VERSION "AEE2010_R3_HS1_HS2_EPS_merge"

NS_ :

BS_:

BU_: UTIL__Traminator CMM___Motor_SG CDS___Fahrdynamikregelung BVA___Automatikgetriebe BSI___Kombiinstrument AR2S_StartStop ABS___Antiblockiersystem AVAS RITCS PASS_HCU2 BVN EBB PASS_VCU BSI AAS PASS_BSI FAMILLE_DSG BV CAPT_ALG CAPT_VOL CMM CSS FSE OUTIL_DIAG PROJ SBW SCDT SUSP UC_DIRA UC_FREIN ASR ARTIV PASS_BSM CMF HCU1 HCU2 ECR MCM Tester PSCM
; #############################################################################
; ############################### HS1 B0 #####################################
; #############################################################################

BO_ 1074 HS2_DAT_BSI_432: 8 BSI
 SG_ ENGINE_COUPLE_REQUEST : 1|2@0+ (1,0) [0|3] "" CAPT_ALG,BVN,ARTIV,ASR,AVAS
 # Description: Requests engine torque coupling or decoupling.
 SG_ STARTER_STOP_REQUEST : 2|1@0+ (1,0) [0|1] "" CAPT_ALG,BVN,ARTIV,ASR,AVAS
 # Description: Requests stopping the starter operation.
 SG_ WAKEUP_CH : 3|1@0+ (1,0) [0|1] "" CAPT_ALG,BVN,ARTIV,ASR,AVAS
 # Description: Triggers a wakeup on channel CH for advanced readiness.
 SG_ ANTICIPATION_ADC_WAKEUP : 4|1@0+ (1,0) [0|1] "" CAPT_ALG,BVN,ARTIV,ASR,AVAS
 # Description: Wakeup triggered by the ADC in anticipation mode.
 SG_ GEARBOX_STATE_WAKEUP : 5|1@0+ (1,0) [0|1] "" CAPT_ALG,BVN,ARTIV,ASR,AVAS
 # Description: Wakeup triggered by a gearbox state change.
 SG_ MAIN_WAKEUP : 7|2@0+ (1,0) [0|3] "" CAPT_ALG,BVN,ARTIV,ASR,AVAS
 # Description: Represents the main wakeup reason or source.
 SG_ PROCESS_COUNTER_4B_BSI_1 : 11|4@0+ (1,0) [0|15] "" CAPT_ALG,BVN,ARTIV,ASR,AVAS
 # Description: Process counter for BSI 1 data frame.
 SG_ SEV_DEMAND : 13|2@0+ (1,0) [0|3] "" CAPT_ALG,BVN,ARTIV,ASR,AVAS
 # Description: Demand for the SEV (Starter-Enabled Vehicle) function.
 SG_ FLEX_PREHEAT_WAKEUP : 16|1@0+ (1,0) [0|1] "" CAPT_ALG,BVN,ARTIV,ASR,AVAS
 # Description: Wakeup triggered by flex fuel preheating logic.
 SG_ PRE_PST_PPL_WAKEUP : 17|1@0+ (1,0) [0|1] "" CAPT_ALG,BVN,ARTIV,ASR,AVAS
 # Description: Wakeup requested for pre/post fuel supply checks.
 SG_ PST_PPL_WAKEUP : 18|1@0+ (1,0) [0|1] "" CAPT_ALG,BVN,ARTIV,ASR,AVAS
 # Description: Wakeup requested for PST (post start) or PPL (pump logic).
 SG_ SENSIBLE_CONSUMPTION : 19|1@0+ (1,0) [0|1] "" CAPT_ALG,BVN,ARTIV,ASR,AVAS
 # Description: Indicates a state of high energy consumption considered sensible.
 SG_ HADC_ENABLE_REQUEST : 20|1@0+ (1,0) [0|1] "" CAPT_ALG,BVN,ARTIV,ASR,AVAS
 # Description: Request to enable the Hill Assist or Descent Control system.
 SG_ ENGINE_PREPARATION_REQUEST : 21|1@0+ (1,0) [0|1] "" CAPT_ALG,BVN,ARTIV,ASR,AVAS
 # Description: Requests engine preparation or readiness mode.
 SG_ IMPULSE_START_REQUEST_BSI : 23|2@0+ (1,0) [0|3] "" CAPT_ALG,BVN,ARTIV,ASR,AVAS
 # Description: Impulse-based engine start request from the BSI.
 SG_ ADDED_FUEL_VOLUME : 31|8@0+ (0.5,0) [0|126.5] "L" CAPT_ALG,BVN,ARTIV,ASR,AVAS
 # Description: Volume of fuel added to the tank, in liters.
 SG_ CORRECT_HIGH_TIRE_PRESS_WAKEUP : 32|1@0+ (1,0) [0|1] "" CAPT_ALG,BVN,ARTIV,ASR,AVAS
 # Description: Wakeup triggered for high tire pressure correction.
 SG_ STT_PREPARATION_WAKEUP : 33|1@0+ (1,0) [0|1] "" CAPT_ALG,BVN,ARTIV,ASR,AVAS
 # Description: Wakeup triggered for start-stop preparation.
 SG_ FSE_STATE_WAKEUP : 34|1@0+ (1,0) [0|1] "" CAPT_ALG,BVN,ARTIV,ASR,AVAS
 # Description: Wakeup triggered by the FSE (Fuel System Electronics) state.
 SG_ HEADLAMP_REQUEST : 35|1@0+ (1,0) [0|1] "" CAPT_ALG,BVN,ARTIV,ASR,AVAS
 # Description: Request for headlamp alignment or activation from the BSI.
 SG_ OIL_MEAS_WAKEUP : 36|1@0+ (1,0) [0|1] "" CAPT_ALG,BVN,ARTIV,ASR,AVAS
 # Description: Wakeup triggered for an oil measurement routine.
 SG_ OVERLOAD_VEHICLE_WAKEUP : 37|1@0+ (1,0) [0|1] "" CAPT_ALG,BVN,ARTIV,ASR,AVAS
 # Description: Indicates wakeup from an overload or high-load vehicle condition.
 SG_ ENGINE_PREPARE_DEM_WAKEUP : 38|1@0+ (1,0) [0|1] "" CAPT_ALG,BVN,ARTIV,ASR,AVAS
 # Description: Wakeup triggered to prepare the engine for immediate start.
 SG_ VVH_UCFREIN_WAKEUP : 39|1@0+ (1,0) [0|1] "" CAPT_ALG,BVN,ARTIV,ASR,AVAS
 # Description: Wakeup triggered for the brake control logic or VVH signals.
 SG_ ADDED_FUEL_VOLUME_COUNTER : 42|3@0+ (1,0) [0|6] "" CAPT_ALG,BVN,ARTIV,ASR,AVAS
 # Description: Counter incremented each time fuel is added.
 SG_ START_DEMAND_STATUS : 43|1@0+ (1,0) [0|1] "" CAPT_ALG,BVN,ARTIV,ASR,AVAS
 # Description: Indicates if an engine start is demanded by the system.
 SG_ UCAPS_PREHEAT_WAKEUP : 45|1@0+ (1,0) [0|1] "" CAPT_ALG,BVN,ARTIV,ASR,AVAS
 # Description: Wakeup triggered by ultracapacitor preheating logic.
 SG_ POST_ENGINE_VENTIL_WAKEUP : 46|1@0+ (1,0) [0|1] "" CAPT_ALG,BVN,ARTIV,ASR,AVAS
 # Description: Wakeup triggered to continue ventilation after engine off.
 SG_ GEP_PREPARATION_WAKEUP : 47|1@0+ (1,0) [0|1] "" CAPT_ALG,BVN,ARTIV,ASR,AVAS
 # Description: Wakeup for GEP (Gas Exhaust Purge) or related function.
 SG_ SEV_MAIN_STATE : 49|2@0+ (1,0) [0|3] "" CAPT_ALG,BVN,ARTIV,ASR,AVAS
 # Description: Main state for the SEV logic or function.
 SG_ CTX_JDD : 55|6@0+ (1,0) [0|0] "" CAPT_ALG,BVN,ARTIV,ASR,AVAS
 # Description: Context flags for JDD (jour du diagnostic or day-of-diagnostic).
 SG_ GENERIC_START_INTENT : 57|2@0+ (1,0) [0|3] "" CAPT_ALG,BVN,ARTIV,ASR,AVAS
 # Description: Generic indication of an intent to start the engine or system.
 SG_ ECO_PUSH_PWT : 58|1@0+ (1,0) [0|1] "" CAPT_ALG,BVN,ARTIV,ASR,AVAS
 # Description: Indicates a push for eco or powertrain optimization features.
 SG_ POWER_LATCH_HYB_WAKEUP : 59|1@0+ (1,0) [0|1] "" CAPT_ALG,BVN,ARTIV,ASR,AVAS
 # Description: Wakeup triggered by a power latch or lock condition in a hybrid system.
 SG_ ELECTRICAL_NETWORK_STATE : 63|4@0+ (1,0) [0|15] "" CAPT_ALG,BVN,ARTIV,ASR,AVAS
 # Description: Current state of the electrical network within the vehicle.

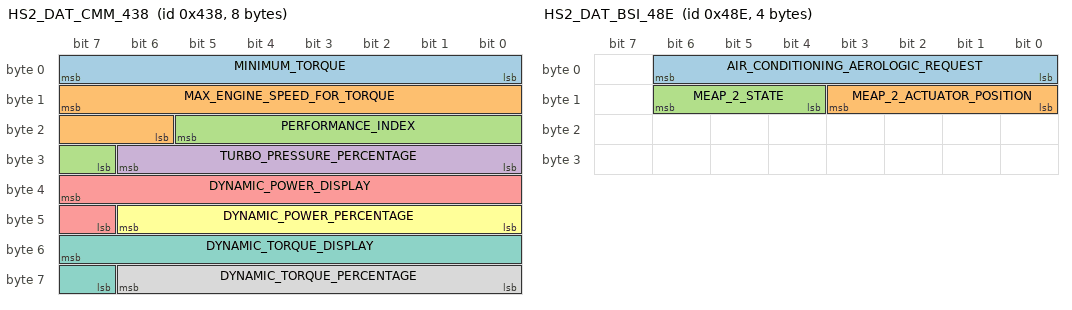
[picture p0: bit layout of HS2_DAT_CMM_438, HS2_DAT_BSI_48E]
BO_ 1080 HS2_DAT_CMM_438: 8 CMM
 SG_ MINIMUM_TORQUE : 7|8@0+ (2,-100) [-100|408] "N.m" RITCS,BV,BSI
 # Description: Minimum permissible engine or motor torque at this time.
 SG_ MAX_ENGINE_SPEED_FOR_TORQUE : 15|10@0+ (10,0) [0|6000] "tr/min" RITCS,BV,BSI
 # Description: Engine speed above which torque might be limited, in rpm.
 SG_ PERFORMANCE_INDEX : 21|7@0+ (1,0) [0|100] "%" RITCS,BV,BSI
 # Description: Performance index summarizing the available power or torque.
 SG_ TURBO_PRESSURE_PERCENTAGE : 30|7@0+ (1,0) [0|100] "%" RITCS,BV,BSI
 # Description: Percentage of the turbo or boost pressure being used.
 SG_ DYNAMIC_POWER_DISPLAY : 39|9@0+ (1,0) [0|400] "ch" RITCS,BV,BSI
 # Description: Display value for dynamic engine power in horsepower.
 SG_ DYNAMIC_POWER_PERCENTAGE : 46|7@0+ (1,0) [0|100] "%" RITCS,BV,BSI
 # Description: Percentage of the dynamic power currently delivered.
 SG_ DYNAMIC_TORQUE_DISPLAY : 55|9@0+ (1,0) [0|500] "N.m" RITCS,BV,BSI
 # Description: Display value for dynamic engine torque in Newton-meters.
 SG_ DYNAMIC_TORQUE_PERCENTAGE : 62|7@0+ (1,0) [0|100] "%" RITCS,BV,BSI
 # Description: Percentage of the dynamic torque relative to maximum output.

BO_ 1106 HS2_DAT_MDD_CMD_452: 6 BSI
 SG_ LONGITUDINAL_REGULATION_TYPE : 1|2@0+ (1,0) [0|3] "" CMF,ARTIV,CMM,UC_FREIN
 # Description: Type of longitudinal regulation (Cruise, ACC, etc.).
 SG_ TURN_SIGNALS_STATE : 5|2@0+ (1,0) [0|3] "" CMF,ARTIV,CMM,UC_FREIN
 # Description: Current state of the left/right turn signals.
 SG_ FRONT_WIPER_STATE : 7|2@0+ (1,0) [0|3] "" CMF,ARTIV,CMM,UC_FREIN
 # Description: Current state of the front wiper system.
 SG_ SPEED_LIMIT_CONSIGN : 15|8@0+ (1,0) [0|255] "km/h" CMF,ARTIV,CMM,UC_FREIN
 # Description: Speed limit value or setpoint for the vehicle.
 SG_ RVV_LVV_CHECKSUM : 17|2@0+ (1,0) [0|3] "" CMF,ARTIV,CMM,UC_FREIN
 # Description: 2-bit checksum for the RVV/LVV data consistency.
 SG_ BSI_FREIN_ONLY_REQUEST : 18|1@0+ (1,0) [0|1] "" CMF,ARTIV,CMM,UC_FREIN
 # Description: Indicates if the BSI is requesting brake-only actuation.
 SG_ LVV_ACTIVATION_REQUEST : 22|1@0+ (1,0) [0|1] "" CMF,ARTIV,CMM,UC_FREIN
 # Description: Request to activate LVV (low-voltage valve or logic).
 SG_ RVV_ACC_ACTIVATION_REQUEST : 23|1@0+ (1,0) [0|1] "" CMF,ARTIV,CMM,UC_FREIN
 # Description: Request to activate RVV (regulation of variable valve) with ACC.
 SG_ ARC_SENSITIVITY_HABIT : 26|3@0+ (1,0) [0|7] "" CMF,ARTIV,CMM,UC_FREIN
 # Description: Sensitivity setting for ARC from the user habit or preference.
 SG_ ARC_ACTIVATION_REQUEST_HABIT : 27|1@0+ (1,0) [0|1] "" CMF,ARTIV,CMM,UC_FREIN
 # Description: Requests activation of ARC based on user preference.
 SG_ BSI2_COUNTER : 31|4@0+ (1,0) [0|15] "" CMF,ARTIV,CMM,UC_FREIN
 # Description: Transmission counter for the second set of BSI signals.
 SG_ FRONT_WASHER_STATE : 32|1@0+ (1,0) [0|1] "" CMF,ARTIV,CMM,UC_FREIN
 # Description: Indicates if the front washer system is active.
 SG_ FA_ACTIVATION_REQUEST_HABIT : 33|1@0+ (1,0) [0|1] "" CMF,ARTIV,CMM,UC_FREIN
 # Description: Requests activation of the forward assist function by the user.
 SG_ TIME_GAP_CONSIGN : 39|6@0+ (0.1,0) [0|6.1] "s" CMF,ARTIV,CMM,UC_FREIN
 # Description: Time gap setpoint for adaptive cruise or spacing.
 SG_ CHECKSUM_FRAME_4B_452 : 43|4@0+ (1,0) [0|15] "" CMF,ARTIV,CMM,UC_FREIN
 # Description: 4-bit checksum for frame 452 data.
 SG_ GO_ACC_REQUEST : 45|1@0+ (1,0) [0|1] "" CMF,ARTIV,CMM,UC_FREIN
 # Description: Indicates a user or system request to resume ACC from a stop.
 SG_ ACC_PROGRAM : 47|2@0+ (1,0) [0|3] "" CMF,ARTIV,CMM,UC_FREIN
 # Description: Program or mode selection for ACC.

BO_ 1160 HS2_BGE_DAT_CMM_488: 8 PASS_BSI
 SG_ ENGINE_COOLANT_TEMPERATURE : 7|8@0+ (1,-40) [-40|214] "Degré C" PASS_HCU2,RITCS,UC_FREIN,CSS,BV,BSI,HCU1
 # Description: Temperature of the engine coolant in degrees Celsius.
 SG_ FUEL_CONSUMPTION_VOLUME : 15|8@0+ (80,0) [0|20400] "mm3" PASS_HCU2,RITCS,UC_FREIN,CSS,BV,BSI,HCU1
 # Description: Volume of fuel consumed, in mm³, since last reset or measurement.
 SG_ IDLE_REGULATION_SETPOINT : 23|8@0+ (8,0) [0|2024] "tr/min" PASS_HCU2,RITCS,UC_FREIN,CSS,BV,BSI,HCU1
 # Description: Idle engine speed setpoint in rpm.
 SG_ START_IN_PROGRESS : 24|1@0+ (1,0) [0|0] "" PASS_HCU2,RITCS,UC_FREIN,CSS,BV,BSI,HCU1
 # Description: Indicates if an engine start is currently in progress.
 SG_ PREHEAT_LAMP_REQUEST : 25|1@0+ (1,0) [0|0] "" PASS_HCU2,RITCS,UC_FREIN,CSS,BV,BSI,HCU1
 # Description: Requests illumination of the glow plug (preheat) indicator lamp.
 SG_ MIL_LAMP_REQUEST : 26|1@0+ (1,0) [0|0] "" PASS_HCU2,RITCS,UC_FREIN,CSS,BV,BSI,HCU1
 # Description: Requests illumination of the MIL (Malfunction Indicator Lamp).
 SG_ HIGH_COOLANT_TEMPERATURE_ALERT : 27|1@0+ (1,0) [0|0] "" PASS_HCU2,RITCS,UC_FREIN,CSS,BV,BSI,HCU1
 # Description: Indicates an alert for excessively high coolant temperature.
 SG_ LOW_ADDITIVE_LEVEL_ALERT : 28|1@0+ (1,0) [0|0] "" PASS_HCU2,RITCS,UC_FREIN,CSS,BV,BSI,HCU1
 # Description: Signals a low additive (e.g., DEF fluid) level condition.
 SG_ PVRE_MILEAGE_LAMP_REQUEST : 28|1@0+ (1,0) [0|0] "" PASS_HCU2,RITCS,UC_FREIN,CSS,BV,BSI,HCU1
 # Description: Requests illumination of the mileage lamp when nearing fill requirement.
 SG_ RVV_LVV_FAULT : 30|1@0+ (1,0) [0|0] "" PASS_HCU2,RITCS,UC_FREIN,CSS,BV,BSI,HCU1
 # Description: Indicates a detected fault in the RVV/LVV system.
 SG_ COMBUSTION_RATES : 31|1@0+ (1,0) [0|0] "" PASS_HCU2,RITCS,UC_FREIN,CSS,BV,BSI,HCU1
 # Description: Monitors or indicates the combustion rates or events per cycle.
 SG_ SECURE_AC_COUPLING : 32|1@0+ (1,0) [0|0] "" PASS_HCU2,RITCS,UC_FREIN,CSS,BV,BSI,HCU1
 # Description: Indicates the AC clutch or coupling is secured or locked for safety.
 SG_ CLIMATE_CONTROL_MANAGEMENT_STATE : 34|2@0+ (1,0) [0|0] "" PASS_HCU2,RITCS,UC_FREIN,CSS,BV,BSI,HCU1
 # Description: State variable for internal climate control management.
 SG_ SERVICE_STOP_LAMP_REQUEST : 36|2@0+ (1,0) [0|0] "" PASS_HCU2,RITCS,UC_FREIN,CSS,BV,BSI,HCU1
 # Description: Requests the service stop lamp or message to be displayed.
 SG_ GLOW_PLUG_PREHEAT_PREP : 37|1@0+ (1,0) [0|0] "" PASS_HCU2,RITCS,UC_FREIN,CSS,BV,BSI,HCU1
 # Description: Indicates preparation phase of the glow plug preheat cycle.
 SG_ FUEL_CONSUMPTION_INFO_TYPE : 37|1@0+ (1,0) [0|0] "" PASS_HCU2,RITCS,UC_FREIN,CSS,BV,BSI,HCU1
 # Description: Type or mode of fuel consumption info being reported.
 SG_ FAP_CLOGGING_RISK : 38|1@0+ (1,0) [0|0] "" PASS_HCU2,RITCS,UC_FREIN,CSS,BV,BSI,HCU1
 # Description: Risk level or indicator for clogged particulate filter.
 SG_ BVA_PRESSURE_OVERRIDE : 39|1@0+ (1,0) [0|0] "" PASS_HCU2,RITCS,UC_FREIN,CSS,BV,BSI,HCU1
 # Description: Indicates an override of gearbox pressure in the automatic transmission.
 SG_ ENGINE_OIL_TEMP : 47|8@0+ (1,-40) [-40|214] "Degrees C" PASS_HCU2,RITCS,UC_FREIN,CSS,BV,BSI,HCU1
SG_ COOLANT_PRESSURE : 55|8@0+ (25,0) [100|3100] "kPa" PASS_HCU2,RITCS,UC_FREIN,CSS,BV,BSI,HCU1
# Description: Represents the coolant system pressure in kilopascals (kPa). Typically measured by a pressure sensor.

SG_ ENGINE_AIR_TEMPERATURE : 63|8@0+ (1,-40) [-40|214] "Degree C" PASS_HCU2,RITCS,UC_FREIN,CSS,BV,BSI,HCU1
# Description: Represents the intake air temperature of the engine in degrees Celsius.

BO_ 1166 HS2_DAT_BSI_48E: 4 BSI
 SG_ AIR_CONDITIONING_AEROLOGIC_REQUEST : 6|7@0+ (1,0) [0|100] "%" CMM
# Description: Represents an aerodynamic-related request for the air conditioning system.

 SG_ MEAP_2_ACTUATOR_POSITION : 11|4@0+ (1,0) [0|0] "" CMM
# Description: Represents the commanded position of the second MEAP actuator (Manifold/Electronic Actuator).

 SG_ MEAP_2_STATE : 14|3@0+ (1,0) [0|0] "" CMM
# Description: Represents the current operating state of the second MEAP actuator.

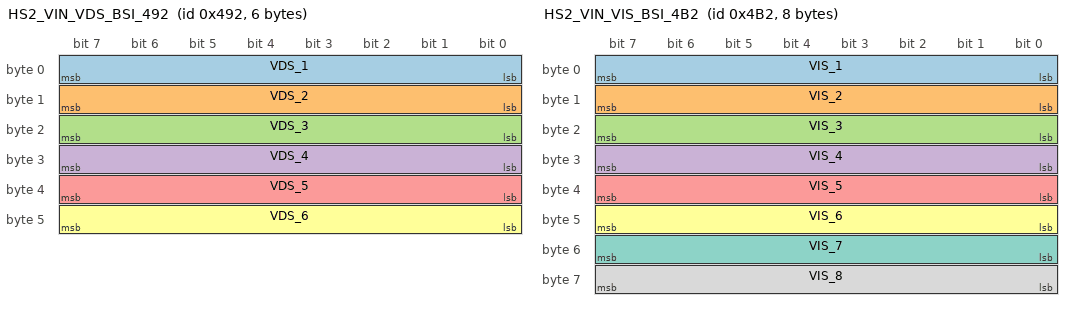
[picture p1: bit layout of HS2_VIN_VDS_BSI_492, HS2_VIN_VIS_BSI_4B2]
BO_ 1170 HS2_VIN_VDS_BSI_492: 6 BSI
 SG_ VDS_1 : 7|8@0+ (1,0) [0|0] "" BVN,CMM
# Description: First character of the Vehicle Descriptor Section (VDS).

 SG_ VDS_2 : 15|8@0+ (1,0) [0|0] "" BVN,CMM
# Description: Second character of the Vehicle Descriptor Section (VDS).

 SG_ VDS_3 : 23|8@0+ (1,0) [0|0] "" BVN,CMM
# Description: Third character of the Vehicle Descriptor Section (VDS).

 SG_ VDS_4 : 31|8@0+ (1,0) [0|0] "" BVN,CMM
# Description: Fourth character of the Vehicle Descriptor Section (VDS).

 SG_ VDS_5 : 39|8@0+ (1,0) [0|0] "" BVN,CMM
# Description: Fifth character of the Vehicle Descriptor Section (VDS).

 SG_ VDS_6 : 47|8@0+ (1,0) [0|0] "" BVN,CMM
# Description: Sixth character of the Vehicle Descriptor Section (VDS).

BO_ 1202 HS2_VIN_VIS_BSI_4B2: 8 BSI
 SG_ VIS_1 : 7|8@0+ (1,0) [0|0] "" CMM,BVN
# Description: First character of the Vehicle Identification Section (VIS).

 SG_ VIS_2 : 15|8@0+ (1,0) [0|0] "" CMM,BVN
# Description: Second character of the Vehicle Identification Section (VIS).

 SG_ VIS_3 : 23|8@0+ (1,0) [0|0] "" CMM,BVN
# Description: Third character of the Vehicle Identification Section (VIS).

 SG_ VIS_4 : 31|8@0+ (1,0) [0|0] "" CMM,BVN
# Description: Fourth character of the Vehicle Identification Section (VIS).

 SG_ VIS_5 : 39|8@0+ (1,0) [0|0] "" CMM,BVN
# Description: Fifth character of the Vehicle Identification Section (VIS).

 SG_ VIS_6 : 47|8@0+ (1,0) [0|0] "" CMM,BVN
# Description: Sixth character of the Vehicle Identification Section (VIS).

 SG_ VIS_7 : 55|8@0+ (1,0) [0|0] "" CMM,BVN
# Description: Seventh character of the Vehicle Identification Section (VIS).

 SG_ VIS_8 : 63|8@0+ (1,0) [0|0] "" CMM,BVN
# Description: Eighth character of the Vehicle Identification Section (VIS).

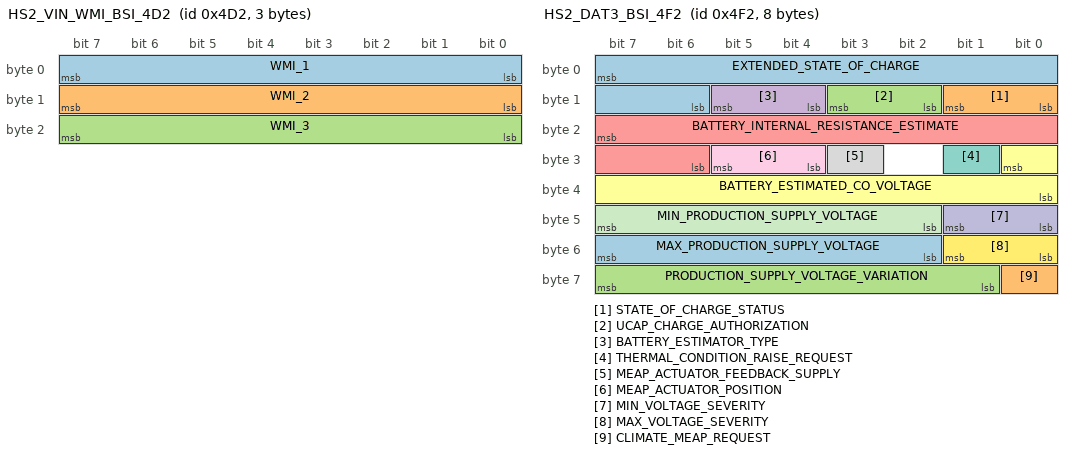
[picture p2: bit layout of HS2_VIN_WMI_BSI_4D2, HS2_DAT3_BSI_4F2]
BO_ 1234 HS2_VIN_WMI_BSI_4D2: 3 BSI
 SG_ WMI_1 : 7|8@0+ (1,0) [0|0] "" BVN,CMM
# Description: First character of the World Manufacturer Identifier (WMI).

 SG_ WMI_2 : 15|8@0+ (1,0) [0|0] "" BVN,CMM
# Description: Second character of the World Manufacturer Identifier (WMI).

 SG_ WMI_3 : 23|8@0+ (1,0) [0|0] "" BVN,CMM
# Description: Third character of the World Manufacturer Identifier (WMI).

BO_ 1261 HS2_DAT_ESP_4ED: 5 UC_FREIN
 SG_ FAULT_OBD_ESP_FRONT_PRESSURE_SENSOR : 0|1@0+ (1,0) [0|0] "" HCU2
# Description: Indicates a fault status for the front pressure sensor used by the ESP system.

 SG_ FAULT_OBD_ESP_TRIPLE_SENSOR_COMM : 8|1@0+ (1,0) [0|0] "" HCU2
# Description: Indicates a communication fault with triple sensors in the ESP system.

 SG_ FAULT_OBD_ESP_CMM_COMM : 9|1@0+ (1,0) [0|0] "" HCU2
# Description: Indicates a communication fault with the CMM in the ESP system.

 SG_ FAULT_OBD_ESP_PTMU_COMM : 10|1@0+ (1,0) [0|0] "" HCU2
# Description: Indicates a communication fault with the PTMU in the ESP system.

 SG_ FAULT_OBD_ESP_VOLUME_SENSOR : 11|1@0+ (1,0) [0|0] "" HCU2
# Description: Indicates a fault with the volume sensor for the ESP system.

 SG_ FAULT_OBD_ESP_VALVE_ESP : 12|1@0+ (1,0) [0|0] "" HCU2
# Description: Indicates a fault with the ESP valve.

 SG_ FAULT_OBD_ESP_PUMP_ESP : 13|1@0+ (1,0) [0|0] "" HCU2
# Description: Indicates a fault with the ESP pump.

 SG_ FAULT_OBD_ESP_MASTERVAC_SENSOR : 14|1@0+ (1,0) [0|0] "" HCU2
# Description: Indicates a fault with the mastervac sensor in the ESP system.

 SG_ FAULT_OBD_ESP_VACUUM_PUMP_SUPERVISION : 15|1@0+ (1,0) [0|0] "" HCU2
# Description: Indicates a fault related to vacuum pump supervision in the ESP system.

 SG_ FAULT_OBD_ESP_CVR_AVG : 16|1@0+ (1,0) [0|0] "" HCU2
# Description: Indicates a fault with the average CVR sensor (front-left corner) in the ESP system.

 SG_ FAULT_OBD_ESP_CVR_AVD : 17|1@0+ (1,0) [0|0] "" HCU2
# Description: Indicates a fault with the CVR sensor (front-right corner) in the ESP system.

 SG_ FAULT_OBD_ESP_CVR_ARG : 18|1@0+ (1,0) [0|0] "" HCU2
# Description: Indicates a fault with the CVR sensor (rear-left corner) in the ESP system.

 SG_ FAULT_OBD_ESP_CVR_ARD : 19|1@0+ (1,0) [0|0] "" HCU2
# Description: Indicates a fault with the CVR sensor (rear-right corner) in the ESP system.

 SG_ FAULT_OBD_ESP_WHEEL_SPEED_SENSOR : 20|1@0+ (1,0) [0|0] "" HCU2
# Description: Indicates a fault in a wheel speed sensor in the ESP system.

 SG_ FAULT_OBD_ESP_BRAKE_CONTACT : 21|1@0+ (1,0) [0|0] "" HCU2
# Description: Indicates a fault with the brake contact signal in the ESP system.

 SG_ FAULT_OBD_ESP_CAN_IS : 22|1@0+ (1,0) [0|0] "" HCU2
# Description: Indicates a CAN IS bus fault for the ESP system.

 SG_ FAULT_OBD_ESP_CAN_LAS : 23|1@0+ (1,0) [0|0] "" HCU2
# Description: Indicates a CAN LAS bus fault for the ESP system.

 SG_ FAULT_OBD_ESP_INTERNAL_ERROR : 24|1@0+ (1,0) [0|0] "" HCU2
# Description: Indicates an internal error in the ESP system.

 SG_ FAULT_OBD_ESP_OVERVOLTAGE : 25|1@0+ (1,0) [0|0] "" HCU2
# Description: Indicates an overvoltage condition in the ESP system.

 SG_ FAULT_OBD_ESP_TELECODING : 26|1@0+ (1,0) [0|0] "" HCU2
# Description: Indicates a telecoding/configuration issue in the ESP system.

 SG_ FAULT_OBD_ESP_MASTER_CYLINDER_SENSOR : 27|1@0+ (1,0) [0|0] "" HCU2
# Description: Indicates a fault with the master cylinder sensor in the ESP system.

 SG_ YAW_RATE_SENSOR_FAULT_RB : 28|1@0+ (1,0) [0|0] "" HCU2
# Description: Indicates a fault in the yaw rate sensor (RB) used by the ESP system.

 SG_ LATERAL_ACCELERATION_SENSOR_FAULT_RB : 29|1@0+ (1,0) [0|0] "" HCU2
# Description: Indicates a fault in the lateral acceleration sensor (RB) for the ESP system.

 SG_ FAULT_OBD_ESP_INERTIAL_SENSOR : 30|1@0+ (1,0) [0|0] "" HCU2
# Description: Indicates a fault in the inertial sensor for the ESP system.

 SG_ FAULT_OBD_ESP_STEERING_WHEEL_SENSOR : 31|1@0+ (1,0) [0|0] "" HCU2
# Description: Indicates a fault in the steering wheel angle sensor for the ESP system.

 SG_ DIAG_ACTIVATION_VACUUM_FAULT : 32|1@0+ (1,0) [0|0] "" HCU2
# Description: Indicates whether vacuum fault diagnosis is active.

 SG_ VACUUM_FAULT_DIAGNOSIS : 33|1@0+ (1,0) [0|0] "" HCU2
# Description: Indicates a detected vacuum fault condition.

BO_ 1266 HS2_DAT3_BSI_4F2: 8 BSI
 SG_ EXTENDED_STATE_OF_CHARGE : 7|10@0+ (0.1,0) [0|100] "%" PASS_HCU2,RITCS,CMM
# Description: Represents the state of charge of the battery in percent, with extended precision.

 SG_ STATE_OF_CHARGE_STATUS : 9|2@0+ (1,0) [0|0] "" PASS_HCU2,RITCS,CMM
# Description: Represents the status level or mode for the battery state of charge.

 SG_ UCAP_CHARGE_AUTHORIZATION : 11|2@0+ (1,0) [0|0] "" PASS_HCU2,RITCS,CMM
# Description: Indicates if ultracapacitor charging is authorized.

 SG_ BATTERY_ESTIMATOR_TYPE : 13|2@0+ (1,0) [0|0] "" PASS_HCU2,RITCS,CMM
# Description: Defines which battery estimator algorithm or type is in use.

 SG_ BATTERY_INTERNAL_RESISTANCE_ESTIMATE : 23|10@0+ (0.01,0) [0|10] "mOhm" PASS_HCU2,RITCS,CMM
# Description: Represents the estimated internal resistance of the battery in milliohms.

 SG_ BATTERY_ESTIMATED_CO_VOLTAGE : 24|9@0+ (0.01,11) [11|14] "V" PASS_HCU2,RITCS,CMM
# Description: Represents the estimated battery voltage offset in volts.

 SG_ THERMAL_CONDITION_RAISE_REQUEST : 25|1@0+ (1,0) [0|0] "" PASS_HCU2,RITCS,CMM
# Description: Requests a thermal condition raise for the engine (e.g., to optimize temperature).

 SG_ MEAP_ACTUATOR_FEEDBACK_SUPPLY : 27|1@0+ (1,0) [0|0] "" PASS_HCU2,RITCS,CMM
# Description: Indicates the supply status used for the MEAP actuator feedback.

 SG_ MEAP_ACTUATOR_POSITION : 29|2@0+ (1,0) [0|0] "" PASS_HCU2,RITCS,CMM
# Description: Represents the position of the MEAP actuator.

 SG_ MIN_VOLTAGE_SEVERITY : 41|2@0+ (1,0) [0|0] "" PASS_HCU2,RITCS,CMM
# Description: Indicates the severity level for the minimum voltage threshold condition.

 SG_ MIN_PRODUCTION_SUPPLY_VOLTAGE : 47|6@0+ (0.1,10.6) [10.6|16] "V" PASS_HCU2,RITCS,CMM
# Description: Represents the minimum supply voltage for onboard electric production.

 SG_ MAX_VOLTAGE_SEVERITY : 49|2@0+ (1,0) [0|0] "" PASS_HCU2,RITCS,CMM
# Description: Indicates the severity level for the maximum voltage threshold condition.

 SG_ MAX_PRODUCTION_SUPPLY_VOLTAGE : 55|6@0+ (0.1,10.6) [10.6|16] "V" PASS_HCU2,RITCS,CMM
# Description: Represents the maximum supply voltage for onboard electric production.

 SG_ CLIMATE_MEAP_REQUEST : 56|1@0+ (1,0) [0|0] "" PASS_HCU2,RITCS,CMM
# Description: Indicates a request to adjust MEAP for climate control.

 SG_ PRODUCTION_SUPPLY_VOLTAGE_VARIATION : 63|7@0+ (0.1,0) [0.1|10] "V/s" PASS_HCU2,RITCS,CMM
# Description: Represents the variation rate of the supply voltage in volts per second.

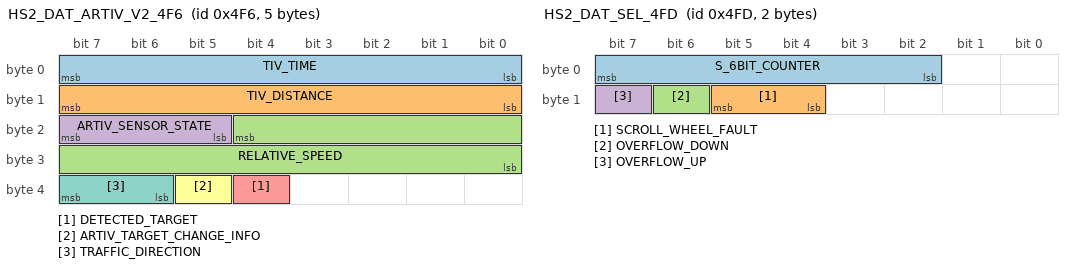
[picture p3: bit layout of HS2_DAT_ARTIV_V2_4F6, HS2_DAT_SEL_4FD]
BO_ 1270 HS2_DAT_ARTIV_V2_4F6: 5 ARTIV
 SG_ TIV_TIME : 7|8@0+ (0.1,0) [0|25.4] "s" RITCS,BSI,CMF
# Description: Represents the Time to Impact Value (TIV) in seconds.

 SG_ TIV_DISTANCE : 15|8@0+ (1,0) [0|253] "m" RITCS,BSI,CMF
# Description: Represents the distance to the target object used for ARTIV, in meters.

 SG_ RELATIVE_SPEED : 20|13@0+ (0.02,-70) [-70|70] "m/s" RITCS,BSI,CMF
# Description: Represents the relative speed between the host vehicle and a target in meters per second.

 SG_ ARTIV_SENSOR_STATE : 23|3@0+ (1,0) [0|0] "" RITCS,BSI,CMF
# Description: Represents the operating state of the ARTIV sensor module.

 SG_ DETECTED_TARGET : 36|1@0+ (1,0) [0|0] "" RITCS,BSI,CMF
# Description: Indicates whether a target has been detected.

 SG_ ARTIV_TARGET_CHANGE_INFO : 37|1@0+ (1,0) [0|0] "" RITCS,BSI,CMF
# Description: Indicates a change or update in the detected target data.

 SG_ TRAFFIC_DIRECTION : 39|2@0+ (1,0) [0|0] "" RITCS,BSI,CMF
# Description: Indicates the direction of traffic or lane movement for ARTIV.

BO_ 1277 HS2_DAT_SEL_4FD: 2 MCM
 SG_ S_6BIT_COUNTER : 7|6@0- (1,0) [-32|31] "" UC_FREIN
# Description: 6-bit counter for a selection or incremental count function.

 SG_ SCROLL_WHEEL_FAULT : 13|2@0+ (1,0) [0|0] "" UC_FREIN
# Description: Indicates a fault in the scroll wheel or rotary switch mechanism.

 SG_ OVERFLOW_DOWN : 14|1@0+ (1,0) [0|0] "" UC_FREIN
# Description: Indicates a downward overflow condition in the scroll or selection function.

 SG_ OVERFLOW_UP : 15|1@0+ (1,0) [0|0] "" UC_FREIN
# Description: Indicates an upward overflow condition in the scroll or selection function.

BO_ 1294 HS2_DAT_CLIM_50E: 8 BSI
 SG_ COMPRESSOR_CLUTCH_STATE : 1|1@0+ (1,0) [0|1] "" PASS_HCU2,RITCS,UC_FREIN,SCDT,CMM,BV
# Description: Represents the engaged or disengaged state of the air conditioning compressor clutch.

 SG_ AUTHORIZED_ENGINE_STOP_IN_CABIN : 2|1@0+ (1,0) [0|1] "" PASS_HCU2,RITCS,UC_FREIN,SCDT,CMM,BV
# Description: Indicates whether engine stop is authorized for cabin conditions (e.g. climate control).

 SG_ HABITACLE_ID_FAULT : 2|1@0+ (1,0) [0|1] "" PASS_HCU2,RITCS,UC_FREIN,SCDT,CMM,BV
# Description: Indicates a fault in the cabin identification or detection system.

 SG_ MIN_GPL : 3|1@0+ (1,0) [0|1] "" PASS_HCU2,RITCS,UC_FREIN,SCDT,CMM,BV
# Description: Represents a minimum GPL (liquefied petroleum gas) threshold condition if applicable.

 SG_ CONS_RVV_LVV_CHECKSUM : 5|2@0+ (1,0) [0|3] "" PASS_HCU2,RITCS,UC_FREIN,SCDT,CMM,BV
# Description: Checksum to secure the RVV or LVV speed request.

 SG_ CLIMATE_FAN_CONTROL_REQUEST : 13|6@0+ (2,0) [0|110] "%" PASS_HCU2,RITCS,UC_FREIN,SCDT,CMM,BV
# Description: Represents the climate system fan control request as a percentage.

 SG_ FAN_REQUEST_COMMAND : 15|2@0+ (1,0) [0|3] "" PASS_HCU2,RITCS,UC_FREIN,SCDT,CMM,BV
# Description: Represents a direct fan speed command or setting.

 SG_ GLOW_PLUGS_FORCING : 17|1@0+ (1,0) [0|1] "" PASS_HCU2,RITCS,UC_FREIN,SCDT,CMM,BV
# Description: Forces glow plugs to activate, typically to increase engine load for certain conditions (e.g. DPF regeneration).

 SG_ LOAD_SHEDDING_LEVEL : 19|1@0+ (1,0) [0|1] "" PASS_HCU2,RITCS,UC_FREIN,SCDT,CMM,BV
# Description: Indicates the load shedding level for major electrical consumers.

 SG_ RESTART_REQUEST_CABIN : 23|1@0+ (1,0) [0|1] "" PASS_HCU2,RITCS,UC_FREIN,SCDT,CMM,BV
# Description: Signals a request to restart the engine from cabin conditions (climate demands, etc.).

 SG_ REQUEST_ENGINE_RESTART_HABITACLE : 23|2@0+ (1,0) [0|3] "" PASS_HCU2,RITCS,UC_FREIN,SCDT,CMM,BV
# Description: Detailed request for engine restart from the cabin environment.

 SG_ PRESSURE_CONDENSER : 26|2@0+ (1,0) [0|3] "" PASS_HCU2,RITCS,UC_FREIN,SCDT,CMM,BV
# Description: Represents the condenser pressure state for the AC system.

 SG_ ENGINE_STOP_INHIBIT_HABITACLE : 29|2@0+ (1,0) [0|3] "" PASS_HCU2,RITCS,UC_FREIN,SCDT,CMM,BV
# Description: Indicates conditions inhibiting engine stop due to cabin constraints.

 SG_ HABITACLE_REQUEST_SIGNAL : 31|1@0+ (1,0) [0|1] "" PASS_HCU2,RITCS,UC_FREIN,SCDT,CMM,BV
# Description: Represents a cabin request for additional resources or engine operation.

 SG_ MECHANICAL_POWER_CONSUMPTION_CLIMATE : 39|8@0+ (25,0) [0|6350] "W" PASS_HCU2,RITCS,UC_FREIN,SCDT,CMM,BV
# Description: Indicates the mechanical power drawn by the climate compressor in watts.

 SG_ INCREASED_IDLE_SPEED_REQUEST : 47|8@0+ (8,0) [0|2032] "tr/min" PASS_HCU2,RITCS,UC_FREIN,SCDT,CMM,BV
# Description: Represents a requested higher idle speed for climate or other demands, in revolutions per minute.

 SG_ SPEED_LIMIT_REQUEST : 55|8@0+ (1,0) [0|255] "km/h" PASS_HCU2,RITCS,UC_FREIN,SCDT,CMM,BV
# Description: Represents a requested speed limit for the vehicle in km/h.

 SG_ BSI_FRAME_COUNTER : 59|4@0+ (1,0) [0|15] "" PASS_HCU2,RITCS,UC_FREIN,SCDT,CMM,BV
# Description: Frame counter used for data consistency checks in BSI communications.

 SG_ LVV_ACTIVATION_REQUEST : 60|1@0+ (1,0) [0|1] "" PASS_HCU2,RITCS,UC_FREIN,SCDT,CMM,BV
# Description: Indicates a request to activate the Low-Speed Vehicle (LVV) function.

 SG_ LONGITUDINAL_REGULATION_TYPE : 62|2@0+ (1,0) [0|3] "" PASS_HCU2,RITCS,UC_FREIN,SCDT,CMM,BV
# Description: Defines whether the vehicle is in LVV, RVV, ACC, or no longitudinal regulation mode.

 SG_ RVV_ACC_ACTIVATION_REQUEST : 63|1@0+ (1,0) [0|1] "" PASS_HCU2,RITCS,UC_FREIN,SCDT,CMM,BV
# Description: Indicates a request to activate the RVV or ACC function.

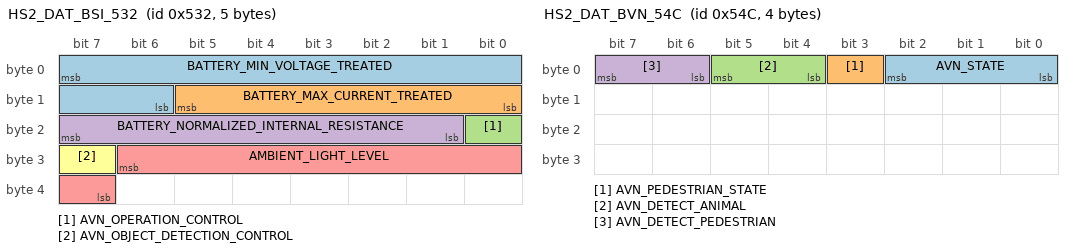
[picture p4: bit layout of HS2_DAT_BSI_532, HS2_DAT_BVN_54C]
BO_ 1330 HS2_DAT_BSI_532: 5 BSI
 SG_ BATTERY_MIN_VOLTAGE_TREATED : 7|10@0+ (0.01,3) [3|13] "V" PASS_HCU2,CMM,BVN
# Description: Represents the processed minimum battery voltage in volts.

 SG_ BATTERY_MAX_CURRENT_TREATED : 13|6@0+ (20,-1500) [-1500|-300] "A" PASS_HCU2,CMM,BVN
# Description: Represents the maximum treated battery current in amperes (A).

 SG_ AVN_OPERATION_CONTROL : 16|1@0+ (1,0) [0|0] "" PASS_HCU2,CMM,BVN
# Description: Represents the control bit for AVN (audio/video/navigation) operation.

 SG_ BATTERY_NORMALIZED_INTERNAL_RESISTANCE : 23|7@0+ (0.1,0) [0|10] "mOhm" PASS_HCU2,CMM,BVN
# Description: Represents the normalized internal resistance of the battery in milliohms.

 SG_ AMBIENT_LIGHT_LEVEL : 30|8@0+ (1,0) [0|254] "" PASS_HCU2,CMM,BVN
# Description: Represents the measured ambient light level.

 SG_ AVN_OBJECT_DETECTION_CONTROL : 31|1@0+ (1,0) [0|0] "" PASS_HCU2,CMM,BVN
# Description: Represents an AVN control bit for object detection.

BO_ 1356 HS2_DAT_BVN_54C: 4 BVN
 SG_ AVN_STATE : 2|3@0+ (1,0) [0|0] "" BSI
# Description: Represents the overall state of the AVN (audio/video/navigation) system.

 SG_ AVN_PEDESTRIAN_STATE : 3|1@0+ (1,0) [0|0] "" BSI
# Description: Indicates the pedestrian-related state within the AVN system.

 SG_ AVN_DETECT_ANIMAL : 5|2@0+ (1,0) [0|0] "" BSI
# Description: Indicates whether an animal has been detected by the AVN system.

 SG_ AVN_DETECT_PEDESTRIAN : 7|2@0+ (1,0) [0|0] "" BSI
# Description: Indicates whether a pedestrian has been detected by the AVN system.
;TODO
;BO_ 1362 HS2_DAT4_V2_BSI_552: 8 BSI
; SG_ CPT_TEMPOREL : 7|32@0+ (0.1,0) [0|429496729.3] "s" BVN,ARTIV,EBB,AVAS
; SG_ KILOMETRAGE : 39|24@0+ (1,0) [0|16777214] "km" BVN,ARTIV,EBB,AVAS
; SG_ COMPTEUR_RAZ_GCT : 63|8@0+ (1,0) [0|253] "" BVN,ARTIV,EBB,AVAS
;TODO
;BO_ 1375 HS2_DAT4_V2_BSI_552: 8 BSI
; SG_ DATA_ACQ_JDD_BSI_2 : 7|8@0+ (1,0) [0|0] "" BVN,CAPT_ALG,MCM,ARTIV

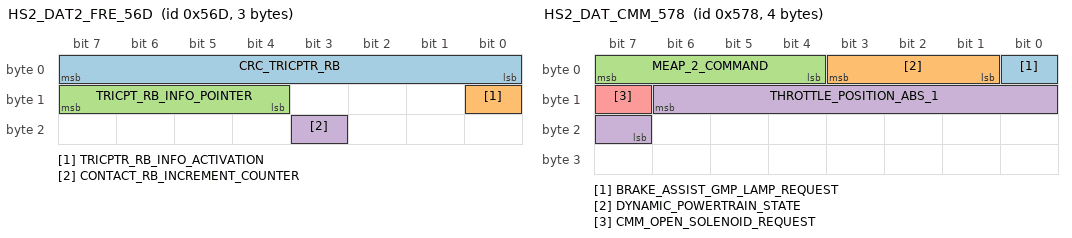
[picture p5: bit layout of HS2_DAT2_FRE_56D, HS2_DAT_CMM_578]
BO_ 1389 HS2_DAT2_FRE_56D: 3 UC_FREIN
 SG_ CRC_TRICPTR_RB : 7|8@0+ (1,0) [0|255] "" CAPT_ALG
# Description: Represents the CRC for the tricapteur data (rear brake) sensor communications.

 SG_ TRICPTR_RB_INFO_ACTIVATION : 8|1@0+ (1,0) [0|0] "" CAPT_ALG
# Description: Indicates whether tricapteur RB information is active or valid.

 SG_ TRICPT_RB_INFO_POINTER : 15|4@0+ (1,0) [0|0] "" CAPT_ALG
# Description: Holds a pointer/index for the tricapteur RB data information.

 SG_ CONTACT_RB_INCREMENT_COUNTER : 19|1@0+ (1,0) [0|0] "" CAPT_ALG
# Description: Represents a counter increment for contact events in the rear brake sensor (RB).

BO_ 1393 HS2_AVAS_571: 1 AVAS
 SG_ FAULT_AUDIBLE_VEHICLE_SILENT_WARNING : 6|1@0+ (1,0) [0|0] "" BSI
# Description: Indicates a fault in the audible alert system for silent vehicles (AVAS).

 SG_ AUDIBLE_VEHICLE_SILENT_WARNING_STATE : 7|1@0+ (1,0) [0|0] "" BSI
# Description: Represents the state of the silent vehicle audible alert system (AVAS).

BO_ 1400 HS2_DAT_CMM_578: 4 CMM
 SG_ BRAKE_ASSIST_GMP_LAMP_REQUEST : 0|1@0+ (1,0) [0|0] "" BV,BSI
# Description: Indicates a request to illuminate a brake-assist or powertrain-related lamp.

 SG_ DYNAMIC_POWERTRAIN_STATE : 3|3@0+ (1,0) [0|0] "" BV,BSI
# Description: Represents the dynamic state of the powertrain.

 SG_ MEAP_2_COMMAND : 7|4@0+ (1,0) [0|0] "" BV,BSI
# Description: Represents a command to the second MEAP actuator.

 SG_ THROTTLE_POSITION_ABS_1 : 14|8@0+ (0.39216,0) [0|100] "%" BV,BSI
# Description: Represents the absolute position of throttle sensor 1 as a percentage.

 SG_ CMM_OPEN_SOLENOID_REQUEST : 15|1@0+ (1,0) [0|0] "" BV,BSI
# Description: Indicates a request from CMM to open a solenoid.

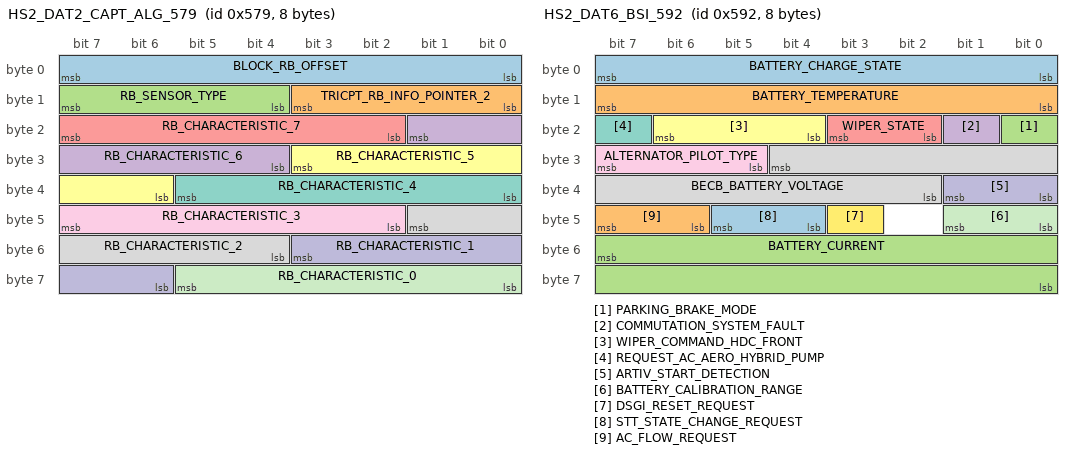
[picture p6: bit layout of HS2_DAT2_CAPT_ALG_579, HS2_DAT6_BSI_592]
BO_ 1401 HS2_DAT2_CAPT_ALG_579: 8 CAPT_ALG
 SG_ BLOCK_RB_OFFSET : 7|8@0+ (1,0) [0|255] "" UC_FREIN
# Description: Offset value for a rear brake sensor block.

 SG_ TRICPT_RB_INFO_POINTER_2 : 11|4@0+ (1,0) [0|0] "" UC_FREIN
# Description: Another pointer/index for tricapteur RB data information.

 SG_ RB_SENSOR_TYPE : 15|4@0+ (1,0) [0|0] "" UC_FREIN
# Description: Indicates the type of sensor used on the rear brake.

 SG_ RB_CHARACTERISTIC_6 : 17|6@0+ (1,0) [0|0] "" UC_FREIN
# Description: Represents a sixth characteristic or parameter for the rear brake sensor.

 SG_ RB_CHARACTERISTIC_7 : 23|6@0+ (1,0) [0|0] "" UC_FREIN
# Description: Represents a seventh characteristic or parameter for the rear brake sensor.

 SG_ RB_CHARACTERISTIC_5 : 27|6@0+ (1,0) [0|0] "" UC_FREIN
# Description: Represents a fifth characteristic or parameter for the rear brake sensor.

 SG_ RB_CHARACTERISTIC_4 : 37|6@0+ (1,0) [0|0] "" UC_FREIN
# Description: Represents a fourth characteristic or parameter for the rear brake sensor.

 SG_ RB_CHARACTERISTIC_2 : 41|6@0+ (1,0) [0|0] "" UC_FREIN
# Description: Represents a second characteristic or parameter for the rear brake sensor.

 SG_ RB_CHARACTERISTIC_3 : 47|6@0+ (1,0) [0|0] "" UC_FREIN
# Description: Represents a third characteristic or parameter for the rear brake sensor.

 SG_ RB_CHARACTERISTIC_1 : 51|6@0+ (1,0) [0|0] "" UC_FREIN
# Description: Represents a first characteristic or parameter for the rear brake sensor.

 SG_ RB_CHARACTERISTIC_0 : 61|6@0+ (1,0) [0|0] "" UC_FREIN
# Description: Represents a zeroth characteristic or parameter for the rear brake sensor.

BO_ 1420 HS2_REP_DIAG_ON_CAN_58C: 8 BVN
 SG_ DIAGNOSTIC_DATA : 7|64@0+ (1,0) [0|0] "" PASS_BSI
# Description: Contains diagnostic response data on CAN for the BVN.

BO_ 1426 HS2_DAT6_BSI_592: 8 BSI
 SG_ BATTERY_CHARGE_STATE : 7|8@0+ (1,0) [0|100] "%" PASS_HCU2,CMF,ARTIV,RITCS,UC_FREIN,CMM
# Description: Represents the percentage of battery charge state.

 SG_ BATTERY_TEMPERATURE : 15|8@0+ (0.5,-30) [-30|85] "Degree C" PASS_HCU2,CMF,ARTIV,RITCS,UC_FREIN,CMM
# Description: Represents the battery temperature in degrees Celsius.

 SG_ PARKING_BRAKE_MODE : 16|1@0+ (1,0) [0|0] "" PASS_HCU2,CMF,ARTIV,RITCS,UC_FREIN,CMM
# Description: Represents the current mode or engagement state of the parking brake system.

 SG_ COMMUTATION_SYSTEM_FAULT : 17|1@0+ (1,0) [0|0] "" PASS_HCU2,CMF,ARTIV,RITCS,UC_FREIN,CMM
# Description: Indicates a fault in the commutation system (e.g., CPC, BPGA).

 SG_ WIPER_STATE : 19|2@0+ (1,0) [0|0] "" PASS_HCU2,CMF,ARTIV,RITCS,UC_FREIN,CMM
# Description: Represents the current operational state of the windshield wipers.

 SG_ WIPER_COMMAND_HDC_FRONT : 22|3@0+ (1,0) [0|0] "" PASS_HCU2,CMF,ARTIV,RITCS,UC_FREIN,CMM
# Description: Command bits for front wiper high dynamic control or similar feature.

 SG_ REQUEST_AC_AERO_HYBRID_PUMP : 23|1@0+ (1,0) [0|0] "" PASS_HCU2,CMF,ARTIV,RITCS,UC_FREIN,CMM
# Description: Indicates a request to activate an aerodynamic pump for hybrid AC usage.

 SG_ BECB_BATTERY_VOLTAGE : 28|11@0+ (0.01,5) [5|18] "V" PASS_HCU2,CMF,ARTIV,RITCS,UC_FREIN,CMM
# Description: Represents the battery voltage measured by the BECB module.

 SG_ ALTERNATOR_PILOT_TYPE : 31|3@0+ (1,0) [0|0] "" PASS_HCU2,CMF,ARTIV,RITCS,UC_FREIN,CMM
# Description: Represents the type of alternator pilot or control mechanism.

 SG_ ARTIV_START_DETECTION : 33|2@0+ (1,0) [0|0] "" PASS_HCU2,CMF,ARTIV,RITCS,UC_FREIN,CMM
# Description: Indicates detection or start request from the ARTIV system.

 SG_ BATTERY_CALIBRATION_RANGE : 41|2@0+ (1,0) [0|0] "" PASS_HCU2,CMF,ARTIV,RITCS,UC_FREIN,CMM
# Description: Represents the calibration range or scale for battery current measurement.

 SG_ DSGI_RESET_REQUEST : 43|1@0+ (1,0) [0|0] "" PASS_HCU2,CMF,ARTIV,RITCS,UC_FREIN,CMM
# Description: Requests a reset of the DSGI (gear interface or integrated system).

 SG_ STT_STATE_CHANGE_REQUEST : 45|2@0+ (1,0) [0|0] "" PASS_HCU2,CMF,ARTIV,RITCS,UC_FREIN,CMM
# Description: Indicates a request to change the Start-Stop Technology (STT) state.

 SG_ AC_FLOW_REQUEST : 47|2@0+ (1,0) [0|0] "" PASS_HCU2,CMF,ARTIV,RITCS,UC_FREIN,CMM
# Description: Represents a request for airflow from the AC system.

 SG_ BATTERY_CURRENT : 55|16@0+ (1,0) [0|0] "" PASS_HCU2,CMF,ARTIV,RITCS,UC_FREIN,CMM
# Description: Represents the measured battery current in amperes.

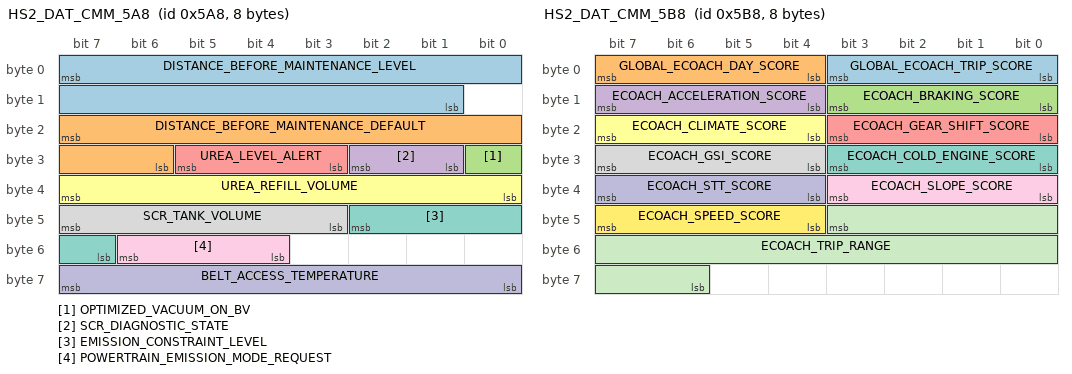
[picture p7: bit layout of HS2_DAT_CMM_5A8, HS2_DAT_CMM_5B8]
BO_ 1448 HS2_DAT_CMM_5A8: 8 CMM
 SG_ DISTANCE_BEFORE_MAINTENANCE_LEVEL : 7|15@0+ (1,0) [0|30000] "km" PASS_HCU2,BV,RITCS,BSI
# Description: Represents the distance in kilometers remaining before the next maintenance level.

 SG_ DISTANCE_BEFORE_MAINTENANCE_DEFAULT : 23|10@0+ (10,0) [0|10000] "km" PASS_HCU2,BV,RITCS,BSI
# Description: Represents the default or fallback distance before maintenance in kilometers.

 SG_ OPTIMIZED_VACUUM_ON_BV : 24|1@0+ (1,0) [0|0] "" PASS_HCU2,BV,RITCS,BSI
# Description: Indicates if an optimized vacuum control is activated on the gearbox.

 SG_ SCR_DIAGNOSTIC_STATE : 26|2@0+ (1,0) [0|0] "" PASS_HCU2,BV,RITCS,BSI
# Description: Represents the diagnostic state of the SCR (Selective Catalytic Reduction) system.

 SG_ UREA_LEVEL_ALERT : 29|3@0+ (1,0) [0|0] "" PASS_HCU2,BV,RITCS,BSI
# Description: Indicates the current alert level for the urea tank in a diesel vehicle.

 SG_ UREA_REFILL_VOLUME : 39|8@0+ (0.2,0) [0|50.8] "L" PASS_HCU2,BV,RITCS,BSI
# Description: Represents the volume of urea required for refill in liters.

 SG_ EMISSION_CONSTRAINT_LEVEL : 42|4@0+ (0.1,0) [0|1] "" PASS_HCU2,BV,RITCS,BSI
# Description: Indicates the level of emission constraints currently applied.

 SG_ SCR_TANK_VOLUME : 47|5@0+ (1,0) [0|30] "L" PASS_HCU2,BV,RITCS,BSI
# Description: Represents the total capacity of the SCR urea tank in liters.

 SG_ POWERTRAIN_EMISSION_MODE_REQUEST : 54|3@0+ (1,0) [0|0] "" PASS_HCU2,BV,RITCS,BSI
# Description: Represents a request for a specific powertrain emission mode.

 SG_ BELT_ACCESS_TEMPERATURE : 63|8@0+ (1,-40) [-40|214] "Degree C" PASS_HCU2,BV,RITCS,BSI
# Description: Represents a temperature reading for an accessory belt or related component.

BO_ 1449 HS2_DAT_BV_5A9: 4 BV
 SG_ TCU_TEMPERATURE : 7|8@0+ (1,-40) [-40|215] "Degree C" CMM
# Description: Represents the transmission control unit temperature in degrees Celsius.

BO_ 1452 HS2_REQ_DIAG_ON_CAN_5AC: 8 PASS_BSI
 SG_ DIAGNOSTIC_DATA : 7|64@0+ (1,0) [0|0] "" BVN
# Description: Contains diagnostic request data on CAN for the BSI.

BO_ 1455 HS2_REP_DIAG_ON_CAN_5AF: 8 AVAS
 SG_ DIAGNOSTIC_DATA : 7|64@0+ (1,0) [0|0] "" PASS_VCU
# Description: Contains diagnostic response data on CAN for the AVAS.

BO_ 1456 HS2_REQ_DIAG_ON_CAN_5B0: 8 PASS_VCU
 SG_ DIAGNOSTIC_DATA : 7|64@0+ (1,0) [0|0] "" AVAS
# Description: Contains diagnostic request data on CAN for the powertrain control unit (VCU).

BO_ 1464 HS2_DAT_CMM_5B8: 8 CMM
 SG_ GLOBAL_ECOACH_TRIP_SCORE : 3|4@0+ (1,0) [0|0] "" BSI
# Description: Represents the overall eco-coach score for the current trip.

 SG_ GLOBAL_ECOACH_DAY_SCORE : 7|4@0+ (1,0) [0|0] "" BSI
# Description: Represents the overall eco-coach score for the current day.

 SG_ ECOACH_BRAKING_SCORE : 11|4@0+ (1,0) [0|0] "" BSI
# Description: Represents the eco-coach score related to braking performance.

 SG_ ECOACH_ACCELERATION_SCORE : 15|4@0+ (1,0) [0|0] "" BSI
# Description: Represents the eco-coach score related to acceleration.

 SG_ ECOACH_GEAR_SHIFT_SCORE : 19|4@0+ (1,0) [0|0] "" BSI
# Description: Represents the eco-coach score related to gear shifting.

 SG_ ECOACH_CLIMATE_SCORE : 23|4@0+ (1,0) [0|0] "" BSI
# Description: Represents the eco-coach score related to climate control usage.

 SG_ ECOACH_COLD_ENGINE_SCORE : 27|4@0+ (1,0) [0|0] "" BSI
# Description: Represents the eco-coach score related to driving with a cold engine.

 SG_ ECOACH_GSI_SCORE : 31|4@0+ (1,0) [0|0] "" BSI
# Description: Represents the eco-coach score related to gear shift indicator usage.

 SG_ ECOACH_SLOPE_SCORE : 35|4@0+ (1,0) [0|0] "" BSI
# Description: Represents the eco-coach score related to driving on slopes or gradients.

 SG_ ECOACH_STT_SCORE : 39|4@0+ (1,0) [0|0] "" BSI
# Description: Represents the eco-coach score related to start-stop usage.

 SG_ ECOACH_TRIP_RANGE : 43|14@0+ (1,-6000) [-6000|10000] "km" BSI
# Description: Represents the range of distance used to calculate the eco-coach trip score.

 SG_ ECOACH_SPEED_SCORE : 47|4@0+ (1,0) [0|0] "" BSI
# Description: Represents the eco-coach score related to vehicle speed management.

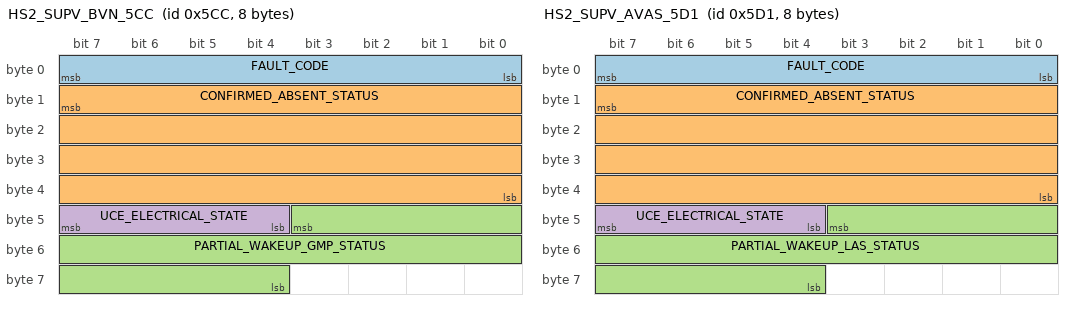
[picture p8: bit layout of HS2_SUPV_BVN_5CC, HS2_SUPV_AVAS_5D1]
BO_ 1484 HS2_SUPV_BVN_5CC: 8 BVN
 SG_ FAULT_CODE : 7|8@0+ (1,0) [0|0] "" Vector__XXX
# Description: Indicates a fault code or diagnostic trouble code from the BVN system.

 SG_ CONFIRMED_ABSENT_STATUS : 15|32@0+ (1,0) [0|0] "" Vector__XXX
# Description: Indicates which supervised ECUs are confirmed absent or present.

 SG_ PARTIAL_WAKEUP_GMP_STATUS : 43|16@0+ (1,0) [0|0] "" Vector__XXX
# Description: Indicates partial wakeup status for GMP (powertrain) or other modules.

 SG_ UCE_ELECTRICAL_STATE : 47|4@0+ (1,0) [0|0] "" Vector__XXX
# Description: Represents the electrical state or lifecycle mode of the control unit.

BO_ 1487 HS2_REP_DIAG_ON_CAN_5CF: 8 EBB
 SG_ DIAGNOSTIC_DATA : 7|64@0+ (1,0) [0|0] "" PASS_VCU
# Description: Contains diagnostic response data on CAN for the EBB (electronic brake booster).

BO_ 1488 HS2_REQ_DIAG_ON_CAN_5D0: 8 PASS_VCU
 SG_ DIAGNOSTIC_DATA : 7|64@0+ (1,0) [0|0] "" EBB
# Description: Contains diagnostic request data on CAN for the powertrain control unit (VCU).

BO_ 1489 HS2_SUPV_AVAS_5D1: 8 AVAS
 SG_ FAULT_CODE : 7|8@0+ (1,0) [0|0] "" Vector__XXX
# Description: Indicates a fault code or diagnostic trouble code for the AVAS system.

 SG_ CONFIRMED_ABSENT_STATUS : 15|32@0+ (1,0) [0|0] "" Vector__XXX
# Description: Indicates which supervised ECUs are confirmed absent or present in the AVAS system.

 SG_ PARTIAL_WAKEUP_LAS_STATUS : 43|16@0+ (1,0) [0|0] "" Vector__XXX
# Description: Indicates partial wakeup status for LAS or other modules in the AVAS system.

 SG_ UCE_ELECTRICAL_STATE : 47|4@0+ (1,0) [0|0] "" Vector__XXX
# Description: Represents the electrical state or lifecycle mode of the AVAS control unit.

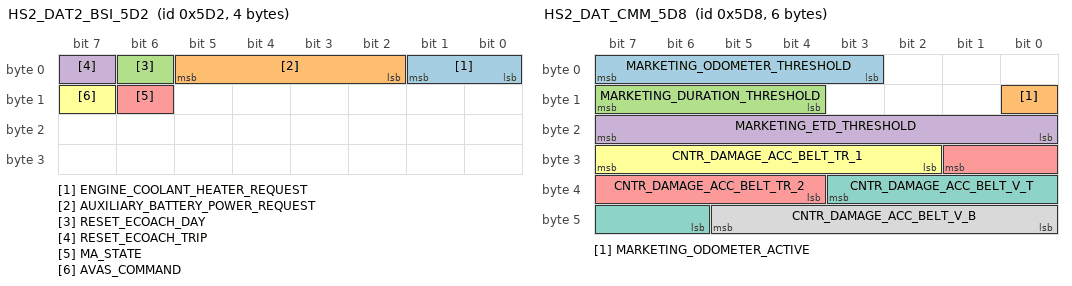
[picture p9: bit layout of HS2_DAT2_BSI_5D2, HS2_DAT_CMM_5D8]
BO_ 1490 HS2_DAT2_BSI_5D2: 4 BSI
 SG_ ENGINE_COOLANT_HEATER_REQUEST : 1|2@0+ (1,0) [0|0] "" PASS_HCU2,CMM
# Description: Indicates a request to activate the engine coolant heater for the motor.

 SG_ AUXILIARY_BATTERY_POWER_REQUEST : 5|4@0+ (1,0) [0|0] "" PASS_HCU2,CMM
# Description: Indicates a request for auxiliary battery power output.

 SG_ RESET_ECOACH_DAY : 6|1@0+ (1,0) [0|0] "" PASS_HCU2,CMM
# Description: Resets the daily eco-coach data or statistics.

 SG_ RESET_ECOACH_TRIP : 7|1@0+ (1,0) [0|0] "" PASS_HCU2,CMM
# Description: Resets the trip-level eco-coach data or statistics.

 SG_ MA_STATE : 14|1@0+ (1,0) [0|0] "" PASS_HCU2,CMM
# Description: Represents a current mode or state (MA) in the BSI system.

 SG_ AVAS_COMMAND : 15|1@0+ (1,0) [0|0] "" PASS_HCU2,CMM
# Description: Indicates a command to the audible vehicle alerting system.

BO_ 1496 HS2_DAT_CMM_5D8: 6 CMM
 SG_ MARKETING_ODOMETER_THRESHOLD : 7|5@0+ (1000,0) [0|30000] "km" BSI,RITCS
# Description: Represents a marketing threshold in kilometers to trigger certain alerts or actions.

 SG_ MARKETING_ODOMETER_ACTIVE : 8|1@0+ (1,0) [0|0] "" BSI,RITCS
# Description: Indicates whether the marketing odometer threshold feature is active.

 SG_ MARKETING_DURATION_THRESHOLD : 15|4@0+ (3,0) [0|24] "Mois" BSI,RITCS
# Description: Represents a marketing duration threshold in months.

 SG_ MARKETING_ETD_THRESHOLD : 23|8@0+ (500,0) [0|127000] "km" BSI,RITCS
# Description: Represents an extended threshold in kilometers for marketing or telematic data.

 SG_ CNTR_DAMAGE_ACC_BELT_TR_2 : 25|6@0+ (1,2) [0|100] "%" BSI,RITCS
# Description: Represents a damage counter or accumulation for belt tensioner 2 (accident metrics).

 SG_ CNTR_DAMAGE_ACC_BELT_TR_1 : 31|6@0+ (1,2) [0|100] "%" BSI,RITCS
# Description: Represents a damage counter or accumulation for belt tensioner 1 (accident metrics).

 SG_ CNTR_DAMAGE_ACC_BELT_V_T : 35|6@0+ (1,2) [0|100] "%" BSI,RITCS
# Description: Represents a damage counter for vertical top belt tensioners.

 SG_ CNTR_DAMAGE_ACC_BELT_V_B : 45|6@0+ (1,2) [0|100] "%" BSI,RITCS
# Description: Represents a damage counter for vertical bottom belt tensioners.

BO_ 1516 HS2_EMIS_NEW_JDD_BVN_5EC: 8 BVN
 SG_ FRAME_NUMBER_M : 5|2@0+ (1,0) [0|0] "" BSI
# Description: Indicates the frame number for fault logging or journaling (m part).

 SG_ FAULT_CODES_M1 : 15|24@0+ (1,0) [0|0] "" BSI
# Description: Contains fault codes for journaling segment m1.

 SG_ TIME_REFERENCE_M1 : 39|32@0+ (0.1,0) [0|429496729.3] "s" BSI
# Description: Represents the time reference in seconds for journaling segment m1.

 SG_ JDD_MILEAGE_M2 : 15|24@0+ (1,0) [0|16777214] "km" BSI
# Description: Represents the mileage associated with the JDD (fault journal) segment m2.

 SG_ JDD_LIFE_SITUATION_M2 : 39|24@0+ (1,0) [0|0] "" BSI
# Description: Represents the life-situation or context stored in the JDD segment m2.

 SG_ MESSAGE_TYPE : 1|2@0+ (1,0) [0|0] "" BSI
# Description: Indicates the type of message stored or transmitted in the JDD.

 SG_ DTC_STATE : 3|1@0+ (1,0) [0|0] "" BSI
# Description: Represents the state of a Diagnostic Trouble Code in the JDD.

 SG_ NUMBER_OF_FRAMES : 7|2@0+ (1,0) [0|0] "" BSI
# Description: Indicates how many frames are used in the JDD emission sequence.

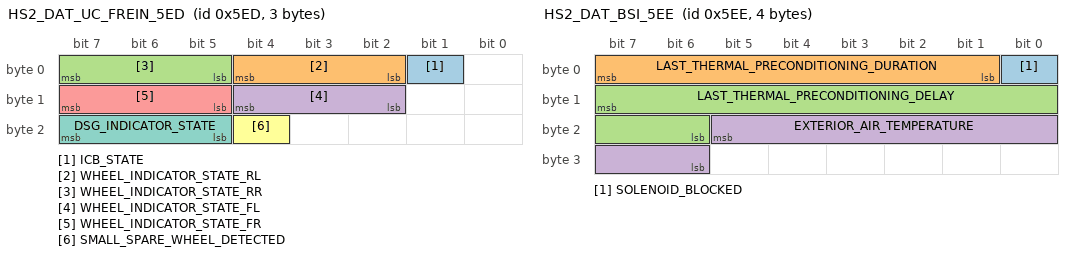
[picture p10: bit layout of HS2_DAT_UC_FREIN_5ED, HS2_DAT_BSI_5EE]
BO_ 1517 HS2_DAT_UC_FREIN_5ED: 3 UC_FREIN
 SG_ ICB_STATE : 1|1@0+ (1,0) [0|0] "" RITCS,BSI
# Description: Represents the state of the integrated brake controller (ICB).

 SG_ WHEEL_INDICATOR_STATE_RL : 4|3@0+ (1,0) [0|0] "" RITCS,BSI
# Description: Indicates the wheel state for the rear-left wheel (e.g., speed or inflation indicator).

 SG_ WHEEL_INDICATOR_STATE_RR : 7|3@0+ (1,0) [0|0] "" RITCS,BSI
# Description: Indicates the wheel state for the rear-right wheel.

 SG_ WHEEL_INDICATOR_STATE_FL : 12|3@0+ (1,0) [0|0] "" RITCS,BSI
# Description: Indicates the wheel state for the front-left wheel.

 SG_ WHEEL_INDICATOR_STATE_FR : 15|3@0+ (1,0) [0|0] "" RITCS,BSI
# Description: Indicates the wheel state for the front-right wheel.

 SG_ SMALL_SPARE_WHEEL_DETECTED : 20|1@0+ (1,0) [0|0] "" RITCS,BSI
# Description: Indicates if a small spare wheel is detected and mounted.

 SG_ DSG_INDICATOR_STATE : 23|3@0+ (1,0) [0|0] "" RITCS,BSI
# Description: Represents a status related to DSG or gear engagement indicators.

BO_ 1518 HS2_DAT_BSI_5EE: 4 BSI
 SG_ SOLENOID_BLOCKED : 0|1@0+ (1,0) [0|0] "" BVN,CMM,RITCS
# Description: Indicates whether a solenoid is blocked or stuck.

 SG_ LAST_THERMAL_PRECONDITIONING_DURATION : 7|7@0+ (30,-30) [0|2700] "s" BVN,CMM,RITCS
# Description: Represents the duration in seconds of the last thermal preconditioning event.

 SG_ LAST_THERMAL_PRECONDITIONING_DELAY : 15|10@0+ (1,-1) [0|720] "min" BVN,CMM,RITCS
# Description: Represents the delay in minutes before the last thermal preconditioning event.

 SG_ EXTERIOR_AIR_TEMPERATURE : 21|8@0+ (0.5,-40) [-40|85] "Degree C" BVN,CMM,RITCS
# Description: Represents the exterior air temperature in degrees Celsius.

BO_ 1519 HS2_EMIS_NEW_JDD_EBB_5EF: 8 EBB
 SG_ FRAME_NUMBER_M : 5|2@0+ (1,0) [0|0] "" BSI
# Description: Indicates the frame number for fault logging or journaling (m part).

 SG_ FAULT_CODES_M1 : 15|24@0+ (1,0) [0|0] "" BSI
# Description: Contains fault codes for journaling segment m1.

 SG_ TIME_REFERENCE_M1 : 39|32@0+ (0.1,0) [0|429496729.3] "s" BSI
# Description: Represents the time reference in seconds for journaling segment m1.

 SG_ JDD_MILEAGE_M2 : 15|24@0+ (1,0) [0|16777214] "km" BSI
# Description: Represents the mileage associated with the JDD (fault journal) segment m2.

 SG_ JDD_LIFE_SITUATION_M2 : 39|24@0+ (1,0) [0|0] "" BSI
# Description: Represents the life-situation or context stored in the JDD segment m2.

 SG_ MESSAGE_TYPE : 1|2@0+ (1,0) [0|0] "" BSI
# Description: Indicates the type of message stored or transmitted in the JDD.

 SG_ DTC_STATE : 3|1@0+ (1,0) [0|0] "" BSI
# Description: Represents the state of a Diagnostic Trouble Code in the JDD.

 SG_ NUMBER_OF_FRAMES : 7|2@0+ (1,0) [0|0] "" BSI
# Description: Indicates how many frames are used in the JDD emission sequence.

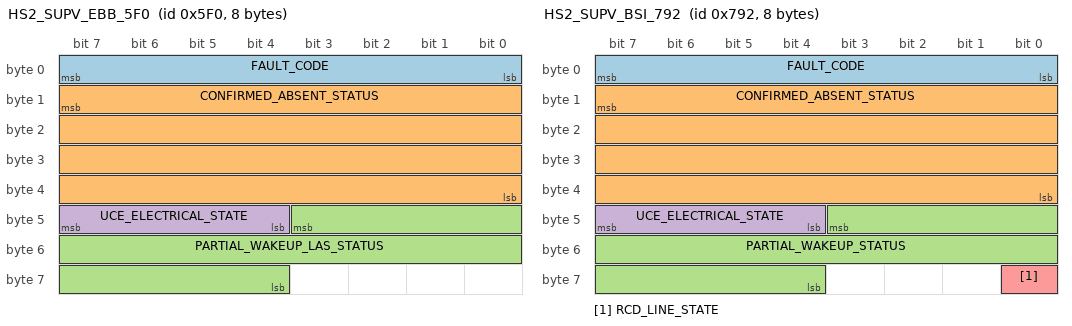
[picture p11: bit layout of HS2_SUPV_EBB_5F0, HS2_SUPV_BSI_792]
BO_ 1520 HS2_SUPV_EBB_5F0: 8 EBB
 SG_ FAULT_CODE : 7|8@0+ (1,0) [0|0] "" Vector__XXX
# Description: Indicates a fault code or diagnostic trouble code for the EBB system.

 SG_ CONFIRMED_ABSENT_STATUS : 15|32@0+ (1,0) [0|0] "" Vector__XXX
# Description: Indicates which supervised ECUs are confirmed absent or present in the EBB system.

 SG_ PARTIAL_WAKEUP_LAS_STATUS : 43|16@0+ (1,0) [0|0] "" Vector__XXX
# Description: Indicates partial wakeup status for LAS or other modules in the EBB system.

 SG_ UCE_ELECTRICAL_STATE : 47|4@0+ (1,0) [0|0] "" Vector__XXX
# Description: Represents the electrical state or lifecycle mode of the EBB control unit.

BO_ 1521 HS2_EMIS_NEW_JDD_AVAS_5F1: 8 AVAS
 SG_ FRAME_NUMBER_M : 5|2@0+ (1,0) [0|0] "" BSI
# Description: Indicates the frame number for fault logging or journaling (m part).

 SG_ FAULT_CODES_M1 : 15|24@0+ (1,0) [0|0] "" BSI
# Description: Contains fault codes for journaling segment m1.

 SG_ TIME_REFERENCE_M1 : 39|32@0+ (0.1,0) [0|429496729.3] "s" BSI
# Description: Represents the time reference in seconds for journaling segment m1.

 SG_ JDD_MILEAGE_M2 : 15|24@0+ (1,0) [0|16777214] "km" BSI
# Description: Represents the mileage associated with the JDD (fault journal) segment m2.

 SG_ JDD_LIFE_SITUATION_M2 : 39|24@0+ (1,0) [0|0] "" BSI
# Description: Represents the life-situation or context stored in the JDD segment m2.

 SG_ MESSAGE_TYPE : 1|2@0+ (1,0) [0|0] "" BSI
# Description: Indicates the type of message stored or transmitted in the JDD.

 SG_ DTC_STATE : 3|1@0+ (1,0) [0|0] "" BSI
# Description: Represents the state of a Diagnostic Trouble Code in the JDD.

 SG_ NUMBER_OF_FRAMES : 7|2@0+ (1,0) [0|0] "" BSI
# Description: Indicates how many frames are used in the JDD emission sequence.

BO_ 1554 HS2_DAT7_BSI_612: 8 BSI
 SG_ DYNAMIC_CORNER_LIGHTING_DISABLE : 5|1@0+ (1,0) [0|0] "" CMM,BV,BVN
# Description: Indicates whether dynamic corner lighting is disabled.

 SG_ HIGHWAY_LIGHTING_DISABLE : 6|1@0+ (1,0) [0|0] "" CMM,BV,BVN
# Description: Indicates whether highway lighting is disabled.

 SG_ DAYTIME_RUNNING_LIGHT_DISABLE : 7|1@0+ (1,0) [0|0] "" CMM,BV,BVN
# Description: Indicates whether daytime running lights are disabled.

 SG_ LOW_BEAM_STATE : 9|1@0+ (1,0) [0|0] "" CMM,BV,BVN
# Description: Indicates the operational state of the low beam headlights.

 SG_ HIGH_BEAM_STATE : 10|1@0+ (1,0) [0|0] "" CMM,BV,BVN
# Description: Indicates the operational state of the high beam headlights.

 SG_ VEHICLE_CONFIGURATION_MODE : 13|2@0+ (1,0) [0|0] "" CMM,BV,BVN
# Description: Represents the current vehicle configuration or mode.

 SG_ CLG_AND_HDC_COMMAND : 15|2@0+ (1,0) [0|3] "" CMM,BV,BVN
# Description: Represents commands to a clearing or hill descent control function.

 SG_ ECO_MODE : 17|2@0+ (1,0) [0|0] "" CMM,BV,BVN
# Description: Indicates whether the vehicle is in ECO mode.

 SG_ ASR_PLUS_MODE_SELECTION : 19|2@0+ (1,0) [0|0] "" CMM,BV,BVN
# Description: Represents the selection status of the advanced traction control (ASR+) mode.

 SG_ LEFT_HIGH_BEAM_FAULT : 20|1@0+ (1,0) [0|0] "" CMM,BV,BVN
# Description: Indicates a fault in the left high beam headlight.

 SG_ RIGHT_HIGH_BEAM_FAULT : 21|1@0+ (1,0) [0|0] "" CMM,BV,BVN
# Description: Indicates a fault in the right high beam headlight.

 SG_ LEFT_LOW_BEAM_FAULT : 22|1@0+ (1,0) [0|0] "" CMM,BV,BVN
# Description: Indicates a fault in the left low beam headlight.

 SG_ RIGHT_LOW_BEAM_FAULT : 23|1@0+ (1,0) [0|0] "" CMM,BV,BVN
# Description: Indicates a fault in the right low beam headlight.

 SG_ FUEL_LEVEL_INFO : 31|8@0+ (0.5,0) [0|127] "L" CMM,BV,BVN
# Description: Represents the measured or estimated fuel level in liters.

 SG_ PRED_STARTER_VOLTAGE : 34|11@0+ (0.01,0) [0|13] "V" CMM,BV,BVN
# Description: Represents the predicted voltage level for starter engagement.

 SG_ DEFLECTOR_MOBILE_POSITION : 38|3@0+ (1,0) [0|0] "" CMM,BV,BVN
# Description: Indicates the position of a mobile deflector (e.g., spoiler or aerodynamic device).

 SG_ REAR_ACTUATOR_OLVI_REQUEST_INFO : 39|1@0+ (1,0) [0|0] "" CMM,BV,BVN
# Description: Indicates a request for rear actuator or OLVI (over-lift valve integration).

 SG_ UB_D_LINE_REL_RX : 49|1@0+ (1,0) [0|0] "" CMM,BV,BVN
# Description: Represents a bit indicating status or line condition for a relative RX signal.

 SG_ D_LINE_REL_R2 : 52|3@0+ (1,0) [0|0] "" CMM,BV,BVN
# Description: Indicates a line status or offset for R2.

 SG_ D_LINE_REL_R1 : 55|3@0+ (1,0) [0|0] "" CMM,BV,BVN
# Description: Indicates a line status or offset for R1.

 SG_ VEHICLE_CONFIGURATION : 60|3@0+ (1,0) [0|0] "" CMM,BV,BVN
# Description: Represents the current vehicle configuration bits.

 SG_ D_LINE_REL_R3 : 63|3@0+ (1,0) [0|0] "" CMM,BV,BVN
# Description: Indicates a line status or offset for R3.

BO_ 1686 HS2_REP_DIAG_ON_CAN_696: 8 ARTIV
 SG_ DIAGNOSTIC_DATA : 7|64@0+ (1,0) [0|0] "" PASS_BSI
# Description: Contains diagnostic response data on CAN for the ARTIV system.

BO_ 1689 HS2_REP_DIAG_ON_CAN_699: 8 CAPT_ALG
 SG_ DIAGNOSTIC_DATA : 7|64@0+ (1,0) [0|0] "" PASS_BSI
# Description: Contains diagnostic response data on CAN for the CAPT_ALG system.

BO_ 1693 HS2_REP_DIAG_ON_CAN_69D: 8 MCM
 SG_ DIAGNOSTIC_DATA : 7|64@0+ (1,0) [0|0] "" OUTIL_DIAG
# Description: Contains diagnostic response data on CAN for the MCM (motor control module).

BO_ 1718 HS2_REQ_DIAG_ON_CAN_6B6: 8 PASS_BSI
 SG_ DIAGNOSTIC_DATA : 7|64@0+ (1,0) [0|0] "" ARTIV
# Description: Contains diagnostic request data on CAN from the BSI to the ARTIV system.

BO_ 1721 HS2_REQ_DIAG_ON_CAN_6B9: 8 PASS_BSI
 SG_ DIAGNOSTIC_DATA : 7|64@0+ (1,0) [0|0] "" CAPT_ALG
# Description: Contains diagnostic request data on CAN from the BSI to the CAPT_ALG system.

BO_ 1725 HS2_REQ_DIAG_ON_CAN_6BD: 8 OUTIL_DIAG
 SG_ DIAGNOSTIC_DATA : 7|64@0+ (1,0) [0|0] "" MCM
# Description: Contains diagnostic request data on CAN from the diagnostic tool to the MCM system.

BO_ 1910 HS2_EMIS_NEW_JDD_ARTIV_776: 8 ARTIV
 SG_ FRAME_NUMBER_M : 5|2@0+ (1,0) [0|0] "" BSI
# Description: Indicates the frame number for fault logging or journaling (m part).

 SG_ FAULT_CODES_M1 : 15|24@0+ (1,0) [0|0] "" BSI
# Description: Contains fault codes for journaling segment m1.

 SG_ TIME_REFERENCE_M1 : 39|32@0+ (0.1,0) [0|429496729.3] "s" BSI
# Description: Represents the time reference in seconds for journaling segment m1.

 SG_ JDD_MILEAGE_M2 : 15|24@0+ (1,0) [0|16777214] "km" BSI
# Description: Represents the mileage associated with the JDD (fault journal) segment m2.

 SG_ JDD_LIFE_SITUATION_M2 : 39|24@0+ (1,0) [0|0] "" BSI
# Description: Represents the life-situation or context stored in the JDD segment m2.

 SG_ MESSAGE_TYPE : 1|2@0+ (1,0) [0|0] "" BSI
# Description: Indicates the type of message stored or transmitted in the JDD.

 SG_ DTC_STATE : 3|1@0+ (1,0) [0|0] "" BSI
# Description: Represents the state of a Diagnostic Trouble Code in the JDD.

 SG_ NUMBER_OF_FRAMES : 7|2@0+ (1,0) [0|0] "" BSI
# Description: Indicates how many frames are used in the JDD emission sequence.

BO_ 1917 HS2_EMIS_NEW_JDD_ASR_PLUS_77D: 8 MCM
 SG_ FRAME_NUMBER_M : 5|2@0+ (1,0) [0|0] "" BSI
# Description: Indicates the frame number for fault logging or journaling (m part).

 SG_ FAULT_CODES_M1 : 15|24@0+ (1,0) [0|0] "" BSI
# Description: Contains fault codes for journaling segment m1.

 SG_ TIME_REFERENCE_M1 : 39|32@0+ (0.1,0) [0|429496729.3] "s" BSI
# Description: Represents the time reference in seconds for journaling segment m1.

 SG_ JDD_MILEAGE_M2 : 15|24@0+ (1,0) [0|16777214] "km" BSI
# Description: Represents the mileage associated with the JDD (fault journal) segment m2.

 SG_ JDD_LIFE_SITUATION_M2 : 39|24@0+ (1,0) [0|0] "" BSI
# Description: Represents the life-situation or context stored in the JDD segment m2.

 SG_ MESSAGE_TYPE : 1|2@0+ (1,0) [0|0] "" BSI
# Description: Indicates the type of message stored or transmitted in the JDD.

 SG_ DTC_STATE : 3|1@0+ (1,0) [0|0] "" BSI
# Description: Represents the state of a Diagnostic Trouble Code in the JDD.

 SG_ NUMBER_OF_FRAMES : 7|2@0+ (1,0) [0|0] "" BSI
# Description: Indicates how many frames are used in the JDD emission sequence.

BO_ 1938 HS2_SUPV_BSI_792: 8 BSI
 SG_ FAULT_CODE : 7|8@0+ (1,0) [0|0] "" Vector__XXX
# Description: Indicates a fault code or diagnostic trouble code from the BSI.

 SG_ CONFIRMED_ABSENT_STATUS : 15|32@0+ (1,0) [0|0] "" Vector__XXX
# Description: Indicates which supervised ECUs are confirmed absent or present.

 SG_ PARTIAL_WAKEUP_STATUS : 43|16@0+ (1,0) [0|0] "" Vector__XXX
# Description: Indicates partial wakeup status of BSI or other modules.

 SG_ UCE_ELECTRICAL_STATE : 47|4@0+ (1,0) [0|0] "" Vector__XXX
# Description: Represents the electrical state or lifecycle mode of the BSI.

 SG_ RCD_LINE_STATE : 56|1@0+ (1,0) [0|0] "" Vector__XXX
# Description: Indicates the line state for the remote comfort device (RCD) or partial wake.

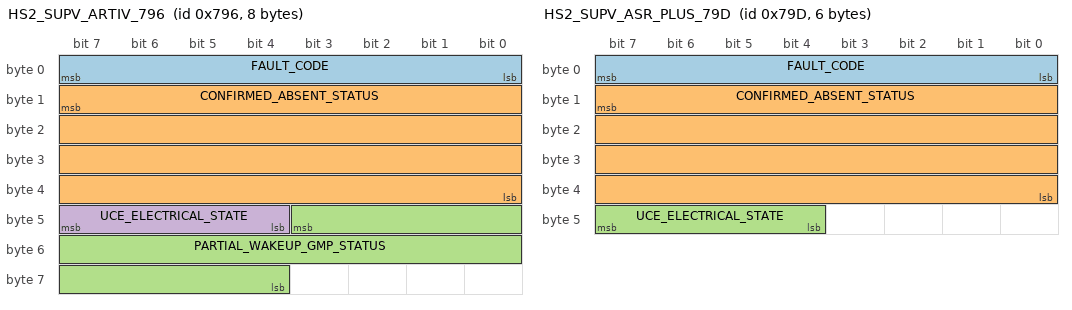
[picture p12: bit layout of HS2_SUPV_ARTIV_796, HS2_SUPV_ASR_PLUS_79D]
BO_ 1942 HS2_SUPV_ARTIV_796: 8 ARTIV
 SG_ FAULT_CODE : 7|8@0+ (1,0) [0|0] "" Vector__XXX
# Description: Indicates a fault code or diagnostic trouble code from the ARTIV system.

 SG_ CONFIRMED_ABSENT_STATUS : 15|32@0+ (1,0) [0|0] "" Vector__XXX
# Description: Indicates which supervised ECUs are confirmed absent or present.

 SG_ PARTIAL_WAKEUP_GMP_STATUS : 43|16@0+ (1,0) [0|0] "" Vector__XXX
# Description: Indicates partial wakeup status for GMP or other modules within ARTIV.

 SG_ UCE_ELECTRICAL_STATE : 47|4@0+ (1,0) [0|0] "" Vector__XXX
# Description: Represents the electrical state or lifecycle mode of the ARTIV control unit.

BO_ 1949 HS2_SUPV_ASR_PLUS_79D: 6 MCM
 SG_ FAULT_CODE : 7|8@0+ (1,0) [0|0] "" Vector__XXX
# Description: Indicates a fault code or diagnostic trouble code for the ASR_PLUS system.

 SG_ CONFIRMED_ABSENT_STATUS : 15|32@0+ (1,0) [0|0] "" Vector__XXX
# Description: Indicates which supervised ECUs are confirmed absent or present in the ASR_PLUS system.

 SG_ UCE_ELECTRICAL_STATE : 47|4@0+ (1,0) [0|0] "" Vector__XXX
# Description: Represents the electrical state or lifecycle mode of the MCM in the ASR_PLUS system.
;TODO
;BO_ 2047 HS2_DIAG_UDS_ON_CAN_7FF: 8 OUTIL_DIAG
; SG_ DATA_DIAG : 7|64@0+ (1,0) [0|0] "" UC_DIRA,UC_FREIN,CMM,BV,FAMILLE_DSG,SUSP,FSE,PROJ,SBW,PASS_BSM,CAPT_VOL

BO_TX_BU_ 1270 : ARTIV,CMF;
BO_TX_BU_ 1721 : PASS_BSI,OUTIL_DIAG;
; #############################################################################
; ############################### EPS B0 #####################################
; #############################################################################
;TODO
;BO_ 3221225472 VECTOR__INDEPENDENT_SIG_MSG: 0 Vector__XXX
; SG_ CHKSUM_VOL : 0|4@0+ (1,0) [0|15] "N/A" Vector__XXX
; SG_ CPT_PROCESS_4B_A_VOL : 0|4@0+ (1,0) [0|15] "" Vector__XXX

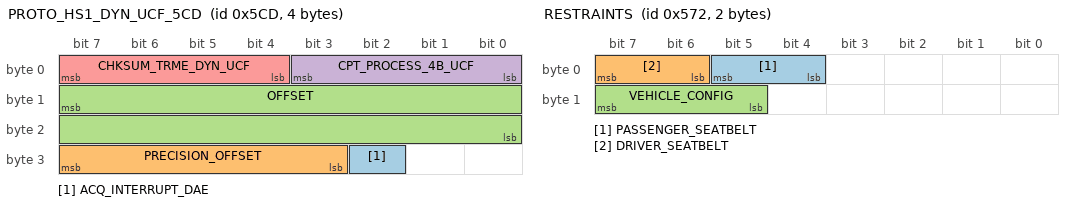
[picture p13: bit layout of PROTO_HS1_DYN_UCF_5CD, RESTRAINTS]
BO_ 1485 PROTO_HS1_DYN_UCF_5CD: 4 Tester
 SG_ ACQ_INTERRUPT_DAE : 26|1@0+ (1,0) [0|1] "N/A"  PSCM
# Description: Indicates an acquisition interrupt from the DAE (steering assistance system).

 SG_ PRECISION_OFFSET : 31|5@0+ (1,0) [0|31] "Deg"  PSCM
# Description: Represents an offset for steering angle precision in degrees.

 SG_ OFFSET : 15|16@0- (0.1,0) [-1630|1630] "Deg"  PSCM
# Description: Represents a steering angle offset in degrees.

 SG_ CPT_PROCESS_4B_UCF : 3|4@0+ (1,0) [0|15] ""  PSCM
# Description: 4-bit process counter for UCF data consistency checks.

 SG_ CHKSUM_TRME_DYN_UCF : 7|4@0+ (1,0) [0|15] "UNM"  PSCM
# Description: Checksum for dynamic UCF data frames.

BO_ 1394 RESTRAINTS: 2 Tester
 SG_ PASSENGER_SEATBELT : 5|2@0+ (1,0) [0|3] "" XXX
# Description: Indicates the passenger seatbelt status or usage level.

 SG_ DRIVER_SEATBELT : 7|2@0+ (1,0) [0|3] "" XXX
# Description: Indicates the driver seatbelt status or usage level.

 SG_ VEHICLE_CONFIG : 15|3@0+ (1,0) [0|7] ""  PSCM
# Description: Represents the vehicle configuration bits related to the restraint system.

BO_ 1293 IS_DAT_ABR_50D: 8 Tester
 SG_ ABS_REGUL : 5|1@0+ (1,0) [0|1] ""  PSCM
# Description: Indicates if the ABS is in a regulation/control phase (active).
;TODO
;BO_ 973 IS_DYN2_FRE_3CD: 4 Tester
; SG_ Accel_Lat : 7|16@0- (0.05,0) [0|0] ""  PSCM
;TODO
;BO_ 845 IS_DYN_CDS_34D: 8 Tester
; SG_ REQ_Lampe_DEF_ESP : 4|1@0+ (1,0) [0|1] ""  PSCM
; SG_ Regul_ESP : 6|1@0+ (1,0) [0|1] ""  PSCM
; SG_ ESP_Deconnecte : 7|1@0+ (1,0) [0|1] ""  PSCM

BO_ 1906 IS_ACQ_JDD_CAN_BSI_772: 1 Tester
 SG_ DATA_ACQ_JDD_BSI : 7|8@0+ (1,0) [0|255] ""  PSCM
# Description: Data acquisition related to the BSI fault journal or JDD.

BO_ 1375 IS_ACQ_NEW_JDD_55F: 1 Tester
 SG_ DATA_ACQ_JDD_BSI_2 : 7|8@0+ (1,0) [0|255] ""  PSCM
# Description: Data acquisition for the new BSI fault journal or JDD (segment 2).

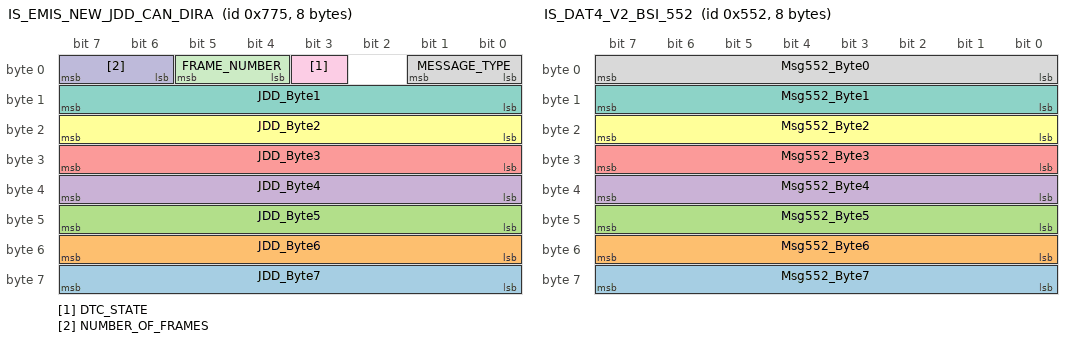
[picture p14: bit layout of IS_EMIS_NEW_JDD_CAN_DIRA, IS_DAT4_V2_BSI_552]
BO_ 1909 IS_EMIS_NEW_JDD_CAN_DIRA: 8 PSCM
 SG_ JDD_Byte7 : 63|8@0+ (1,0) [0|255] "" Vector__XXX
# Description: Represents byte 7 of the JDD data emitted by the DIRA system.

 SG_ JDD_Byte6 : 55|8@0+ (1,0) [0|255] "" Vector__XXX
# Description: Represents byte 6 of the JDD data emitted by the DIRA system.

 SG_ JDD_Byte5 : 47|8@0+ (1,0) [0|255] "" Vector__XXX
# Description: Represents byte 5 of the JDD data emitted by the DIRA system.

 SG_ JDD_Byte4 : 39|8@0+ (1,0) [0|255] "" Vector__XXX
# Description: Represents byte 4 of the JDD data emitted by the DIRA system.

 SG_ JDD_Byte3 : 31|8@0+ (1,0) [0|255] "" Vector__XXX
# Description: Represents byte 3 of the JDD data emitted by the DIRA system.

 SG_ JDD_Byte2 : 23|8@0+ (1,0) [0|255] "" Vector__XXX
# Description: Represents byte 2 of the JDD data emitted by the DIRA system.

 SG_ JDD_Byte1 : 15|8@0+ (1,0) [0|255] "" Vector__XXX
# Description: Represents byte 1 of the JDD data emitted by the DIRA system.

 SG_ MESSAGE_TYPE : 1|2@0+ (1,0) [0|3] ""  Tester
# Description: Indicates the type of diagnostic or data message.

 SG_ DTC_STATE : 3|1@0+ (1,0) [0|1] ""  Tester
# Description: Represents the state of a Diagnostic Trouble Code in the DIRA system.

 SG_ NUMBER_OF_FRAMES : 7|2@0+ (1,0) [0|3] ""  Tester
# Description: Indicates how many frames are used in this DIRA JDD emission.

 SG_ FRAME_NUMBER : 5|2@0+ (1,0) [0|3] ""  Tester
# Description: Indicates the frame number in the DIRA JDD sequence.

BO_ 1362 IS_DAT4_V2_BSI_552: 8 Tester
 SG_ Msg552_Byte7 : 63|8@0+ (1,0) [0|255] ""  PSCM
# Description: Byte 7 of the BSI message ID 552, version 2.

 SG_ Msg552_Byte6 : 55|8@0+ (1,0) [0|255] ""  PSCM
# Description: Byte 6 of the BSI message ID 552, version 2.

 SG_ Msg552_Byte5 : 47|8@0+ (1,0) [0|255] ""  PSCM
# Description: Byte 5 of the BSI message ID 552, version 2.

 SG_ Msg552_Byte4 : 39|8@0+ (1,0) [0|255] ""  PSCM
# Description: Byte 4 of the BSI message ID 552, version 2.

 SG_ Msg552_Byte3 : 31|8@0+ (1,0) [0|255] ""  PSCM
# Description: Byte 3 of the BSI message ID 552, version 2.

 SG_ Msg552_Byte2 : 23|8@0+ (1,0) [0|255] ""  PSCM
# Description: Byte 2 of the BSI message ID 552, version 2.

 SG_ Msg552_Byte1 : 15|8@0+ (1,0) [0|255] ""  PSCM
# Description: Byte 1 of the BSI message ID 552, version 2.

 SG_ Msg552_Byte0 : 7|8@0+ (1,0) [0|255] ""  PSCM
# Description: Byte 0 of the BSI message ID 552, version 2.

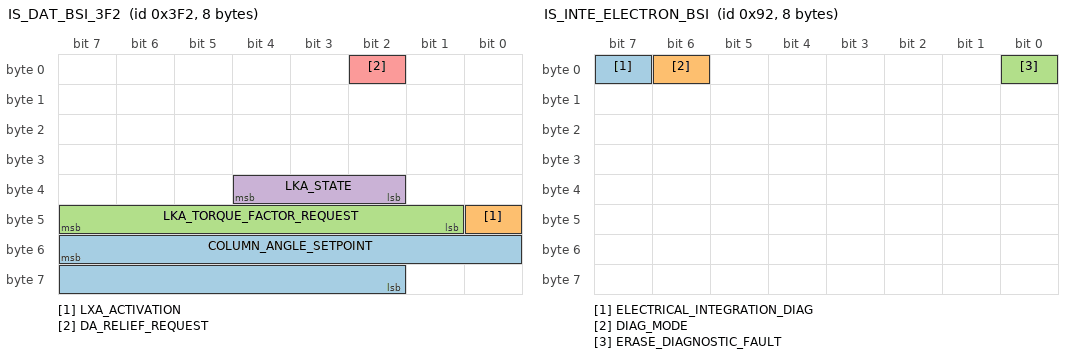
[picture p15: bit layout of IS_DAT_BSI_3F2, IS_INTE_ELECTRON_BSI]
BO_ 1010 IS_DAT_BSI_3F2: 8 Tester
 SG_ COLUMN_ANGLE_SETPOINT : 55|14@0- (0.1,0) [-780|780] ""  PSCM
# Description: Represents a setpoint or target angle for the steering column in degrees.

 SG_ LXA_ACTIVATION : 40|1@0+ (1,0) [0|0] ""  PSCM
# Description: Indicates whether LXA (lane-keeping assist) is activated.

 SG_ LKA_TORQUE_FACTOR_REQUEST : 47|7@0+ (0.01,0) [0|0] ""  PSCM
# Description: Represents a requested torque factor for lane-keeping assist (LKA).

 SG_ LKA_STATE : 36|3@0+ (1,0) [0|0] ""  PSCM
# Description: Indicates the operating state of the lane-keeping assist (LKA) system.

 SG_ DA_RELIEF_REQUEST : 2|1@0+ (1,0) [0|1] ""  PSCM
# Description: Indicates a request to reduce steering assist.

BO_ 146 IS_INTE_ELECTRON_BSI: 8 Tester
 SG_ ELECTRICAL_INTEGRATION_DIAG : 7|1@0+ (1,0) [0|1] ""  PSCM
# Description: Indicates a diagnostic condition for electrical integration within the BSI.

 SG_ DIAG_MODE : 6|1@0+ (1,0) [0|1] ""  PSCM
# Description: Indicates a diagnostic mode is active.

 SG_ ERASE_DIAGNOSTIC_FAULT : 0|1@0+ (1,0) [0|1] ""  PSCM
# Description: Indicates whether diagnostic faults should be erased.
;TODO
;BO_ 904 IS_DYN_CMM_388: 8 Tester
; SG_ VITESSE_VEHICLE_BV : 7|16@0+ (0.01,0) [0|655.34] "Kph"  PSCM

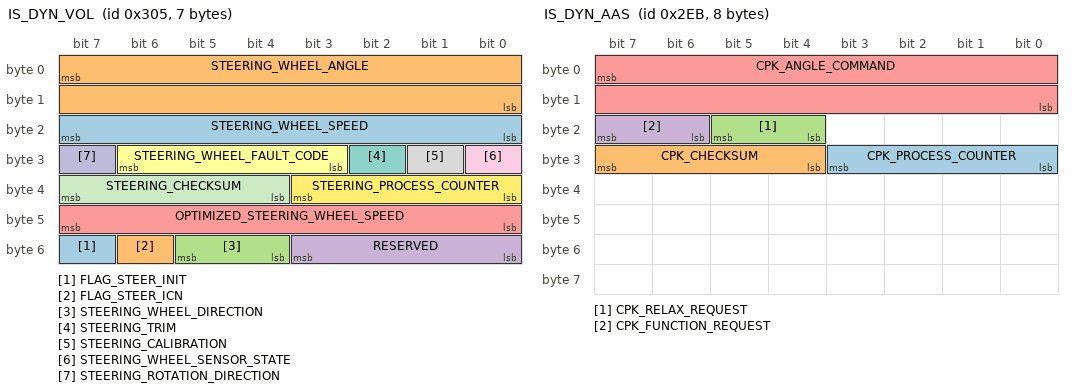
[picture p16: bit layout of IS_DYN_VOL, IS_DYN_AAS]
BO_ 773 IS_DYN_VOL: 7 Tester
 SG_ FLAG_STEER_INIT : 55|1@0+ (1,0) [0|1] "" Vector__XXX
# Description: Indicates whether the steering initialization flag is set.

 SG_ FLAG_STEER_ICN : 54|1@0+ (1,0) [0|1] "" Vector__XXX
# Description: Indicates a flag related to steering icon or indication.

 SG_ STEERING_WHEEL_DIRECTION : 53|2@0+ (1,0) [0|3] "" Vector__XXX
# Description: Indicates the direction of steering wheel rotation.

 SG_ RESERVED : 51|4@0+ (1,0) [0|15] "" Vector__XXX
# Description: Reserved bits.

 SG_ OPTIMIZED_STEERING_WHEEL_SPEED : 47|8@0+ (4,0) [0|1016] "" Vector__XXX
# Description: Represents an optimized steering wheel speed value.

 SG_ STEERING_WHEEL_FAULT_CODE : 30|4@0+ (1,0) [0|15] "N/A" Vector__XXX
# Description: Indicates a fault code for the steering wheel sensor.

 SG_ STEERING_TRIM : 26|1@0+ (1,0) [0|1] "" Vector__XXX
# Description: Indicates a trim or calibration bit for steering.

 SG_ STEERING_CALIBRATION : 25|1@0+ (1,0) [0|1] "" Vector__XXX
# Description: Indicates a calibration bit for the steering wheel system.

 SG_ STEERING_WHEEL_SENSOR_STATE : 24|1@0+ (1,0) [0|1] "" Vector__XXX
# Description: Represents the operational state of the steering wheel sensor.

 SG_ STEERING_ROTATION_DIRECTION : 31|1@0+ (1,0) [0|1] ""  PSCM
# Description: Indicates the current rotation direction of the steering wheel.

 SG_ STEERING_CHECKSUM : 39|4@0+ (1,0) [0|15] ""  PSCM
# Description: Checksum for the steering data frame.

 SG_ STEERING_PROCESS_COUNTER : 35|4@0+ (1,0) [0|15] ""  PSCM
# Description: 4-bit process counter for steering data checks.

 SG_ STEERING_WHEEL_SPEED : 23|8@0+ (4,0) [0|1016] "Deg/s"  PSCM
# Description: Represents the steering wheel angular speed in degrees per second.

 SG_ STEERING_WHEEL_ANGLE : 7|16@0- (0.1,0) [-780|780] "Deg"  PSCM
# Description: Represents the current steering wheel angle in degrees.
;TODO
;BO_ 1042 IS_DAT_BSI_412: 8 Tester
; SG_ Req_Mode_DA : 31|2@0+ (1,0) [0|3] ""  PSCM

BO_ 747 IS_DYN_AAS: 8 Tester
 SG_ CPK_PROCESS_COUNTER : 27|4@0+ (1,0) [0|15] ""  PSCM
# Description: 4-bit process counter for the CPK (column power steering) data.

 SG_ CPK_CHECKSUM : 31|4@0+ (1,0) [0|15] ""  PSCM
# Description: Checksum for the dynamic CPK data.

 SG_ CPK_RELAX_REQUEST : 21|2@0+ (1,0) [0|3] ""  PSCM
# Description: Indicates a request to relax or reduce the assistance of the CPK.

 SG_ CPK_FUNCTION_REQUEST : 23|2@0+ (1,0) [0|3] ""  PSCM
# Description: Indicates a request for a specific function mode of the CPK.

 SG_ CPK_ANGLE_COMMAND : 7|16@0- (0.1,0) [-780|780] "Deg"  PSCM
# Description: Represents the commanded steering column angle in degrees for the CPK.

BO_ 2047 IS_DIAG_UDS_ON_CAN_7FF: 8 Tester
 SG_ DIAGNOSTIC_FUNCTIONAL_REQUEST : 7|64@0+ (1,0) [0|4294967295] ""  PSCM
# Description: Contains UDS diagnostic functional request data on CAN.

BO_ 1968 XCP_RES: 8 PSCM
 SG_ XCP_Data_Res : 7|64@0+ (1,0) [0|4294967295] ""  PSCM,Tester
# Description: Contains XCP response data for calibration or measurement.

BO_ 1966 XCP_REQ: 8 Tester
 SG_ XCP_Data_Req : 7|64@0+ (1,0) [0|4294967295] ""  Tester,PSCM
# Description: Contains XCP request data for calibration or measurement.
;TODO
;BO_ 1074 IS_DAT_BSI_432: 8 Tester
; SG_ ETAT_RESEAU_ELEC : 63|4@0+ (1,0) [0|15] ""  PSCM
; SG_ Power_Supplies : 52|3@0+ (1,0) [0|7] ""  PSCM
; SG_ Shunt_Position : 54|2@0+ (1,0) [0|3] ""  PSCM
; SG_ ETAT_PRINCIP_SEV : 49|2@0+ (1,0) [0|3] ""  PSCM
;TODO
;BO_ 840 IS_DYN2_CMM_348: 8 Tester
; SG_ ETAT_MT : 43|4@0+ (1,0) [0|15] ""  PSCM
;TODO
;BO_ 520 IS_DYN_CMM_208: 8 Tester
; SG_ DIAG_MUX_ON : 38|1@0+ (1,0) [0|1] ""  PSCM
;TODO
;BO_ 909 IS_DYN_ABR: 8 Tester
; SG_ VITESSE_VEHICULE_ROUES : 7|16@0+ (0.01,0) [0|655.34] "Kph"  PSCM
; SG_ CPT_PROCESS_4B_UC_FREIN : 47|4@0+ (1,0) [0|15] ""  PSCM
; SG_ CHKSUM_TRME_DYN_UC_FREIN : 43|4@0+ (1,0) [0|15] ""  PSCM

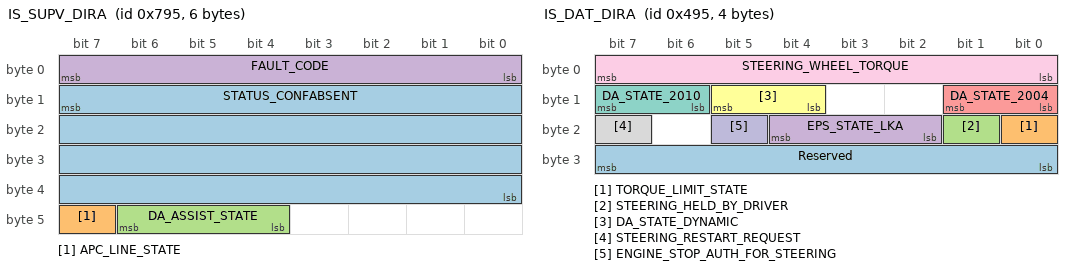
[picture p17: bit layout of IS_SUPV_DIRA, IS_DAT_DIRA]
BO_ 1941 IS_SUPV_DIRA: 6 PSCM
 SG_ STATUS_CONFABSENT : 15|32@0+ (1,0) [0|4294967295] ""  Tester
# Description: Indicates which supervised ECUs are confirmed absent or present in the DIRA context.

 SG_ APC_LINE_STATE : 47|1@0+ (1,0) [0|1] ""  Tester
# Description: Represents the line state for APC (auxiliary power control) in the steering system.

 SG_ DA_ASSIST_STATE : 46|3@0+ (1,0) [0|7] ""  Tester
# Description: Indicates the assistance state of the steering system.

 SG_ FAULT_CODE : 7|8@0+ (1,0) [0|255] ""  Tester
# Description: Represents a fault code within the DIRA supervision.

BO_ 1173 IS_DAT_DIRA: 4 PSCM
 SG_ Reserved : 31|8@0+ (1,0) [0|255] ""  Tester
# Description: Reserved byte.

 SG_ TORQUE_LIMIT_STATE : 16|1@0+ (1,0) [0|0] "" Vector__XXX
# Description: Indicates a torque limitation state in the steering system.

 SG_ STEERING_HELD_BY_DRIVER : 17|1@0+ (1,0) [0|0] "" Vector__XXX
# Description: Indicates whether the steering wheel is being held by the driver.

 SG_ EPS_STATE_LKA : 20|3@0+ (1,0) [0|0] "" Vector__XXX
# Description: Represents the EPS (electric power steering) state under lane-keeping assist.

 SG_ DA_STATE_2004 : 9|2@0+ (1,0) [0|3] ""  Tester
# Description: Indicates a specific internal steering assist state (version 2004).

 SG_ DA_STATE_DYNAMIC : 13|2@0+ (1,0) [0|3] ""  Tester
# Description: Indicates a dynamic state of the steering assist.

 SG_ DA_STATE_2010 : 15|2@0+ (1,0) [0|3] ""  Tester
# Description: Indicates a steering assist state (version 2010).

 SG_ STEERING_RESTART_REQUEST : 23|1@0+ (1,0) [0|1] ""  Tester
# Description: Represents a request to re-enable or restart steering assistance.

 SG_ STEERING_WHEEL_TORQUE : 7|8@0- (0.25,0) [-32|31.5] "Nm"  Tester
# Description: Represents the measured or estimated torque on the steering wheel in Nm.

 SG_ ENGINE_STOP_AUTH_FOR_STEERING : 21|1@0+ (1,0) [0|1] ""  Tester
# Description: Indicates whether the engine can be stopped without losing steering assistance.

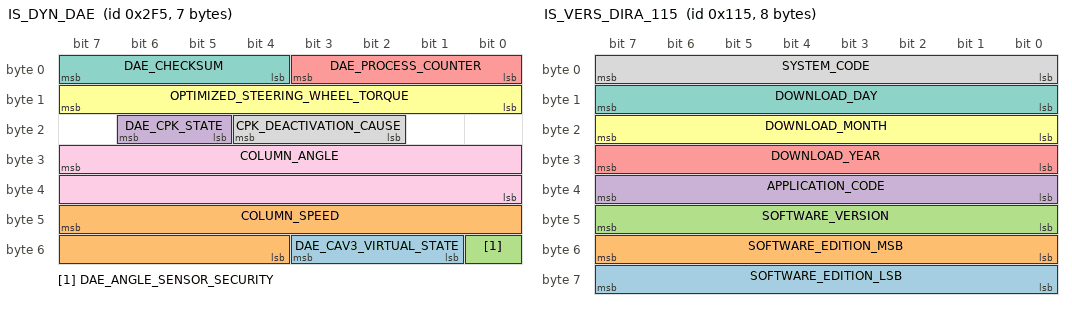
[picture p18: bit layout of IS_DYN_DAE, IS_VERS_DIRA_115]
BO_ 757 IS_DYN_DAE: 7 PSCM
 SG_ DAE_CAV3_VIRTUAL_STATE : 51|3@0+ (1,0) [0|7] "N/A" Vector__XXX
# Description: Represents a virtual state for the DAE (direction assist électrique) CAV3 parameter.

 SG_ COLUMN_SPEED : 47|12@0- (1,0) [-2000|2000] "Deg/s"  Tester
# Description: Represents the steering column speed in degrees per second.

 SG_ DAE_ANGLE_SENSOR_SECURITY : 48|1@0+ (1,0) [0|1] ""  Tester
# Description: Indicates a security or validity check for the steering column angle sensor.

 SG_ DAE_CPK_STATE : 22|2@0+ (1,0) [0|3] ""  Tester
# Description: Represents the state of the CPK within the DAE system.

 SG_ DAE_PROCESS_COUNTER : 3|4@0+ (1,0) [0|15] ""  Tester
# Description: 4-bit process counter for the DAE dynamic data.

 SG_ OPTIMIZED_STEERING_WHEEL_TORQUE : 15|8@0- (0.1,0) [-10|10] "Nm"  Tester
# Description: Represents the steering wheel torque with optimization or filtering.

 SG_ DAE_CHECKSUM : 7|4@0+ (1,0) [0|15] ""  Tester
# Description: Checksum for the DAE dynamic data.

 SG_ CPK_DEACTIVATION_CAUSE : 20|3@0+ (1,0) [0|7] ""  Tester
# Description: Indicates the reason or cause for CPK deactivation.

 SG_ COLUMN_ANGLE : 31|16@0- (0.1,0) [-1630|1630] "Deg"  Tester
# Description: Represents the steering column angle in degrees.

BO_ 277 IS_VERS_DIRA_115: 8 PSCM
 SG_ SOFTWARE_EDITION_LSB : 63|8@0+ (1,0) [0|255] ""  Tester
# Description: Least significant byte of the software edition identifier.

 SG_ SOFTWARE_EDITION_MSB : 55|8@0+ (1,0) [0|255] ""  Tester
# Description: Most significant byte of the software edition identifier.

 SG_ SOFTWARE_VERSION : 47|8@0+ (1,0) [0|255] ""  Tester
# Description: Represents the software version number.

 SG_ APPLICATION_CODE : 39|8@0+ (1,0) [0|255] ""  Tester
# Description: Code identifying a specific application variant.

 SG_ DOWNLOAD_YEAR : 31|8@0+ (1,0) [0|99] ""  Tester
# Description: The year of software download or installation.

 SG_ DOWNLOAD_MONTH : 23|8@0+ (1,0) [1|12] ""  Tester
# Description: The month of software download or installation.

 SG_ DOWNLOAD_DAY : 15|8@0+ (1,0) [1|31] ""  Tester
# Description: The day of software download or installation.

 SG_ SYSTEM_CODE : 7|8@0+ (1,0) [0|255] ""  Tester
# Description: Identifies the system code for the power steering application.

BO_ 1717 IS_REQ_DIAG_ON_CAN: 8 Tester
 SG_ DIAGNOSTIC_DATA_REQ : 7|64@0+ (1,0) [0|4294967295] ""  PSCM
# Description: Represents a general diagnostic data request on CAN.

BO_ 1685 IS_RES_DIAG_ON_CAN: 8 PSCM
 SG_ DIAGNOSTIC_DATA_RES : 7|64@0+ (1,0) [0|4294967295] ""  Tester
# Description: Represents a general diagnostic data response on CAN.

BO_TX_BU_ 773 : PSCM,Tester;
BO_TX_BU_ 1968 : Tester,PSCM;
BO_TX_BU_ 1966 : PSCM,Tester;
; #############################################################################
; ############################### HS1 CM ######################################
; #############################################################################
CM_ BO_ 1375 "trame utilisable uniquement pour le JDD en archi EE 2010";
CM_ BO_ 1554 "trame consommée uniquement sur véhicules en archi EE 2010";
CM_ BO_ 1362 "Trame utilisable uniquement sur véhicules en archi EE 2010

cette trame est émise toutes les 100ms pendant 1seconde puis toutes les secondes";
CM_ SG_ 1362 P015_Com_lTotDst "P015: covered distance from dashboard";
CM_ BO_ 1906 "Le mécanisme d'émission utilisé est événementiel de la BSI vers le CMM.

Trame d'acquittement du Journal Des Défauts BSI.";
CM_ BO_ 1294 "ID 50E: Body Car & Air Conditioning Data Frame (Period time 100 ms)";
CM_ SG_ 1294 P050_Com_stAC "P050  Fahrerwunsch Klimakompressor ein/aus ermitteln";
CM_ SG_ 1294 P164_Com_stPFltFan "P164:  Fan speed setpoint increase";
CM_ BO_ 1160 "ID 488:  Engine Data Frame (Period time 100 ms)";
CM_ SG_ 1160 P056_ACCD_p "P056  Kältemitteldruck";
CM_ SG_ 1160 P158_Air_tAFS "P158: Intake air temperature.";
CM_ SG_ 1160 P154_PFlt_bPFltClnReq "P154: Tell-tale lamp for \"risk of clogged filter\"";
CM_ SG_ 1160 P063_vehV_bXVVErr "P063  FGR-Fehler";
CM_ SG_ 1160 P108_Fid_ComAddPmpLvl "P106  Temperaturwarnlampe : blinken";
CM_ SG_ 1160 P105_Com_bTtLmp "P105  Temperaturwarnlampe: ein/aus";
CM_ SG_ 1160 P031_GlwLmp_st "P031  Ansteuerung Gluehanzeige";
CM_ SG_ 1160 P032_Com_bEngStrt "P032  Zustand Motor";
CM_ SG_ 1160 P021_Com_volFlCons "P021  Kraftstoffverbrauch";
CM_ SG_ 1160 P005_CEngDst_tSens "P005  Wassertemperatur";
CM_ BO_ 146 "Trame BSI émise toutes les 100 ms pendant 1 seconde.";

CM_ SG_ 1074 REQUEST_ENGINE_CUT "Request to cut off the internal combustion engine made by the vehicle to the CMM.";
CM_ SG_ 1074 REQUEST_STARTER_STOP "Request to stop the starter made by the vehicle to the CMM.";
CM_ SG_ 1074 WAKE_UP_CH "Request for height correction wake-up (RCD).";
CM_ SG_ 1074 WAKE_UP_ANTICIPATION_ADC "Request for wake-up for ADC anticipation (RCD).";
CM_ SG_ 1074 WAKE_UP_REQUEST_GEARBOX_STATE "Request to wake up the gearbox (RCD) to send gearbox state (engaged gear, lever position, etc.).";
CM_ SG_ 1074 WAKE_UP_MAIN "Request for the main wake-up (RCD).";
CM_ SG_ 1074 PROCESS_COUNTER_4B_BSI_1 "This counter increments from 0 to 15 at each activation of the calculation process.";
CM_ SG_ 1074 WAKE_UP_PREHEAT_FLEX "Request for wake-up (RCD) of BVMP. The Gearbox Power Pack (GEP) restores pressure to the hydraulic circuit.";
CM_ SG_ 1074 REQUEST_ENGINE_PREPARATION "Request to prepare the internal combustion engine for starting made by the vehicle to the CMM.";
CM_ SG_ 1074 REQUEST_IMPULSE_START "Impulsive start request made by the vehicle to the CMM.";
CM_ SG_ 1074 WAKE_UP_SUSPENSION_HEIGHT_CORRECTION "Partial wake-up request for pneumatic ride height correction (RCD).";
CM_ SG_ 1074 WAKE_UP_PREPARATION_STT "Partial wake-up issued by the BSI for the AR2S system.";
CM_ SG_ 1074 WAKE_UP_REQUEST_FSE_STATE "Request for wake-up for display needs.";
CM_ SG_ 1074 WAKE_UP_ENGINE_OIL_MEASUREMENT "Activates the acquisition of oil information upon request from the BSI.";
CM_ SG_ 1074 WAKE_UP_ENGINE_START_PREPARATION "Wake-up request (RCD) to prepare the engine start (gasoline).";
CM_ SG_ 1074 WAKE_UP_VEHICLE_SPEED_UC_BRAKE "Request to wake up the brake controller unit to send vehicle speed (RCD).";
CM_ SG_ 1074 WAKE_UP_PRECH_UCAPS "Partial wake-up issued by the BSI for the AR2S.";
CM_ SG_ 1074 WAKE_UP_PREPARATION_GEP "Wake-up request (RCD) of BVMP. The Gearbox Power Pack (GEP) restores pressure to the hydraulic circuit.";
CM_ SG_ 1074 STATE_MAIN_SEV "Main state of the SEV (vehicle electrical supervisor).";
CM_ SG_ 1074 CTX_JDD "Coding:
bit 7.7: Reserved
bits 7.6 to 7.5: BSI shunt position
bits 7.4 to 7.2: Power supply states
Refer to STE no. CSEO_APPT07_0032: JDD AEE2010 Packs A & B mechanisms.";

CM_ SG_ 1106 LONGITUDINAL_CONTROL_TYPE "Defines whether the vehicle is in LVV, RVV, ACC, or no longitudinal regulation mode.";
CM_ SG_ 1106 FRONT_WIPER_STATE "Emitted if a rain sensor is present.";
CM_ SG_ 1106 VEHICLE_SPEED_SETPOINT_OR_LIMIT "Setpoint or limit: depends on the value of the 'type of requested vehicle speed' bit.";
CM_ SG_ 1106 CHECKSUM_RVV_LVV2_COMMAND "Used to secure the RVV or LVV command transmitted over CAN (signal VEHICLE_SPEED_SETPOINT_OR_LIMIT).";
CM_ SG_ 1106 CHECKSUM_FRAME_4B_452 "CHK_INI = 0xB";

CM_ SG_ 1160 FUEL_CONSUMPTION "Fuel type can be gasoline, diesel, LPG, etc.";
CM_ SG_ 1160 MINIMUM_ADDITIVE_LEVEL_ALERT "Information to the driver to refill the additive in the after-sales network.";
CM_ SG_ 1160 REQUEST_INDICATOR_COLD_START "Illuminates an indicator to signal that a cold start will be difficult.";
CM_ SG_ 1160 COMBUSTION_MISFIRES "This information warns of a high risk of catalyst deterioration on a gasoline engine.";
CM_ SG_ 1160 PREHEATING_GLOWPLUGS "Activating glowplugs implies cutting LUCH by the BSI to maintain driving comfort in FAP1 context.";
CM_ SG_ 1160 FUEL_CONSUMPTION_INFO_TYPE "Type of fuel consumption information used for FAP2 to get pseudo consumption. Applies to FAP2 usage.";
CM_ SG_ 1160 RISK_FILTER_CLOGGING "Indicates to the driver that a regeneration is required via adapted driving behavior.";
CM_ SG_ 1160 FORCED_PRESSURE_AUTOMATIC_GEARBOX "The goal is to load the alternator (and thus the engine) to facilitate regeneration by increasing injection flow.";
CM_ SG_ 1160 ENGINE_INTAKE_AIR_TEMPERATURE "Signal from the air temperature sensor in the intake system. This sensor is located on the throttle body or the flow meter in gasoline engines, and on the flow meter in diesel engines.";

CM_ BO_ 1170 "VDS frame used to identify the vehicle model (Vehicle Description Section)";

CM_ SG_ 1170 VDS_1 "First VDS character.";
CM_ SG_ 1170 VDS_2 "Second VDS character.";
CM_ SG_ 1170 VDS_3 "Third VDS character.";
CM_ SG_ 1170 VDS_4 "Fourth VDS character.";
CM_ SG_ 1170 VDS_5 "Fifth VDS character.";
CM_ SG_ 1170 VDS_6 "Sixth VDS character.";

CM_ BO_ 1202 "VIS frame used to identify the vehicle production number (Vehicle Identification Section)";

CM_ SG_ 1202 VIS_1 "First VIS character.";
CM_ SG_ 1202 VIS_2 "Second VIS character.";
CM_ SG_ 1202 VIS_3 "Third VIS character.";
CM_ SG_ 1202 VIS_4 "Fourth VIS character.";
CM_ SG_ 1202 VIS_5 "Fifth VIS character.";
CM_ SG_ 1202 VIS_6 "Sixth VIS character.";
CM_ SG_ 1202 VIS_7 "Seventh VIS character.";
CM_ SG_ 1202 VIS_8 "Eighth VIS character.";

CM_ BO_ 1234 "WMI frame used to identify the vehicle manufacturer (World Manufacturer Identifier)";

CM_ SG_ 1234 WMI_1 "First WMI character.";
CM_ SG_ 1234 WMI_2 "Second WMI character.";
CM_ SG_ 1234 WMI_3 "Third WMI character.";

CM_ BO_ 1294 "Mixed frame: periodic at 100 ms and on events:
     Change of vehicle speed setpoint
     Request to activate RVV / ACC
     Request to activate LVV";

CM_ SG_ 1294 CHECKSUM_RVV_LVV_COMMAND "Used to secure the RVV or LVV command transmitted over CAN (signal VEHICLE_SPEED_SETPOINT_OR_LIMIT).";
CM_ SG_ 1294 GMV_SETPOINT "Used in the context of the particulate filter (FAP) to load the engine from the BSI by activating the cooling fans (GMV).";
CM_ SG_ 1294 FORCED_GLOWPLUG_ENGAGEMENT "Used to load the engine under low speed/load conditions to facilitate regeneration by engaging glowplugs.";
CM_ SG_ 1294 VEHICLE_LOAD_SHEDDING_LEVEL "Load shedding level for high-power consumers determined by the vehicle electrical energy supervisor.";
CM_ SG_ 1294 REQUEST_CABIN_ENERGY "Describes the energy needed from the internal combustion engine for cabin needs (air conditioning, etc.).";
CM_ SG_ 1294 REQUEST_INCREASE_IDLE_SPEED "Requests an idle speed increase for cabin needs (e.g., air conditioning).";
CM_ SG_ 1294 VEHICLE_SPEED_SETPOINT_OR_LIMIT "Setpoint or limit: depends on the value of the 'type of requested vehicle speed' bit.";
CM_ SG_ 1294 LONGITUDINAL_CONTROL_TYPE "Defines whether the vehicle is in LVV, RVV, ACC, or no longitudinal regulation mode.";

CM_ SG_ 1362 TIME_COUNTER "0xFFFFFFFE: unavailable.";
CM_ SG_ 1362 ODOMETER "Absolute mileage covered by the vehicle (consistent with the driver display).";
CM_ SG_ 1362 RESET_COUNTER_GCT "Unavailable FE.";

CM_ BO_ 1375 "Acknowledgment frame for the BSI fault log.";

CM_ BO_ 1389 "Emitted to the Bosch triple-sensor for that sensor’s response in frame 0x579.";

CM_ BO_ 1420 "Response frame for download and Diag On CAN reserved for dual sensor.";

CM_ SG_ 1426 SWITCHING_SYSTEM_FAULT "Indicates a failure of the wired line CDE_ALIM_FSE and the switching system (CPC, BPGA, etc.).";
CM_ SG_ 1426 WIPER_STATE "Emitted if a rain sensor is present.";

CM_ BO_ 1452 "Question frame for download and Diag On CAN reserved for the ACC ECU.";

CM_ BO_ 1455 "Response frame for download and Diag On CAN reserved for dual sensor.";

CM_ BO_ 1456 "Question frame for download and Diag On CAN reserved for the ACC ECU.";

CM_ BO_ 1484 "This frame groups instrumentation data to assess transmission quality and to determine if at least one fault is present on the ECU. This frame is not involved in normal-mode operation of the ECUs.";

CM_ SG_ 1484 FAULT_CODE "Status of the system diagnostic memory.";
CM_ SG_ 1484 STATUS_CONFIRMED_ABSENCE "Copies the status flags of supervised ECUs, ConfirmedAbsent information (refer to communication diagnostic specification). For each ECU, the bit is 0 if the ECU is present, or 1 if it is Confirmed Absent. If an ECU is not supervised, its corresponding bit is set to 0 by default.";
CM_ SG_ 1484 PARTIAL_WAKE_UP_STATUS_GMP "Allows each ECU to indicate which partial wake-up(s) is (are) activated or not. This applies to both master and slave ECUs for partial wake-up.";
CM_ SG_ 1484 ELECTRICAL_STATE_ECU "Electrical life phase of the ECU (RCD).";

CM_ BO_ 1487 "Response frame for download and Diag On CAN reserved for dual sensor.";

CM_ BO_ 1488 "Question frame for download and Diag On CAN reserved for the ACC ECU.";

CM_ BO_ 1489 "This frame groups instrumentation data to assess transmission quality and to determine if at least one fault is present on the ECU. This frame is not involved in normal-mode operation of the ECUs.";

CM_ SG_ 1489 FAULT_CODE "Status of the system diagnostic memory.";
CM_ SG_ 1489 STATUS_CONFIRMED_ABSENCE "Copies the status flags of supervised ECUs, ConfirmedAbsent information (refer to communication diagnostic specification). For each ECU, the bit is 0 if the ECU is present, or 1 if it is Confirmed Absent. If an ECU is not supervised, its corresponding bit is set to 0 by default.";
CM_ SG_ 1489 PARTIAL_WAKE_UP_STATUS_LAS "Allows each ECU to indicate which partial wake-up(s) is (are) activated or not. This applies to both master and slave ECUs for partial wake-up.";
CM_ SG_ 1489 ELECTRICAL_STATE_ECU "Electrical life phase of the ECU (RCD).";

CM_ BO_ 1516 "Emission frame of the fault log from the DIRA or GEP ECU.";

CM_ SG_ 1516 FAULT_CODES "The fault coding is:
Byte 1: MSB,
Byte 2: LSB,
Byte 3: 0x00.";

CM_ SG_ 1516 TOTAL_VEHICLE_ODOMETER_FAULT_LOG "Absolute mileage traveled by the vehicle (consistent with the information provided to the driver)";
# Description: Indicates the absolute vehicle odometer reading used for fault logging purposes.

CM_ SG_ 1516 FAULT_LOG_LIFECYCLE_SITUATION "Described in ST JDD SOUS_CAPOT";
# Description: Specifies the operating or lifecycle situation for the fault log under the hood.

CM_ BO_ 1519 "Transmission frame for the fault log of the DIRA or GEP ECU.";

CM_ SG_ 1519 FAULT_CODES "The fault coding corresponds to:
Byte 1: MSB,
Byte 2: LSB,
Byte 3: 0x00.";
# Description: Represents the encoded fault information (MSB, LSB, and filler byte).

CM_ SG_ 1519 TOTAL_VEHICLE_ODOMETER_FAULT_LOG "Absolute mileage traveled by the vehicle (consistent with the information provided to the driver)";
# Description: Indicates the absolute vehicle odometer reading used for fault logging purposes.

CM_ SG_ 1519 FAULT_LOG_LIFECYCLE_SITUATION "Described in ST JDD SOUS_CAPOT";
# Description: Specifies the operating or lifecycle situation for the fault log under the hood.

CM_ BO_ 1520 "This frame groups instrumentation data used to assess the transmission quality and to determine if at least one fault is present on the ECU. This frame is not involved in normal operating mode.";

CM_ SG_ 1520 FAULT_CODE "State of the system diagnostic memory";
# Description: Indicates whether any faults are stored in the system’s diagnostic memory.

CM_ SG_ 1520 CONFIRMED_ABSENCE_STATUS "Echoes the status flags of supervised ECUs, representing a confirmed absence (Refer to the communication diagnostic specification). For each ECU, the bit is 0 if the ECU is present, or 1 if it is confirmed absent.
If an ECU is not supervised, the corresponding bit is set to 0 by default.";
# Description: Signals which ECUs are confirmed absent as per supervision flags.

CM_ SG_ 1520 PARTIAL_WAKEUP_STATUS_LAS "This flag allows each ECU to indicate which partial wake-ups are active or not. It applies to both master partial wake-up ECUs and slave ECUs (those to be woken).";
# Description: Indicates the partial wake-up status (LAS) used by master and slave ECUs alike.

CM_ SG_ 1520 UCE_ELECTRICAL_STATE "Life phase of the UCE (RCD)";
# Description: Denotes the electrical or power state of the ECU across its lifecycle.

CM_ BO_ 1521 "Transmission frame for the fault log of the DIRA or GEP ECU.";

CM_ SG_ 1521 FAULT_CODES "The fault coding corresponds to:
Byte 1: MSB,
Byte 2: LSB,
Byte 3: 0x00.";
# Description: Represents the encoded fault information (MSB, LSB, and filler byte).

CM_ SG_ 1521 TOTAL_VEHICLE_ODOMETER_FAULT_LOG "Absolute mileage traveled by the vehicle (consistent with the information provided to the driver)";
# Description: Indicates the absolute vehicle odometer reading used for fault logging purposes.

CM_ SG_ 1521 FAULT_LOG_LIFECYCLE_SITUATION "Described in ST JDD SOUS_CAPOT";
# Description: Specifies the operating or lifecycle situation for the fault log under the hood.

CM_ BO_ 1686 "Response frame for download and Diag On CAN reserved for the ACC ECU.";

CM_ BO_ 1689 "Response frame for download and Diag On CAN reserved for the dual sensor.";

CM_ BO_ 1693 "Response frame for download and Diag On CAN.";

CM_ BO_ 1718 "Query frame for download and Diag On CAN reserved for the ACC ECU.";

CM_ BO_ 1721 "Query frame for download and Diag On CAN reserved for the dual sensor.";

CM_ BO_ 1910 "Transmission frame for the fault log of the DIRA or GEP ECU.";

CM_ SG_ 1910 FAULT_CODES "The fault coding corresponds to:
Byte 1: MSB,
Byte 2: LSB,
Byte 3: 0x00.";
# Description: Represents the encoded fault information (MSB, LSB, and filler byte).

CM_ SG_ 1910 TOTAL_VEHICLE_ODOMETER_FAULT_LOG "Absolute mileage traveled by the vehicle (consistent with the information provided to the driver)";
# Description: Indicates the absolute vehicle odometer reading used for fault logging purposes.

CM_ SG_ 1910 FAULT_LOG_LIFECYCLE_SITUATION "Described in ST JDD SOUS_CAPOT";
# Description: Specifies the operating or lifecycle situation for the fault log under the hood.

CM_ BO_ 1917 "Transmission frame for the fault log of the DIRA or GEP ECU.";

CM_ SG_ 1917 FAULT_CODES "The fault coding corresponds to:
Byte 1: MSB,
Byte 2: LSB,
Byte 3: 0x00.";
# Description: Represents the encoded fault information (MSB, LSB, and filler byte).

CM_ SG_ 1917 TOTAL_VEHICLE_ODOMETER_FAULT_LOG "Absolute mileage traveled by the vehicle (consistent with the information provided to the driver)";
# Description: Indicates the absolute vehicle odometer reading used for fault logging purposes.

CM_ SG_ 1917 FAULT_LOG_LIFECYCLE_SITUATION "Described in ST JDD SOUS_CAPOT";
# Description: Specifies the operating or lifecycle situation for the fault log under the hood.

CM_ BO_ 1938 "This frame groups instrumentation data used to assess the transmission quality and to determine if at least one fault is present on the ECU, and provides the ECU life phase (RCD). This frame is not involved in normal operation.";

CM_ SG_ 1938 FAULT_CODE "State of the system diagnostic memory";
# Description: Indicates whether any faults are stored in the system’s diagnostic memory.

CM_ SG_ 1938 CONFIRMED_ABSENCE_STATUS "Echoes the status flags of supervised ECUs, representing a confirmed absence (Refer to the communication diagnostic specification). For each ECU, the bit is 0 if the ECU is present, or 1 if it is confirmed absent.
If an ECU is not supervised, the corresponding bit is set to 0 by default.";
# Description: Signals which ECUs are confirmed absent as per supervision flags.

CM_ SG_ 1938 PARTIAL_WAKEUP_STATUS "This flag allows each ECU to indicate which partial wake-ups are active or not. It applies to both master partial wake-up ECUs and slave ECUs (those to be woken).";
# Description: Indicates the partial wake-up status used by master and slave ECUs alike.

CM_ SG_ 1938 UCE_ELECTRICAL_STATE "Life phase of the UCE (RCD)";
# Description: Denotes the electrical or power state of the ECU across its lifecycle.

CM_ BO_ 1942 "This frame groups instrumentation data used to assess the transmission quality and to determine if at least one fault is present on the ECU. This frame is not involved in normal operation.";

CM_ SG_ 1942 FAULT_CODE "State of the system diagnostic memory";
# Description: Indicates whether any faults are stored in the system’s diagnostic memory.

CM_ SG_ 1942 CONFIRMED_ABSENCE_STATUS "Echoes the status flags of supervised ECUs, representing a confirmed absence (Refer to the communication diagnostic specification). For each ECU, the bit is 0 if the ECU is present, or 1 if it is confirmed absent.
If an ECU is not supervised, the corresponding bit is set to 0 by default.";
# Description: Signals which ECUs are confirmed absent as per supervision flags.

CM_ SG_ 1942 PARTIAL_WAKEUP_STATUS_GMP "This flag allows each ECU to indicate which partial wake-ups are active or not. It applies to both master partial wake-up ECUs and slave ECUs (those to be woken).
All possible combinations are allowed.";
# Description: Indicates the partial wake-up status (GMP) used by master and slave ECUs alike.

CM_ SG_ 1942 UCE_ELECTRICAL_STATE "Life phase of the UCE (RCD)";
# Description: Denotes the electrical or power state of the ECU across its lifecycle.

CM_ SG_ 1949 FAULT_CODE "State of the system diagnostic memory";
# Description: Indicates whether any faults are stored in the system’s diagnostic memory.

CM_ SG_ 1949 CONFIRMED_ABSENCE_STATUS "Echoes the status flags of supervised ECUs, representing a confirmed absence (Refer to the communication diagnostic specification). For each ECU, the bit is 0 if the ECU is present, or 1 if it is confirmed absent.
If an ECU is not supervised, the corresponding bit is set to 0 by default.";
# Description: Signals which ECUs are confirmed absent as per supervision flags.

CM_ SG_ 1949 UCE_ELECTRICAL_STATE "Life phase of the UCE (RCD)";
# Description: Denotes the electrical or power state of the ECU across its lifecycle.
; #############################################################################
; ############################### EPS CM ######################################
; #############################################################################
BA_DEF_ BO_  "???" HEX 0 0;
BA_DEF_DEF_  "???" 0;
; #############################################################################
; ############################### HS2 BA ######################################
; #############################################################################
BA_DEF_ BO_  "ModeTransmission" ENUM  "P","E","P+E";
BA_DEF_ BO_  "Période" INT 0 0;
BA_DEF_DEF_  "ModeTransmission" "P";
BA_DEF_DEF_  "Période" 100;
BA_ "Période" BO_ 146 0;
BA_ "ModeTransmission" BO_ 146 1;
BA_ "Période" BO_ 1074 50;
BA_ "Période" BO_ 1080 50;
BA_ "Période" BO_ 1106 50;
BA_ "Période" BO_ 1170 1000;
BA_ "Période" BO_ 1202 1000;
BA_ "Période" BO_ 1234 1000;
BA_ "ModeTransmission" BO_ 1294 2;
BA_ "Période" BO_ 1356 200;
BA_ "ModeTransmission" BO_ 1356 2;
BA_ "Période" BO_ 1362 1000;
BA_ "ModeTransmission" BO_ 1362 2;
BA_ "Période" BO_ 1375 0;
BA_ "ModeTransmission" BO_ 1375 1;
BA_ "Période" BO_ 1389 0;
BA_ "ModeTransmission" BO_ 1389 1;
BA_ "ModeTransmission" BO_ 1393 2;
BA_ "Période" BO_ 1401 0;
BA_ "ModeTransmission" BO_ 1401 1;
BA_ "Période" BO_ 1420 0;
BA_ "ModeTransmission" BO_ 1420 1;
BA_ "Période" BO_ 1448 1000;
BA_ "ModeTransmission" BO_ 1448 2;
BA_ "Période" BO_ 1449 1000;
BA_ "Période" BO_ 1452 0;
BA_ "ModeTransmission" BO_ 1452 1;
BA_ "Période" BO_ 1455 0;
BA_ "ModeTransmission" BO_ 1455 1;
BA_ "Période" BO_ 1456 0;
BA_ "ModeTransmission" BO_ 1456 1;
BA_ "Période" BO_ 1464 1000;
BA_ "Période" BO_ 1484 1000;
BA_ "ModeTransmission" BO_ 1484 2;
BA_ "Période" BO_ 1487 0;
BA_ "ModeTransmission" BO_ 1487 1;
BA_ "Période" BO_ 1488 0;
BA_ "ModeTransmission" BO_ 1488 1;
BA_ "Période" BO_ 1489 1000;
BA_ "ModeTransmission" BO_ 1489 2;
BA_ "Période" BO_ 1490 1000;
BA_ "ModeTransmission" BO_ 1490 2;
BA_ "Période" BO_ 1496 1000;
BA_ "Période" BO_ 1516 0;
BA_ "ModeTransmission" BO_ 1516 1;
BA_ "Période" BO_ 1517 300;
BA_ "Période" BO_ 1518 1000;
BA_ "ModeTransmission" BO_ 1518 2;
BA_ "Période" BO_ 1519 0;
BA_ "ModeTransmission" BO_ 1519 1;
BA_ "Période" BO_ 1520 1000;
BA_ "ModeTransmission" BO_ 1520 2;
BA_ "Période" BO_ 1521 0;
BA_ "ModeTransmission" BO_ 1521 1;
BA_ "Période" BO_ 1686 0;
BA_ "ModeTransmission" BO_ 1686 1;
BA_ "Période" BO_ 1689 0;
BA_ "ModeTransmission" BO_ 1689 1;
BA_ "Période" BO_ 1693 0;
BA_ "ModeTransmission" BO_ 1693 1;
BA_ "Période" BO_ 1718 0;
BA_ "ModeTransmission" BO_ 1718 1;
BA_ "Période" BO_ 1721 0;
BA_ "ModeTransmission" BO_ 1721 1;
BA_ "Période" BO_ 1725 0;
BA_ "ModeTransmission" BO_ 1725 1;
BA_ "Période" BO_ 1910 0;
BA_ "ModeTransmission" BO_ 1910 1;
BA_ "Période" BO_ 1917 0;
BA_ "ModeTransmission" BO_ 1917 1;
BA_ "Période" BO_ 1938 1000;
BA_ "ModeTransmission" BO_ 1938 2;
BA_ "Période" BO_ 1942 1000;
BA_ "Période" BO_ 1949 1000;
BA_ "ModeTransmission" BO_ 1949 2;
BA_ "Période" BO_ 2047 0;
BA_ "ModeTransmission" BO_ 2047 1;
; #############################################################################
; ############################### EPS BA ######################################
; #############################################################################
BA_DEF_ BO_  "GenMsgStartDelayTime" INT 0 65535;
BA_DEF_ BO_  "GenMsgMinAcceptLength" INT -1 8;
BA_DEF_ BO_  "DiagState" ENUM  "No","Yes";
BA_DEF_ BO_  "GenMsgDelayTime" INT 0 65535;
BA_DEF_ SG_  "GenSigSendType" ENUM  "Cyclic","OnWrite","OnWriteWithRepetition","OnChange","OnChangeWithRepetition","IfActive","IfActiveWithRepetition","NoSigSendType","OnChangeAndIfActive","OnChangeAndIfActiveWithRepetition";
BA_DEF_ BO_  "GenMsgILSupport" ENUM  "No","Yes";
BA_DEF_ BO_  "DiagResponse" ENUM  "No","Yes";
BA_DEF_ BO_  "DiagRequest" ENUM  "No","Yes";
BA_DEF_ BO_  "GenMsgCycleTime" INT 0 65535;
BA_DEF_ BO_  "GenMsgSendType" ENUM  "Cyclic","NotUsed","NotUsed","NotUsed","NotUsed","NotUsed","NotUsed","IfActive","NoMsgSendType";
BA_DEF_ SG_  "GenSigStartValue" INT 0 1000000000;
BA_DEF_DEF_  "GenMsgStartDelayTime" 0;
BA_DEF_DEF_  "GenMsgMinAcceptLength" -1;
BA_DEF_DEF_  "DiagState" "No";
BA_DEF_DEF_  "GenMsgDelayTime" 0;
BA_DEF_DEF_  "GenSigSendType" "NoSigSendType";
BA_DEF_DEF_  "GenMsgILSupport" "No";
BA_DEF_DEF_  "DiagResponse" "No";
BA_DEF_DEF_  "DiagRequest" "No";
BA_DEF_DEF_  "GenMsgCycleTime" 0;
BA_DEF_DEF_  "GenMsgSendType" "NoMsgSendType";
BA_DEF_DEF_  "GenSigStartValue" 0;
BA_ "GenMsgILSupport" BO_ 1485 1;
BA_ "GenMsgSendType" BO_ 1485 0;
BA_ "GenMsgCycleTime" BO_ 1485 1000;
BA_ "GenMsgMinAcceptLength" BO_ 1485 4;
BA_ "GenMsgSendType" BO_ 1394 0;
BA_ "GenMsgCycleTime" BO_ 1394 100;
BA_ "GenMsgILSupport" BO_ 1394 1;
BA_ "GenMsgMinAcceptLength" BO_ 1394 2;
BA_ "GenMsgMinAcceptLength" BO_ 1293 1;
BA_ "GenMsgILSupport" BO_ 1293 1;
BA_ "GenMsgCycleTime" BO_ 1293 100;
BA_ "GenMsgSendType" BO_ 1293 0;
BA_ "GenMsgILSupport" BO_ 1906 1;
BA_ "GenMsgMinAcceptLength" BO_ 1906 1;
BA_ "GenMsgMinAcceptLength" BO_ 1375 1;
BA_ "GenMsgILSupport" BO_ 1375 1;
BA_ "GenMsgILSupport" BO_ 1909 1;
BA_ "GenMsgMinAcceptLength" BO_ 1362 5;
BA_ "GenMsgILSupport" BO_ 1362 1;
BA_ "GenMsgCycleTime" BO_ 1362 1000;
BA_ "GenMsgSendType" BO_ 1362 0;
BA_ "GenMsgMinAcceptLength" BO_ 1010 3;
BA_ "GenMsgILSupport" BO_ 1010 1;
BA_ "GenMsgCycleTime" BO_ 1010 50;
BA_ "GenMsgSendType" BO_ 1010 0;
BA_ "GenMsgMinAcceptLength" BO_ 146 1;
BA_ "GenMsgILSupport" BO_ 146 1;
BA_ "GenMsgCycleTime" BO_ 146 100;
BA_ "GenMsgSendType" BO_ 146 7;
BA_ "GenMsgMinAcceptLength" BO_ 773 5;
BA_ "GenMsgSendType" BO_ 773 0;
BA_ "GenMsgCycleTime" BO_ 773 10;
BA_ "GenMsgILSupport" BO_ 773 1;
BA_ "GenMsgMinAcceptLength" BO_ 747 4;
BA_ "GenMsgCycleTime" BO_ 747 20;
BA_ "GenMsgSendType" BO_ 747 0;
BA_ "GenMsgMinAcceptLength" BO_ 2047 8;
BA_ "DiagState" BO_ 2047 1;
BA_ "GenMsgMinAcceptLength" BO_ 1968 0;
BA_ "GenMsgMinAcceptLength" BO_ 1966 0;
BA_ "GenMsgMinAcceptLength" BO_ 1074 8;
BA_ "GenMsgILSupport" BO_ 1074 1;
BA_ "GenMsgSendType" BO_ 1074 0;
BA_ "GenMsgCycleTime" BO_ 1074 50;
BA_ "GenMsgILSupport" BO_ 1941 1;
BA_ "GenMsgCycleTime" BO_ 1941 1000;
BA_ "GenMsgSendType" BO_ 1941 0;
BA_ "GenMsgStartDelayTime" BO_ 1941 5;
BA_ "GenMsgDelayTime" BO_ 1941 10;
BA_ "GenMsgILSupport" BO_ 1173 1;
BA_ "GenMsgCycleTime" BO_ 1173 100;
BA_ "GenMsgSendType" BO_ 1173 0;
BA_ "GenMsgSendType" BO_ 757 0;
BA_ "GenMsgCycleTime" BO_ 757 10;
BA_ "GenMsgILSupport" BO_ 757 1;
BA_ "GenMsgStartDelayTime" BO_ 757 5;
BA_ "GenMsgILSupport" BO_ 277 1;
BA_ "GenMsgMinAcceptLength" BO_ 1717 8;
BA_ "GenMsgSendType" BO_ 1717 1;
BA_ "DiagRequest" BO_ 1717 1;
BA_ "GenMsgSendType" BO_ 1685 1;
BA_ "DiagResponse" BO_ 1685 1;
BA_ "GenSigStartValue" SG_ 1909 Type_of_Message 1;
BA_ "GenSigStartValue" SG_ 1909 Number_of_Frames 2;
BA_ "GenSigSendType" SG_ 1909 Frame_Number 1;
BA_ "GenSigStartValue" SG_ 773 ANGLE_VOLANT_ORIGINE 3;
BA_ "GenSigStartValue" SG_ 773 TRIM_VOL 1;
BA_ "GenSigStartValue" SG_ 773 CALIBRATION_VOL 1;
BA_ "GenSigStartValue" SG_ 773 ETAT_CAPT_VOL 1;
BA_ "GenSigSendType" SG_ 1941 CONFIRMED_ABSENCE_STATUS 3;
BA_ "GenSigSendType" SG_ 1941 ETAT_LIGNE_APC 3;
BA_ "GenSigSendType" SG_ 1941 ETAT_ASSIST_DA 3;
BA_ "GenSigSendType" SG_ 1941 CODE_DEFAUT 3;
BA_ "GenSigStartValue" SG_ 1173 Reserved 60;
BA_ "GenSigStartValue" SG_ 1173 CPLE_VOLANT 127;
BA_ "GenSigStartValue" SG_ 757 CHKSUM_TRME_DYN_DAE 4;
BA_ "GenSigSendType" SG_ 277 Software_Edition_LSB 1;
BA_ "GenSigSendType" SG_ 277 Software_Edition_MSB 1;
BA_ "GenSigSendType" SG_ 277 Software_Version 1;
BA_ "GenSigSendType" SG_ 277 Application_Code 1;
BA_ "GenSigSendType" SG_ 277 Download_Year 1;
BA_ "GenSigSendType" SG_ 277 Download_Month 1;
BA_ "GenSigStartValue" SG_ 277 Download_Month 1;
BA_ "GenSigSendType" SG_ 277 Download_Day 1;
BA_ "GenSigStartValue" SG_ 277 Download_Day 1;
BA_ "GenSigSendType" SG_ 277 System_Code 1;
; #############################################################################
; ############################### HS1 VAL #####################################
; #############################################################################
VAL_ 146 ERASE_DIAGNOSTIC_FAULT 0 "No specific action" 1 "Erase fault memory";
VAL_ 146 DIAGNOSTIC_OPERATION_MODE 0 "No particular operation" 1 "Functional and communication inhibited";
VAL_ 146 ELECTRICAL_INTEGRITY_DIAGNOSTIC_STATUS 0 "No particular operation" 1 "No frame transmission";
VAL_ 1074 ENGINE_COUPLING_REQUEST 0 "Forbidden" 1 "No request to stop ICE" 2 "Request to stop ICE" 3 "Forbidden";
VAL_ 1074 STARTER_STOP_REQUEST 0 "No starter stop request" 1 "Starter stop request";
VAL_ 1074 WAKEUP_REQUEST_CH 0 "No wake-up request" 1 "Wake-up request";
VAL_ 1074 ANTICIPATION_ADC_WAKEUP_REQUEST 0 "No wake-up request" 1 "Wake-up request";
VAL_ 1074 GEARBOX_STATE_REQUEST_WAKEUP 0 "No wake-up request" 1 "Wake-up request";
VAL_ 1074 MAIN_WAKEUP_REQUEST 0 "RCD Invalid" 1 "No main wake-up request" 2 "Main wake-up request" 3 "Invalid";
VAL_ 1074 START_INTENTION 0 "Reserved" 1 "No start intention" 2 "Start intention" 3 "Reserved";
VAL_ 1074 FLEX_PREHEAT_WAKEUP_REQUEST 0 "No wake-up request" 1 "Wake-up request";
VAL_ 1074 PRE_POST_HEATING_PEOPLE_REQUEST 0 "No request" 1 "Request";
VAL_ 1074 POST_HEATING_PEOPLE_REQUEST 0 "No request" 1 "Request";
VAL_ 1074 PRIORITY_ELECTRICAL_CONSUMER 0 "No priority electrical consumer engaged" 1 "A priority electrical consumer is engaged";
VAL_ 1074 HADC_ENABLE_REQUEST 0 "No activation request" 1 "HADC activation request";
VAL_ 1074 ENGINE_PREPARATION_REQUEST 0 "No engine preparation request" 1 "Engine preparation request";
VAL_ 1074 IMPULSIVE_START_REQUEST 0 "Forbidden" 1 "No impulsive start request" 2 "Impulsive start request" 3 "Forbidden";
VAL_ 1074 TIRE_PRESSURE_CORRECTION_WAKEUP_REQUEST 0 "No wake-up request" 1 "Wake-up request";
VAL_ 1074 STT_PREPARATION_WAKEUP_REQUEST 0 "No wake-up request" 1 "Wake-up request";
VAL_ 1074 FSE_STATE_REQUEST_WAKEUP 0 "No wake-up request" 1 "Wake-up request";
VAL_ 1074 MECATRONIC_HEADLAMP_REQ 0 "OFF" 1 "ON";
VAL_ 1074 ENGINE_OIL_MEAS_WAKEUP_REQUEST 0 "No wake-up request" 1 "Wake-up request";
VAL_ 1074 VEHICLE_OVERLOAD_WAKEUP_REQUEST 0 "Off" 1 "On";
VAL_ 1074 ENGINE_START_PREPARATION_WAKEUP_REQUEST 0 "No wake-up request" 1 "Wake-up request";
VAL_ 1074 BRAKE_UCF_PARTIAL_WAKEUP_REQUEST 0 "No partial wake-up request" 1 "Partial wake-up requested";
VAL_ 1074 START_REQUEST_STATUS 0 "Nominal request" 1 "Secondary request";
VAL_ 1074 UCAPS_PREHEAT_WAKEUP_REQUEST 0 "No wake-up request" 1 "Wake-up request";
VAL_ 1074 ENGINE_POST_VENTILATION_WAKEUP_REQUEST 0 "No wake-up request" 1 "Wake-up request";
VAL_ 1074 GEP_PREPARATION_WAKEUP_REQUEST 0 "No wake-up request" 1 "Wake-up request";
VAL_ 1074 MAIN_SAFETY_STATE 0 "Stop" 1 "Ignition on" 2 "Start" 3 "Reserved";
VAL_ 1074 GENERAL_START_INTENTION 0 "Unused value" 1 "Start intention" 2 "No start intention" 3 "Unused value";
VAL_ 1074 PUSH_POWERTRAIN_ECO 0 "Eco mode not requested" 1 "Eco mode requested";
VAL_ 1074 POWER_LATCH_HY_WAKEUP_REQUEST 0 "No power latch wake-up request" 1 "Power latch wake-up request";
VAL_ 1074 ELECTRICAL_NETWORK_STATE 0 "TI_NOMINAL" 1 "TI_DEGRADE" 2 "TI_DISPO_DEM" 3 "STARTING" 4 "RESTARTING" 5 "TA_NOMINAL" 6 "TA_DEGRADE" 7 "TA_SECU" 8 "Reserved" 9 "Reserved" 10 "Reserved" 11 "Reserved" 12 "Reserved" 13 "Reserved" 14 "Reserved" 15 "Reserved";
VAL_ 1106 LONGITUDINAL_REGULATION_TYPE 0 "None" 1 "RVV: vehicle speed regulator" 2 "LVV: vehicle speed limiter" 3 "ACC: automatic vehicle speed regulator";
VAL_ 1106 TURN_SIGNALS_STATE 0 "Turn signal inactive" 1 "Right turn signal active" 2 "Left turn signal active" 3 "Both signals active";
VAL_ 1106 FRONT_WIPING_STATE 0 "Off" 1 "Front wiping confirmed" 2 "Low speed" 3 "High speed";
VAL_ 1106 CHKSUM_CONS_RVV_LVV2 0 "High nibble of CONS_LIM_VITESSE_VEH even & low nibble even" 1 "High nibble even & low nibble odd" 2 "High nibble odd & low nibble even" 3 "High nibble odd & low nibble odd";
VAL_ 1106 BRAKE_ONLY_REQUEST_BSI 0 "No brake only requested by BSI" 1 "Brake only requested by BSI";
VAL_ 1106 LVV_ACTIVATION_REQUEST 0 "No LVV activation request" 1 "LVV activation request";
VAL_ 1106 RVV_ACC_ACTIVATION_REQUEST 0 "No RVV or ACC activation request" 1 "RVV or ACC activation request";
VAL_ 1106 ARC_SENSITIVITY_SETTING 0 "Not used" 1 "1" 2 "2" 3 "3" 4 "Not used" 5 "Not used" 6 "Not used" 7 "Not used";
VAL_ 1106 ARC_ACTIVATION_REQUEST 0 "ARC deactivation" 1 "ARC activation";
VAL_ 1106 FRONT_WASHING_STATE 0 "Stop" 1 "Washing";
VAL_ 1106 FA_ACTIVATION_REQUEST 0 "deactivation" 1 "activation";
VAL_ 1106 COCKPIT_GO_ACC_REQUEST 0 "VALUE_1" 1 "VALUE_2";
VAL_ 1106 ACC_PROGRAM 0 "Comfort" 1 "Sport" 2 "Eco" 3 "Reserved";
VAL_ 1160 START_IN_PROGRESS 0 "No start in progress" 1 "Start in progress";
VAL_ 1160 GLOW_PLUG_LAMP_REQUEST 0 "No lighting requested" 1 "Lighting requested";
VAL_ 1160 MALFUNCTION_INDICATOR_LAMP_REQUEST 0 "No lighting requested" 1 "Lighting requested";
VAL_ 1160 WATER_TEMPERATURE_ALERT 0 "No engine water temperature alert" 1 "Engine water temperature alert or faulty sensor";
VAL_ 1160 ADDITIVE_MIN_LEVEL_ALERT 0 "No additive min display request" 1 "Additive min display request";
VAL_ 1160 LEAN_MIXTURE_LAMP_REQUEST 0 "Correct mixture" 1 "Too lean mixture";
VAL_ 1160 RVV_LVV_FAULT 0 "No RVV fault / No LVV fault" 1 "RVV fault / LVV fault";
VAL_ 1160 STRONG_MISFIRES 0 "No strong misfires" 1 "Strong misfires in progress";
VAL_ 1160 AIR_CONDITIONING_CUTOFF 0 "OK no cutoff" 1 "Compressor cut off (risk of overheating)";
VAL_ 1160 AIR_CONDITIONING_MANAGEMENT_STATE 0 "OK" 1 "Low-pressure safety active" 2 "High-pressure safety active" 3 "Invalid";
VAL_ 1160 SERVICE_STOP_LAMP_REQUEST 0 "No request" 1 "Request" 2 "Reserved" 3 "Unavailable";
VAL_ 1160 GLOW_PLUG_PREPARATION 0 "No glow plug preparation needed" 1 "Preparation needed to activate glow plugs";
VAL_ 1160 FUEL_CONSUMPTION_INFO_TYPE 0 "Real consumption" 1 "Pseudo consumption";
VAL_ 1160 PARTICULATE_FILTER_CLOGGING_RISK 0 "No clogging risk display request" 1 "Driver prompting display for facilitating regeneration";
VAL_ 1160 GEARBOX_PRESSURE_INCREASE_REQUEST 0 "No pressure increase request" 1 "Pressure increase request";
VAL_ 1166 MEAP_2_ACTUAL_POSITION 0 "Unavailable" 1 "Position 0" 2 "Position 1" 3 "Position 2" 4 "Position 3" 5 "Position 4" 6 "Position 5" 7 "Position 6" 8 "Position 7" 9 "Position 8" 10 "Position 9" 11 "Position 10" 12 "Not used" 13 "Not used" 14 "Not used" 15 "Unknown position";
VAL_ 1166 MEAP_2_STATE 0 "Unavailable" 1 "MEAP no movement" 2 "MEAP in motion" 3 "MEAP referencing" 4 "Not used" 5 "Not used" 6 "Not used" 7 "MEAP faulty";
VAL_ 1261 OBD_ESP_PRESS_SENSOR_FAULT 0 "no fault" 1 "fault present";
VAL_ 1261 OBD_ESP_TRICAPT_COMM_FAULT 0 "no fault" 1 "fault present";
VAL_ 1261 OBD_ESP_CMM_FAULT 0 "no fault" 1 "fault present";
VAL_ 1261 OBD_ESP_PTMU_FAULT 0 "no fault" 1 "fault present";
VAL_ 1261 OBD_ESP_STEERING_WHEEL_SENSOR_COMM_FAULT 0 "no fault" 1 "fault present";
VAL_ 1261 OBD_ESP_VALVE_FAULT 0 "no fault" 1 "fault present";
VAL_ 1261 OBD_ESP_PUMP_FAULT 0 "no fault" 1 "fault present";
VAL_ 1261 OBD_ESP_MASTERVAC_SENSOR_FAULT 0 "no fault" 1 "fault present";
VAL_ 1261 OBD_ESP_VACUUM_PUMP_SENSOR_FAULT 0 "no fault" 1 "fault present";
VAL_ 1261 OBD_ESP_LEFT_FRONT_VALVE_RELAY_FAULT 0 "no fault" 1 "fault present";
VAL_ 1261 OBD_ESP_RIGHT_FRONT_VALVE_RELAY_FAULT 0 "no fault" 1 "fault present";
VAL_ 1261 OBD_ESP_LEFT_REAR_VALVE_RELAY_FAULT 0 "no fault" 1 "fault present";
VAL_ 1261 OBD_ESP_RIGHT_REAR_VALVE_RELAY_FAULT 0 "no fault" 1 "fault present";
VAL_ 1261 OBD_ESP_WHEEL_SPEED_SENSOR_FAULT 0 "no fault" 1 "fault present";
VAL_ 1261 OBD_ESP_BRAKE_SWITCH_FAULT 0 "no fault" 1 "fault present";
VAL_ 1261 OBD_ESP_CAN_IS_FAULT 0 "no fault" 1 "fault present";
VAL_ 1261 OBD_ESP_CAN_LAS_FAULT 0 "no fault" 1 "fault present";
VAL_ 1261 OBD_ESP_INTERNAL_ERROR 0 "no fault" 1 "fault present";
VAL_ 1261 OBD_ESP_OVERVOLTAGE 0 "no fault" 1 "fault present";
VAL_ 1261 OBD_ESP_PARAMETER_CODING_FAULT 0 "no fault" 1 "fault present";
VAL_ 1261 OBD_ESP_MASTER_CYLINDER_SENSOR_FAULT 0 "no fault" 1 "fault present";
VAL_ 1261 YAW_RATE_SENSOR_FAULT_RB 0 "No fault" 1 "Yaw rate sensor fault";
VAL_ 1261 LATERAL_ACCEL_SENSOR_FAULT_RB 0 "No fault" 1 "Lateral acceleration sensor fault";
VAL_ 1261 OBD_ESP_INERTIAL_SENSOR_FAULT 0 "no fault" 1 "fault present";
VAL_ 1261 OBD_ESP_STEERING_WHEEL_SENSOR_FAULT 0 "no fault" 1 "fault present";
VAL_ 1261 DIAGNOSTIC_VACUUM_FAILURE_ACTIV 0 "Diagnostic not activated" 1 "Diagnostic activated";
VAL_ 1261 DIAGNOSTIC_VACUUM_FAILURE 0 "No sustained failure detected" 1 "Sustained failure detected";
VAL_ 1266 SOC_ESTIMATION_STATUS 0 "Nominal SOC estimation" 1 "Degraded SOC estimation" 2 "Fault" 3 "SOC estimation not relevant";
VAL_ 1266 UCAP_CHARGE_AUTHORIZATION 0 "0A command" 1 "10A command" 2 "28A command" 3 "Reserved";
VAL_ 1266 BATTERY_ESTIMATOR_TYPE 0 "None" 1 "Battery_state_estimator_wakeup" 2 "BECB" 3 "Reserved";
VAL_ 1266 THERMAL_CONDITION_ENGINE_SPEED_RAISE_REQUEST 0 "No request" 1 "Increase request";
VAL_ 1266 UB_POS_MEAP_ACT 0 "signal not refreshed" 1 "signal refreshed";
VAL_ 1266 MEAP_ACTUAL_POSITION 0 "MEAP forced open" 1 "MEAP open" 2 "MEAP closed" 3 "MEAP faulty";
VAL_ 1266 MIN_VOLTAGE_SEVERITY_ERROR 0 "Severity 2" 1 "Severity 3" 2 "Severity 4" 3 "Reserved";
VAL_ 1266 MAX_VOLTAGE_SEVERITY_ERROR 0 "Severity 2" 1 "Severity 3" 2 "Severity 4" 3 "Reserved";
VAL_ 1266 MEAP_REQUEST_AC 0 "No request" 1 "Request";
VAL_ 1270 ARTIV_SENSOR_STATE 0 "Initialization" 1 "Inactive" 2 "Active" 3 "Reduced visibility" 4 "Simulation" 5 "Learning" 6 "Free" 7 "Fault";
VAL_ 1270 DETECTED_TARGET 0 "initialization or no target detected" 1 "target detected";
VAL_ 1270 ARTIV_TARGET_CHANGE_INFO 0 "VALUE_1" 1 "VALUE_2";
VAL_ 1270 DIRECTION_OF_TRAFFIC 0 "right" 1 "left" 2 "reserved" 3 "undetermined";
VAL_ 1277 SCROLL_WHEEL_FAULT 0 "No fault" 1 "Coherence not diagnosed" 2 "Reserved" 3 "Fault";
VAL_ 1277 OVERFLOW_DOWN 0 "Down overflow inactive" 1 "Down overflow active";
VAL_ 1277 OVERFLOW_UP 0 "Up overflow inactive" 1 "Up overflow active";
VAL_ 1294 COMPRESSOR_ENGAGEMENT_STATUS 0 "Compressor disengaged" 1 "Compressor engaged";
VAL_ 1294 HABITACLE_STOP_AUTHORIZATION 0 "No stop authorization" 1 "Stop authorization";
VAL_ 1294 DEF_IDENT_HAB 0 "no fault" 1 "fault";
VAL_ 1294 MINI_GPL 0 "Level above minimum" 1 "Minimum level reached";
VAL_ 1294 CHKSUM_CONS_RVV_LVV 0 "High nibble of CONS_LIM_VITESSE_VEH even & low nibble even" 1 "High nibble even & low nibble odd" 2 "High nibble odd & low nibble even" 3 "High nibble odd & low nibble odd";
VAL_ 1294 GMV_COMMAND 0 "No command" 1 "Small speed fan command" 2 "Medium speed fan command" 3 "High speed fan command";
VAL_ 1294 GLOW_PLUG_FORCING_AUTHORIZED 0 "Forcing not authorized" 1 "Glow plug forcing authorized";
VAL_ 1294 SEV_SHEDDING_REQUEST 0 "No shedding request" 1 "Shedding request";
VAL_ 1294 HABITACLE_RESTART_REQUEST 0 "No restart needed" 1 "Restart requested";
VAL_ 1294 HABITACLE_ENGINE_REQUEST 0 "no request" 1 "stop request" 2 "restart request" 3 "immediate restart request";
VAL_ 1294 DRIVER_PRESENCE_COND 0 "Forbidden value" 1 "Driver absent" 2 "Driver present" 3 "Forbidden value";
VAL_ 1294 HABITACLE_STOP_INHIBITION 0 "indefinite stop prohibition" 1 "stop authorization" 2 "medium duration stop prohibition" 3 "long duration stop prohibition";
VAL_ 1294 HABITACLE_REQUEST_SG 0 "No specific request (remain in current state)" 1 "Requires ICE rotation";
VAL_ 1294 LVV_ACTIVATION_REQUEST 0 "No LVV activation request" 1 "LVV activation request";
VAL_ 1294 LONGITUDINAL_REGULATION_TYPE 0 "None" 1 "RVV: vehicle speed regulator" 2 "LVV: vehicle speed limiter" 3 "ACC: automatic vehicle speed regulator";
VAL_ 1294 RVV_ACC_ACTIVATION_REQUEST 0 "No RVV or ACC activation request" 1 "RVV or ACC activation request";
VAL_ 1330 AVN_OP_CTRL 0 "OFF" 1 "ON";
VAL_ 1330 AVN_OBJ_DET_CTRL 0 "DETECT_OFF" 1 "DETECT_ON";
VAL_ 1356 AVN_STATE 0 "OFF" 1 "INIT" 2 "DET_ON" 3 "DET_OFF" 4 "FAULT" 5 "ALIGN" 6 "RESERVED" 7 "RESERVED";
VAL_ 1356 AVN_PEDESTRIAN_STATE 0 "OFF" 1 "ON";
VAL_ 1356 AVN_DETECT_ANIMAL 0 "NO_ANIMAL" 1 "ANIMAL_STILL_CONE" 2 "ANIMAL_MVT_CONE" 3 "UNAVAILABLE";
VAL_ 1356 AVN_DETECT_PEDESTRIAN 0 "NO_PEDESTRIAN" 1 "PEDESTRIAN_CORIDOR" 2 "PEDESTRIAN_CORNER" 3 "UNAVAILABLE";
VAL_ 1375 DATA_ACQ_JDD_BSI_2 1 "Used to identify the MUX station code" 2 "Used to identify the MUX station code" 4 "Used to identify the MUX station code" 16 "Used to identify the MUX station code" 32 "Used to identify the MUX station code" 64 "Used to identify the MUX station code" 128 "Used to identify the MUX station code";
VAL_ 1389 ACTIV_INFO_TRICPTR_RB 0 "No sensor info request" 1 "Sensor info request";
VAL_ 1389 PTR_INFO_TRICPT_RB 0 "Serial number" 1 "Customer part number" 2 "Bosch part number" 3 "Vehicle modification index" 4 "Sensor software version" 5 "Sensor software identification" 6 "Sensor hardware version" 7 "Manufacture date" 8 "Bosch modification index" 9 "Manufacturer name" 10 "Manufacturer process index" 11 "Reserved" 12 "Reserved" 13 "Reserved" 14 "Reserved" 15 "Send all valid info blocks (0000 to 1010)";
VAL_ 1389 INCR_SENSOR_COUNTER_REQUEST_RB 0 "No internal sensor counter increment request" 1 "Internal sensor counter increment request";
VAL_ 1393 VEH_SON_ALERT_DIAG_FAULT 0 "No fault" 1 "Fault";
VAL_ 1393 VEH_SON_ALERT_INHIBITED 0 "Not inhibited" 1 "Inhibited";
VAL_ 1400 BRAKE_ASSIST_LAMP_REQ 0 "No lighting request" 1 "Fault lamp lighting request";
VAL_ 1400 POWERTRAIN_DYNAMIC_STATE 0 "Normal" 1 "Sport" 2 "Eco" 3 "Snow" 4 "Invalid" 5 "Reserved" 6 "Reserved" 7 "Reserved";
VAL_ 1400 MEAP_2_COMMAND 0 "Unavailable" 1 "Position 0" 2 "Position 1" 3 "Position 2" 4 "Position 3" 5 "Position 4" 6 "Position 5" 7 "Position 6" 8 "Position 7" 9 "Position 8" 10 "Position 9" 11 "Position 10" 12 "Not used" 13 "Not used" 14 "Referencing" 15 "Motion stopped";
VAL_ 1400 CMM_OPEN_SOLENOID_REQ 0 "No request" 1 "Open request";
VAL_ 1401 PTR_INFO_TRICPT_RB 0 "Serial number" 1 "Customer part number" 2 "Bosch part number" 3 "Vehicle modification index" 4 "Sensor software version" 5 "Sensor software identification" 6 "Sensor hardware version" 7 "Manufacture date" 8 "Bosch modification index" 9 "Manufacturer name" 10 "Manufacturer process index" 11 "Reserved" 12 "Reserved" 13 "Reserved" 14 "Reserved" 15 "Send all valid info blocks (0000 to 1010)";
VAL_ 1401 RB_SENSOR_TYPE 0 "Reserved" 1 "MM 3.7K" 2 "MM 3.8K" 3 "Reserved" 4 "Reserved" 5 "Reserved" 6 "Reserved" 7 "Reserved" 8 "Reserved" 9 "Reserved" 10 "Reserved" 11 "Reserved" 12 "Reserved" 13 "Reserved" 14 "Reserved" 15 "Reserved";
VAL_ 1426 PARKING_BRAKE_MODE 0 "Parking brake in automatic mode" 1 "Parking brake in manual mode";
VAL_ 1426 COMMUT_SYSTEM_FAULT 0 "No fault detected" 1 "Fault detected";
VAL_ 1426 WIPING_STATE 0 "Stop" 1 "Reserved" 2 "Low speed" 3 "High speed";
VAL_ 1426 HDC_FRONT_WIPER_COMMAND 0 "No command" 1 "Automatic (with CDPL) or intermittent" 2 "First speed (low speed)" 3 "invalid" 4 "Second speed (high speed)" 5 "invalid" 6 "invalid" 7 "invalid";
VAL_ 1426 CLIMATE_PUMP_AERO_HYB_REQUEST 0 "Inactive" 1 "Active";
VAL_ 1426 ALTERNATOR_CONTROL_TYPE 0 "Autonomous control" 1 "Nominal" 2 "Increased energy production" 3 "Constrained autonomous control" 4 "reserved" 5 "reserved" 6 "Unavailable" 7 "Invalid";
VAL_ 1426 ARTIV_DETECTION_REQUEST 0 "Initialization or detection not requested" 1 "Detection requested" 2 "Simulation" 3 "Invalid";
VAL_ 1426 IBATT_RANGE 0 "[-1A ; +1A]" 1 "[-200A";
VAL_ 1426 DSGI_RESET_REQUEST 0 "No reset requested" 1 "Reset requested";
VAL_ 1426 STT_STATE_CHANGE_REQUEST 0 "Reserved" 1 "No request" 2 "Request" 3 "Fault";
VAL_ 1426 CLIMATE_AIRFLOW_REQUEST 0 "No cabin heating need" 1 "Low cabin heating need" 2 "Moderate cabin heating need" 3 "High cabin heating need";
VAL_ 1448 VACUUM_OPTIMIZATION_BV 0 "0b0: Not enabled" 1 "0b1: Enabled";
VAL_ 1448 SCR_DIAG_STATE 0 "SCR system operational" 1 "SCR system failing Confirmation" 2 "SCR system failing Threshold" 3 "SCR system failing 0";
VAL_ 1448 UREA_LEVEL_ALERT 0 "High level" 1 "Low level threshold1" 2 "Low level threshold2" 3 "Low level threshold3" 4 "Empty level" 5 "reserved" 6 "reserved" 7 "reserved";
VAL_ 1448 PWT_EMISSION_MODE_REQUEST 0 "Nominal" 1 "Prioritize NOx reduction at source (init mode) / O2 richness (Gasoline)" 2 "Prioritize exhaust flow" 3 "Prioritize exhaust heat" 4 "reserved" 5 "reserved" 6 "reserved" 7 "reserved";
VAL_ 1464 GLOBAL_ECOACH_TRIP_SCORE 0 "Score 0" 1 "Score 1" 2 "Score 2" 3 "Score 3" 4 "Score 4" 5 "Score 5" 6 "Score 6" 7 "Score 7" 8 "Score 8" 9 "Score 9" 10 "Score 10" 11 "not used" 12 "not used" 13 "not used" 14 "Score unavailable" 15 "Invalid";
VAL_ 1464 GLOBAL_ECOACH_DAY_SCORE 0 "Score 0" 1 "Score 1" 2 "Score 2" 3 "Score 3" 4 "Score 4" 5 "Score 5" 6 "Score 6" 7 "Score 7" 8 "Score 8" 9 "Score 9" 10 "Score 10" 11 "not used" 12 "not used" 13 "not used" 14 "Score unavailable" 15 "Invalid";
VAL_ 1464 ECOACH_BRAKE_SCORE 0 "Score 0" 1 "Score 1" 2 "Score 2" 3 "Score 3" 4 "Score 4" 5 "Score 5" 6 "Score 6" 7 "Score 7" 8 "Score 8" 9 "Score 9" 10 "Score 10" 11 "not used" 12 "not used" 13 "not used" 14 "Score unavailable" 15 "Invalid";
VAL_ 1464 ECOACH_ACCEL_SCORE 0 "Score 0" 1 "Score 1" 2 "Score 2" 3 "Score 3" 4 "Score 4" 5 "Score 5" 6 "Score 6" 7 "Score 7" 8 "Score 8" 9 "Score 9" 10 "Score 10" 11 "not used" 12 "not used" 13 "not used" 14 "Score unavailable" 15 "Invalid";
VAL_ 1464 ECOACH_DSG_SCORE 0 "Score 0" 1 "Score 1" 2 "Score 2" 3 "Score 3" 4 "Score 4" 5 "Score 5" 6 "Score 6" 7 "Score 7" 8 "Score 8" 9 "Score 9" 10 "Score 10" 11 "not used" 12 "not used" 13 "not used" 14 "Score unavailable" 15 "Invalid";
VAL_ 1464 ECOACH_CLIM_SCORE 0 "Score 0" 1 "Score 1" 2 "Score 2" 3 "Score 3" 4 "Score 4" 5 "Score 5" 6 "Score 6" 7 "Score 7" 8 "Score 8" 9 "Score 9" 10 "Score 10" 11 "not used" 12 "not used" 13 "not used" 14 "Score unavailable" 15 "Invalid";
VAL_ 1464 ECOACH_COLD_ENGINE_SCORE 0 "Score 0" 1 "Score 1" 2 "Score 2" 3 "Score 3" 4 "Score 4" 5 "Score 5" 6 "Score 6" 7 "Score 7" 8 "Score 8" 9 "Score 9" 10 "Score 10" 11 "not used" 12 "not used" 13 "not used" 14 "Score unavailable" 15 "Invalid";
VAL_ 1464 ECOACH_GSI_SCORE 0 "Score 0" 1 "Score 1" 2 "Score 2" 3 "Score 3" 4 "Score 4" 5 "Score 5" 6 "Score 6" 7 "Score 7" 8 "Score 8" 9 "Score 9" 10 "Score 10" 11 "not used" 12 "not used" 13 "not used" 14 "Score unavailable" 15 "Invalid";
VAL_ 1464 ECOACH_SLOPE_SCORE 0 "Score 0" 1 "Score 1" 2 "Score 2" 3 "Score 3" 4 "Score 4" 5 "Score 5" 6 "Score 6" 7 "Score 7" 8 "Score 8" 9 "Score 9" 10 "Score 10" 11 "not used" 12 "not used" 13 "not used" 14 "Score unavailable" 15 "Invalid";
VAL_ 1464 ECOACH_STT_SCORE 0 "Score 0" 1 "Score 1" 2 "Score 2" 3 "Score 3" 4 "Score 4" 5 "Score 5" 6 "Score 6" 7 "Score 7" 8 "Score 8" 9 "Score 9" 10 "Score 10" 11 "not used" 12 "not used" 13 "not used" 14 "Score unavailable" 15 "Invalid";
VAL_ 1464 ECOACH_SPEED_SCORE 0 "Score 0" 1 "Score 1" 2 "Score 2" 3 "Score 3" 4 "Score 4" 5 "Score 5" 6 "Score 6" 7 "Score 7" 8 "Score 8" 9 "Score 9" 10 "Score 10" 11 "not used" 12 "not used" 13 "not used" 14 "Score unavailable" 15 "Invalid";
VAL_ 1484 FAULT_CODE 0 "no fault present" 1 "One or more faults present. Each bit indicates a fault code";
VAL_ 1484 PARTIAL_WAKEUP_STATUS_GMP 0 "Initialization value" 1 "GEP gearbox preparation status" 2 "Stop & Start preparation status with AR2S (type C3)" 4 "Ucaps charge/discharge status" 8 "Overload vehicle indicator status" 16 "Mecatronic headlamp status" 32 "Reserved" 64 "Anticipation ADC status" 128 "Engine start preparation status" 256 "Reserved" 512 "Gearbox status request" 1024 "Reserved" 2048 "SCR purge status" 4096 "Flex Start status" 8192 "Power-latch HY status" 16384 "Engine oil measurement status" 32768 "Engine post-ventilation status";
VAL_ 1484 UCE_ELECTRICAL_STATE 0 "Standby (theoretically never reached)" 1 "Partial or ComLatch" 2 "Partial internal (theoretically not used)" 3 "Transitory" 4 "Main" 5 "Main degraded" 6 "Init / Sleeping" 7 "Default value (no function)" 8 "Pre/Post Main" 9 "Reserved" 10 "Reserved" 11 "Reserved" 12 "Reserved" 13 "Reserved" 14 "Reserved" 15 "Reserved";
VAL_ 1489 FAULT_CODE 0 "no fault present" 1 "One or more faults present. Each bit indicates a fault code";
VAL_ 1489 PARTIAL_WAKEUP_STATUS_LAS 0 "Initialization value" 1 "Height correction wake-up status" 2 "Manual CAAR function wake-up status" 4 "Height CAAR status request by FSE" 8 "Easymove function wake-up by FSE" 16 "Vehicle speed wake-up by BSI" 32 "Display wake-up by FSE" 64 "FSE status request" 128 "Short partial wake-up 1 after main wake-up";
VAL_ 1489 UCE_ELECTRICAL_STATE 0 "Standby (theoretically never reached)" 1 "Partial or ComLatch" 2 "Partial internal (theoretically not used)" 3 "Transitory" 4 "Main" 5 "Main degraded" 6 "Init / Sleeping" 7 "Default value (no function)" 8 "Pre/Post Main" 9 "Reserved" 10 "Reserved" 11 "Reserved" 12 "Reserved" 13 "Reserved" 14 "Reserved" 15 "Reserved";
VAL_ 1490 CLIMATE_WATER_HEATING_REQUEST 0 "No request" 1 "Level 1 request" 2 "Level 2 request" 3 "Level 3 request";
VAL_ 1490 AUX_BT_POWER_REQUEST 0 "Level 0" 1 "Level 1" 2 "Level 2" 3 "Level 3" 4 "Level 4" 5 "Level 5" 6 "Level 6" 7 "Level 7" 8 "Level 8" 9 "Level 9" 10 "Level 10" 11 "Level 11" 12 "Level 12" 13 "Level 13" 14 "Level 14" 15 "Level 15";
VAL_ 1490 RESET_ECOACH_DAY 0 "no reset request" 1 "reset request";
VAL_ 1490 RESET_ECOACH_TRIP 0 "no reset request" 1 "reset request";
VAL_ 1490 REVERSE_GEAR_STATE 0 "Reverse not engaged" 1 "Reverse engaged";
VAL_ 1490 VEHICLE_SOUND_ALERT_COMMAND 0 "Not enabled" 1 "Enabled";
VAL_ 1496 KM_MARKETING_ETD_ACTIF 0 "Use SEUIL_KM_MARKETING" 1 "Use SEUIL_KM_MARKETING_ETD";
VAL_ 1516 FRAME_NUMBER 0 "Reserved" 1 "Frame number 1" 2 "Frame number 2" 3 "Frame number 3";
VAL_ 1516 MESSAGE_TYPE 0 "ECU extended AEE2004" 1 "ECU responding to AEE2010";
VAL_ 1516 DTC_STATUS 0 "Transition from PERMANENT to FUGITIVE fault (previously confirmed fault not detected anymore)" 1 "Transition to PERMANENT fault";
VAL_ 1516 NUMBER_OF_FRAMES 0 "Reserved" 1 "One frame" 2 "Two frames" 3 "Three frames";
VAL_ 1517 ICB_STATE 0 "0b0: N0_FAULT" 1 "0b1: FAULT";
VAL_ 1517 REAR_LEFT_WHEEL_UNDERINFLATION_STATE 0 "Reserved" 1 "Underinflated wheel" 2 "Reserved" 3 "Reserved" 4 "Unknown wheel status" 5 "Reserved" 6 "Reserved" 7 "Normal wheel status";
VAL_ 1517 REAR_RIGHT_WHEEL_UNDERINFLATION_STATE 0 "Reserved" 1 "Underinflated wheel" 2 "Reserved" 3 "Reserved" 4 "Unknown wheel status" 5 "Reserved" 6 "Reserved" 7 "Normal wheel status";
VAL_ 1517 FRONT_LEFT_WHEEL_UNDERINFLATION_STATE 0 "Reserved" 1 "Underinflated wheel" 2 "Reserved" 3 "Reserved" 4 "Unknown wheel status" 5 "Reserved" 6 "Reserved" 7 "Normal wheel status";
VAL_ 1517 FRONT_RIGHT_WHEEL_UNDERINFLATION_STATE 0 "Reserved" 1 "Underinflated wheel" 2 "Reserved" 3 "Reserved" 4 "Unknown wheel status" 5 "Reserved" 6 "Reserved" 7 "Normal wheel status";
VAL_ 1517 SMALL_SPARE_WHEEL_DETECTION 0 "No 'small spare wheel' detected" 1 "'small spare wheel' detected";
VAL_ 1517 DSG_INDICATOR_STATE 0 "Reserved" 1 "DSG faulty" 2 "Underinflated wheel(s)" 3 "Reserved" 4 "Reinit acknowledgment" 5 "Reserved" 6 "Reserved" 7 "DSG OK";
VAL_ 1518 SOLENOID_BLOCKED 0 "No fault" 1 "Fault";
VAL_ 1519 FRAME_NUMBER 0 "Reserved" 1 "Frame number 1" 2 "Frame number 2" 3 "Frame number 3";
VAL_ 1519 MESSAGE_TYPE 0 "ECU extended AEE2004" 1 "ECU responding to AEE2010";
VAL_ 1519 DTC_STATUS 0 "Transition from PERMANENT to FUGITIVE fault (previously confirmed fault not detected anymore)" 1 "Transition to PERMANENT fault";
VAL_ 1519 NUMBER_OF_FRAMES 0 "Reserved" 1 "One frame" 2 "Two frames" 3 "Three frames";
VAL_ 1520 FAULT_CODE 0 "no fault present" 1 "One or more faults present. Each bit indicates a fault code";
VAL_ 1520 PARTIAL_WAKEUP_STATUS_LAS 0 "Initialization value" 1 "Height correction wake-up status" 2 "Manual CAAR function wake-up status" 4 "Height CAAR status request by FSE" 8 "Easymove function wake-up by FSE" 16 "Vehicle speed wake-up by BSI" 32 "Display wake-up by FSE" 64 "FSE status request" 128 "Short partial wake-up 1 after main wake-up";
VAL_ 1520 UCE_ELECTRICAL_STATE 0 "Standby (theoretically never reached)" 1 "Partial or ComLatch" 2 "Partial internal (theoretically not used)" 3 "Transitory" 4 "Main" 5 "Main degraded" 6 "Init / Sleeping" 7 "Default value (no function)" 8 "Pre/Post Main" 9 "Reserved" 10 "Reserved" 11 "Reserved" 12 "Reserved" 13 "Reserved" 14 "Reserved" 15 "Reserved";
VAL_ 1521 FRAME_NUMBER 0 "Reserved" 1 "Frame number 1" 2 "Frame number 2" 3 "Frame number 3";
VAL_ 1521 MESSAGE_TYPE 0 "ECU extended AEE2004" 1 "ECU responding to AEE2010";
VAL_ 1521 DTC_STATUS 0 "Transition from PERMANENT to FUGITIVE fault (previously confirmed fault not detected anymore)" 1 "Transition to PERMANENT fault";
VAL_ 1521 NUMBER_OF_FRAMES 0 "Reserved" 1 "One frame" 2 "Two frames" 3 "Three frames";
VAL_ 1554 DYNAMIC_CORNER_LIGHTING_INHIBITION 0 "No inhibition" 1 "Inhibition";
VAL_ 1554 HIGHWAY_LIGHTING_INHIBITION 0 "No inhibition" 1 "Inhibition";
VAL_ 1554 DAYTIME_LIGHTING_INHIBITION 0 "No inhibition" 1 "Inhibition";
VAL_ 1554 LOW_BEAM_STATE 0 "Off" 1 "On";
VAL_ 1554 HIGH_BEAM_STATE 0 "Off" 1 "On";
VAL_ 1554 VEHICLE_CONFIGURATION_MODE 0 "Plant" 1 "Show room" 2 "Customer" 3 "Reserved";
VAL_ 1554 TURN_SIGNAL_COMMAND 0 "No command" 1 "Left turn signal" 2 "Right turn signal" 3 "Not valid";
VAL_ 1554 ECO_MODE 0 "Initialization value" 1 "No ECO mode" 2 "ECO mode requested" 3 "Invalid";
VAL_ 1554 ASR_PLUS_SELECTED_MODE 0 "Normal mode" 1 "Snow mode" 2 "Mud mode" 3 "Sand mode";
VAL_ 1554 LEFT_HIGH_BEAM_FAULT 0 "No fault" 1 "Fault";
VAL_ 1554 RIGHT_HIGH_BEAM_FAULT 0 "No fault" 1 "Fault";
VAL_ 1554 LEFT_LOW_BEAM_FAULT 0 "No fault" 1 "Fault";
VAL_ 1554 RIGHT_LOW_BEAM_FAULT 0 "No fault" 1 "Fault";
VAL_ 1554 MOBILE_DEFLECTOR_POSITION 0 "Undetermined" 1 "In position 0" 2 "Reserved" 3 "In position 1" 4 "Reserved" 5 "In position 2" 6 "Maintenance position" 7 "Reserved";
VAL_ 1554 OLVI_REAR_ACTUATION_REQUEST 0 "No request" 1 "Request";
VAL_ 1554 UB_D_LIGNE_REL_RX 0 "No change" 1 "Change on at least one signal";
VAL_ 1554 RELAY_LINE_R2_DIAGNOSTIC 0 "Undetermined" 1 "No fault / Relay command inactive" 2 "No fault / Relay command active" 3 "Short to ground" 4 "Short to +BAT" 5 "Open circuit" 6 "Unidentified fault" 7 "Not used";
VAL_ 1554 RELAY_LINE_R1_DIAGNOSTIC 0 "Undetermined" 1 "No fault / Relay command inactive" 2 "No fault / Relay command active" 3 "Short to ground" 4 "Short to +BAT" 5 "Open circuit" 6 "Unidentified fault" 7 "Not used";
VAL_ 1554 VEHICLE_CONFIGURATION 0 "Fitting" 1 "Plant" 2 "Check" 3 "Storage/Transport" 4 "Customer" 5 "APV" 6 "Show room" 7 "Invalid";
VAL_ 1554 RELAY_LINE_R3_DIAGNOSTIC 0 "Undetermined" 1 "No fault / Relay command inactive" 2 "No fault / Relay command active" 3 "Short to ground" 4 "Short to +BAT" 5 "Open circuit" 6 "Unidentified fault" 7 "Not used";
VAL_ 1910 FRAME_NUMBER 0 "Reserved" 1 "Frame number 1" 2 "Frame number 2" 3 "Frame number 3";
VAL_ 1910 MESSAGE_TYPE 0 "ECU extended AEE2004" 1 "ECU responding to AEE2010";
VAL_ 1910 DTC_STATUS 0 "Transition from PERMANENT to FUGITIVE fault (previously confirmed fault not detected anymore)" 1 "Transition to PERMANENT fault";
VAL_ 1910 NUMBER_OF_FRAMES 0 "Reserved" 1 "One frame" 2 "Two frames" 3 "Three frames";
VAL_ 1917 FRAME_NUMBER 0 "Reserved" 1 "Frame number 1" 2 "Frame number 2" 3 "Frame number 3";
VAL_ 1917 MESSAGE_TYPE 0 "ECU extended AEE2004" 1 "ECU responding to AEE2010";
VAL_ 1917 DTC_STATUS 0 "Transition from PERMANENT to FUGITIVE fault (previously confirmed fault not detected anymore)" 1 "Transition to PERMANENT fault";
VAL_ 1917 NUMBER_OF_FRAMES 0 "Reserved" 1 "One frame" 2 "Two frames" 3 "Three frames";
VAL_ 1938 FAULT_CODE 0 "no fault present" 1 "One or more faults present. Each bit indicates a fault code";
VAL_ 1938 PARTIAL_WAKEUP_STATUS 0 "Initialization value" 1 "GEP preparation status" 2 "Stop & Start preparation status" 4 "Manual CAAR function" 8 "Pneumatic height correction" 16 "Vehicle speed wake-up by BSI" 32 "Vehicle speed wake-up by FSE" 64 "Anticipation ADC" 128 "Engine start preparation" 256 "Cabin preconditioning" 512 "Gearbox status request" 1024 "Height correction" 2048 "FSE status request" 4096 "FSE status display" 8192 "PLIP reception wake-up" 16384 "Engine oil measurement" 32768 "Engine post ventilation";
VAL_ 1938 UCE_ELECTRICAL_STATE 0 "Standby (theoretically never reached)" 1 "Partial or ComLatch" 2 "Partial internal (theoretically not used)" 3 "Transitory" 4 "Main" 5 "Main degraded" 6 "Init / Sleeping" 7 "Default value (no function)" 8 "Pre/Post Main" 9 "Reserved" 10 "Reserved" 11 "Reserved" 12 "Reserved" 13 "Reserved" 14 "Reserved" 15 "Reserved";
VAL_ 1938 RCD_LINE_STATE 0 "RCD line low" 1 "RCD line high";
VAL_ 1942 FAULT_CODE 0 "no fault present" 1 "One or more faults present. Each bit indicates a fault code";
VAL_ 1942 PARTIAL_WAKEUP_STATUS_GMP 0 "Initialization value" 1 "GEP gearbox preparation status" 2 "Stop & Start preparation status with AR2S (type C3)" 4 "Ucaps charge/discharge status" 8 "Overload vehicle indicator" 16 "Mecatronic headlamp" 32 "Reserved" 64 "Anticipation ADC" 128 "Engine start preparation" 256 "Reserved" 512 "Gearbox status request" 1024 "Reserved" 2048 "SCR purge" 4096 "Flex Start" 8192 "Power-latch HY" 16384 "Engine oil measurement" 32768 "Engine post ventilation";
VAL_ 1942 UCE_ELECTRICAL_STATE 0 "Standby (theoretically never reached)" 1 "Partial or ComLatch" 2 "Partial internal (theoretically not used)" 3 "Transitory" 4 "Main" 5 "Main degraded" 6 "Init / Sleeping" 7 "Default value (no function)" 8 "Pre/Post Main" 9 "Reserved" 10 "Reserved" 11 "Reserved" 12 "Reserved" 13 "Reserved" 14 "Reserved" 15 "Reserved";
VAL_ 1949 FAULT_CODE 0 "no fault present" 1 "One or more faults present. Each bit indicates a fault code";
VAL_ 1949 UCE_ELECTRICAL_STATE 0 "Standby (theoretically never reached)" 1 "Partial or ComLatch" 2 "Partial internal (theoretically not used)" 3 "Transitory" 4 "Main" 5 "Main degraded" 6 "Init / Sleeping" 7 "Default value (no function)" 8 "Pre/Post Main" 9 "Reserved" 10 "Reserved" 11 "Reserved" 12 "Reserved" 13 "Reserved" 14 "Reserved" 15 "Reserved";
; #############################################################################
; ############################### EPS VAL #####################################
; #############################################################################
VAL_ 1485 ACQ_INTERRUPT_DAE 1 "Acknowledge" 0 "No Acknowledge" ;
VAL_ 1485 PRECISION_OFFSET 31 "Invalid" 30 "Unavailable" ;
VAL_ 1485 OFFSET 32766 "Unavailable" 32767 "Invalid" ;
VAL_ 1394 VEHICLE_CONFIGURATION 7 "INVALID" 6 "SHOW_ROOM" 5 "APV" 4 "CLIENT" 3 "STORAGE / TRANSPORT" 2 "CHECK" 1 "PLANT" 0 "FITTING" ;
VAL_ 1293 ANTILOCK_BRAKE_REGULATION 1 "Active Regulation" 0 "No Regulation" ;
VAL_ 1909 DTC_State 1 "Current" 0 "History" ;
VAL_ 1010 LXA_ACTIVATION 1 "LPA Function" 0 "LKA Function" ;
VAL_ 1010 LKA_TRQ_FACT_REQ 127 "Invalid" 126 "Unavailable" ;
VAL_ 1010 LKA_STATE 7 "Reserved" 6 "Collision" 5 "Defect" 4 "Active" 3 "Authorized" 2 "Selected" 1 "Unselected" 0 "Unavailable" ;
VAL_ 1010 DMD_DELEST_DA 1 "Power Cut Request" 0 "Not Requested" ;
VAL_ 146 ELECTRICAL_INTEGRITY_DIAGNOSTIC_STATUS 1 "No frame transmission" 0 "No particular operation" ;
VAL_ 146 DIAGNOSTIC_OPERATION_MODE 1 "Operation and Comm Inhibited" 0 "No particular operation" ;
VAL_ 146 ERASE_DIAGNOSTIC_FAULT 1 "Erase fault memory" 0 "No specific action" ;
VAL_ 773 STEERING_ANGLE_MEMORY_FLAG 1 "Steering Wheel Angle Memorized" 0 "Steering Wheel Angle Available" ;
VAL_ 773 STEERING_ANGLE_VALIDITY 1 "Uncertain yet Valid Value" 0 "Valid Value in Range" ;
VAL_ 773 STEERING_ANGLE_ORIGIN 3 "Other" 2 "CAV3" 1 "Integrated CAV3" 0 "Estimator" ;
VAL_ 773 OPTIMIZED_STEERING_ROT_SPEED 255 "Invalid" ;
VAL_ 773 STEERING_SENSOR_FAULT_CODE 4 "Internal Failures by SWS " 3 "Failure on SWS Angle, RotSpeed " 2 "Failure on SWS Angle" 1 "Failure on SWS Rotation Speed " 0 "No Default / Failure" ;
VAL_ 773 STEERING_TRIM 1 "Trimmed" 0 "Not Trimmed" ;
VAL_ 773 STEERING_CALIBRATION 1 "Calibrated" 0 "Not Calibrated" ;
VAL_ 773 STEERING_SENSOR_STATUS 1 "Sensor Is Okay" 0 "Sensor Is Faulty" ;
VAL_ 773 STEERING_ROTATION_DIRECTION 1 "Clockwise" 0 "Counter Clockwise" ;
VAL_ 773 STEERING_ROTATION_SPEED 255 "Invalid" ;
VAL_ 773 STEERING_ANGLE 32767 "Invalid" ;
VAL_ 747 CPK_RELAX_REQUEST 3 "Invalid" 2 "Relax Request" 1 "No Request" 0 "Reserved" ;
VAL_ 747 CPK_FUNCTION_REQUEST 3 "Invalid" 2 "SCP9 Control Request" 1 "SCP6 Control Request" 0 "No Request" ;
VAL_ 747 CPK_TARGET_ANGLE 32767 "Invalid" ;
VAL_ 1074 ELECTRICAL_NETWORK_STATE 7 "TA_SECU" 6 "TA_DEGRADE" 5 "TA_NOMINAL" 4 "RESTARTING" 3 "STARTING" 2 "TI_DISPO_DEM" 1 "TI_Degrade" 0 "TI_Nominal" ;
VAL_ 1074 MAIN_SAFETY_STATE 2 "Start" 1 "Ignition on" 0 "Stop" ;
VAL_ 1941 APC_LINE_STATE 1 "Ignition On" 0 "Ignition Off" ;
VAL_ 1941 DA_ASSIST_STATE 7 "Disability Parameter" 4 "STTd Assist Active" 3 "STTa Assist Active" 2 "Dmg Assist Active" 1 "Nominal Assist Active" 0 "Assist Not Active" ;
VAL_ 1941 FAULT_CODE_INDICATOR 1 "Fault Code Exists" 0 "No Fault Code" ;
VAL_ 1173 EPS_TORQUE_LIMIT_STATE 1 "Saturation Effective" 0 "No Saturation" ;
VAL_ 1173 STEERING_WHEEL_HELD_BY_DRIVER 1 "Steer Activity From Driver Torque" 0 "No Steer Activity From Driver Torque" ;
VAL_ 1173 EPS_STATE_LKA 4 "Defect" 3 "Active" 2 "Available" 1 "Authorized" 0 "Unauthorized" ;
VAL_ 1173 DA_2004_STATUS 3 "Reserved" 2 "Orange LED" 1 "Red LED" 0 "No Request" ;
VAL_ 1173 DYNAMIC_DA_MODE 3 "Invalid" 2 "Adjustable Mode" 1 "Dynamic Mode" 0 "Normal Mode" ;
VAL_ 1173 DA_2010_STATUS 3 "Reserved" 2 "Orange LED" 1 "Red LED" 0 "No Request" ;
VAL_ 1173 EPS_REBOOT_REQUEST 1 "Reboot Request" 0 "No Reboot Required" ;
VAL_ 1173 EPS_STEERING_TORQUE 127 "Invalid" ;
VAL_ 1173 EPS_ENGINE_STOP_AUTHORIZATION 1 "Permission to Stop" 0 "No Permission to Stop" ;
VAL_ 757 VIRTUAL_CAV3_EPS_STATUS 7 "Invalid" 6 "Reserved" 5 "EPS With SelfDet Offset" 4 "EPS With Calibrated Offset" 3 "EPS With ESC Offset" 2 "Offset Search Authorization" 1 "Offset Initialization Request" 0 "Initialization" ;
VAL_ 757 COLUMN_ROTATION_SPEED 2047 "Invalid" ;
VAL_ 757 COLUMN_ANGLE_SECURITY 1 "Secure" 0 "Not Secure" ;
VAL_ 757 CPK_EPS_STATUS 3 "Invalid" 2 "Control In Progress" 1 "Available" 0 "Unavailable" ;
VAL_ 757 OPTIMIZED_STEERING_TORQUE 127 "Invalid" ;
VAL_ 757 CPK_DEACTIVATION_CAUSE 7 "Other Faults" 6 "EPS Thermal Safety" 5 "Excessive Maneuver Count" 4 "Wheel Obstacle" 3 "Angle Error Too High" 2 "Vehicle Speed Too High" 1 "Driver Hands On" 0 "No Interruption" ;
VAL_ 757 COLUMN_ANGLE 32767 "Invalid" ;
VAL_ 277 DOWNLOAD_MONTH 12 "December" 11 "November" 10 "October" 9 "September" 8 "August" 7 "July" 6 "June" 5 "May" 4 "April" 3 "March" 2 "February" 1 "January" ;
; #############################################################################
; ############################### EPS SIG_GROUP_ ##############################
; #############################################################################
SIG_GROUP_ 773 IS_DYN_VOL_GroupAdd 1 : FLG_INIT_AVOL FLG_AVOL_ICN ANGLE_VOLANT_ORIGINE RESERVED VITESSE_ROT_VOL_OPTIMISE CODE_DEFAUT_VOL TRIM_VOL CALIBRATION_VOL ETAT_CAPT_VOL;
SIG_GROUP_ 773 IS_DYN_VOL_GroupBase 1 : CHKSUM_VOL SENS_ROT_VOL CPT_PROCESS_4B_A_VOL VITESSE_ROT_VOL ANGLE_VOLANT;
SIG_GROUP_ 1941 IS_SUPV_DIRA_Group 1 : CODE_DEFAUT ETAT_ASSIST_DA ETAT_LIGNE_APC STATUS_CONFABSENT;
SIG_GROUP_ 1173 IS_DAT_DIRA_Group 1 : AUTOR_ARRET_MOT_DA CPLE_VOLANT DDE_REDEM_DA ETAT_DA_2010 ETAT_DA_DYN ETAT_DA_2004 EPS_STATE_LKA STEERWHL_HOLD_BY_DRV TRQ_LIMIT_STATE;
SIG_GROUP_ 757 IS_DYN_DAE_Group 1 : ANGLE_COLONNE CAUSE_DESACTIV_CPK CHKSUM_TRME_DYN_DAE CPLE_VOLANT_OPTMSE CPT_PROCESS_4B_DAE ETAT_DAE_CPK ETAT_SECU_ANGLE_COL VITESSE_COLONNE ETAT_DAE_CAV3_VIRTUEL;
